VERSION ""

NS_ :

BS_:

BU_: HCM IPMA_ADAS PSCM GWM _delete SCCM PDM DDM GENERIC TSTR

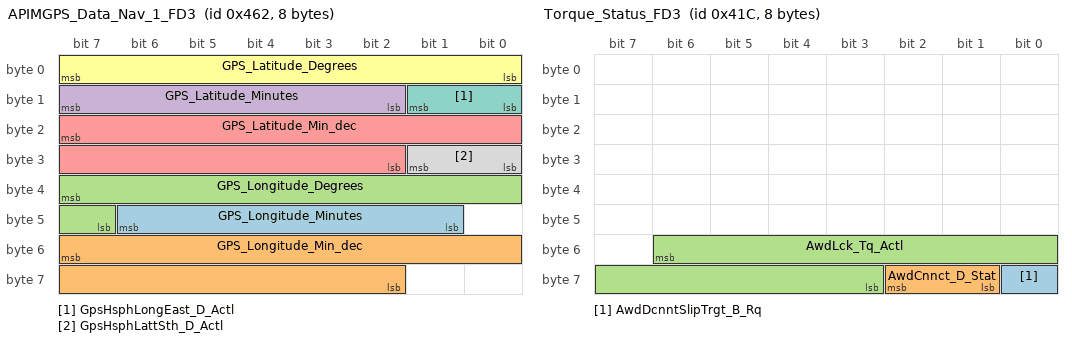
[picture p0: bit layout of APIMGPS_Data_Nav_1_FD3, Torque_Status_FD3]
BO_ 1122 APIMGPS_Data_Nav_1_FD3: 8 GWM
 SG_ GPS_Longitude_Minutes : 46|6@0+ (1,0) [0|61] "minute" Vector__XXX
 SG_ GPS_Longitude_Min_dec : 55|14@0+ (0.0001,0) [0|1.6381] "minute" Vector__XXX
 SG_ GPS_Longitude_Degrees : 39|9@0+ (1,-179) [-179|330] "degrees" Vector__XXX
 SG_ GPS_Latitude_Minutes : 15|6@0+ (1,0) [0|61] "minute" Vector__XXX
 SG_ GPS_Latitude_Min_dec : 23|14@0+ (0.0001,0) [0|1.6381] "minute" Vector__XXX
 SG_ GPS_Latitude_Degrees : 7|8@0+ (1,-89) [-89|164] "degrees" Vector__XXX
 SG_ GpsHsphLongEast_D_Actl : 9|2@0+ (1,0) [0|3] "SED" Vector__XXX
 SG_ GpsHsphLattSth_D_Actl : 25|2@0+ (1,0) [0|3] "SED" Vector__XXX

BO_ 2611175457 PARSEDPhysIPMAtoGWM_ECG: 64 IPMA_ADAS
 SG_ PARSEDPhysIPMAtoGWM_ECG : 7|29@0+ (1,0) [0|536870911] "unitless"  GWM

BO_ 2609933528 OTAPhysGWM_ECGtoGSM: 64 GWM
 SG_ OTAPhysGWM_ECGtoGSM : 7|29@0+ (1,0) [0|536870911] "unitless" Vector__XXX

BO_ 2611175492 PARSEDPhysSCCMtoGWM_ECG: 64 SCCM
 SG_ PARSEDPhysSCCMtoGWM_ECG : 7|29@0+ (1,0) [0|536870911] "unitless"  GWM

BO_ 1054 BrakeSysFeatures_3_FD3: 16 GWM
 SG_ RbaBrk_D_Stat : 63|2@0+ (1,0) [0|3] "SED"  IPMA_ADAS
 SG_ SelDrvMdeChassis2_D_Rq : 45|5@0+ (1,0) [0|31] "SED"  PSCM
 SG_ TrailCtl_D_Stat : 55|3@0+ (1,0) [0|7] "SED" Vector__XXX
 SG_ TrailCtlMsgTxt_D_Rq : 52|4@0+ (1,0) [0|15] "SED" Vector__XXX
 SG_ BrkBstrVac_D_Stat : 18|2@0+ (1,0) [0|3] "SED" Vector__XXX
 SG_ DrvSlipCtlOffLamp_D_Rq : 23|2@0+ (1,0) [0|3] "SED" Vector__XXX
 SG_ DrvSlipCtlMdeMsg_D_Rq : 13|5@0+ (1,0) [0|31] "SED" Vector__XXX
 SG_ HdcOn_B_Ind : 16|1@0+ (1,0) [0|1] "SED" Vector__XXX
 SG_ AutoHoldMsgTxt_D_Rq : 4|4@0+ (1,0) [0|15] "SED" Vector__XXX
 SG_ CtaBrk_D_Stat : 47|2@0+ (1,0) [0|3] "SED"  IPMA_ADAS
 SG_ SelDrvMdeAwd_D_Rq : 29|5@0+ (1,0) [0|31] "SED" Vector__XXX
 SG_ AutoHoldSwMde_B_Ind : 0|1@0+ (1,0) [0|1] "SED" Vector__XXX
 SG_ AutoHoldMde_D_Ind : 15|2@0+ (1,0) [0|3] "SED" Vector__XXX
 SG_ SelDrvMdeChassis_D_Rq : 39|5@0+ (1,0) [0|31] "SED" Vector__XXX
 SG_ ApaBrk_D_Stat : 34|2@0+ (1,0) [0|3] "SED"  IPMA_ADAS

BO_ 1052 Torque_Status_FD3: 8 GWM
 SG_ AwdDcnntSlipTrgt_B_Rq : 56|1@0+ (1,0) [0|1] "SED" Vector__XXX
 SG_ AwdCnnct_D_Stat : 58|2@0+ (1,0) [0|3] "SED" Vector__XXX
 SG_ AwdLck_Tq_Actl : 54|12@0+ (1,0) [0|4093] "Nm" Vector__XXX

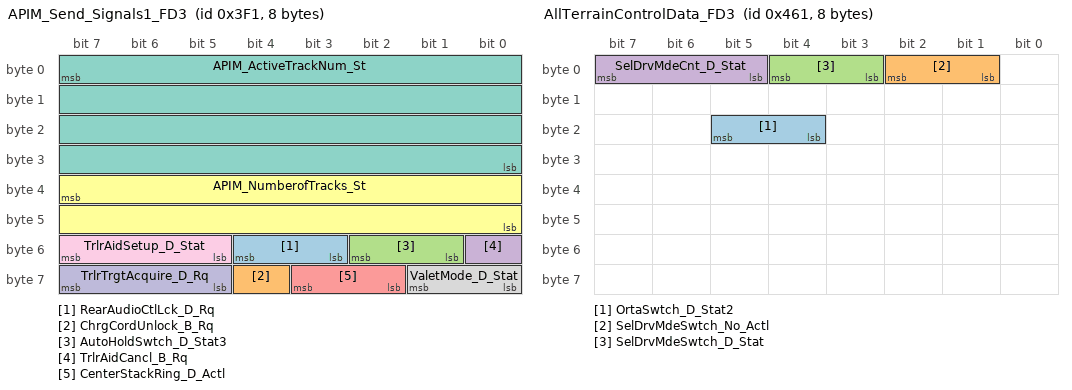
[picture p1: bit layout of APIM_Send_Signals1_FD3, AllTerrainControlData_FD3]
BO_ 1009 APIM_Send_Signals1_FD3: 8 GWM
 SG_ RearAudioCtlLck_D_Rq : 52|2@0+ (1,0) [0|3] "SED" Vector__XXX
 SG_ ChrgCordUnlock_B_Rq : 60|1@0+ (1,0) [0|1] "SED" Vector__XXX
 SG_ AutoHoldSwtch_D_Stat3 : 50|2@0+ (1,0) [0|3] "SED" Vector__XXX
 SG_ TrlrAidCancl_B_Rq : 48|1@0+ (1,0) [0|1] "SED"  PSCM,IPMA_ADAS
 SG_ CenterStackRing_D_Actl : 59|2@0+ (1,0) [0|3] "SED" Vector__XXX
 SG_ APIM_NumberofTracks_St : 39|16@0+ (1,0) [0|65535] "unitless" Vector__XXX
 SG_ APIM_ActiveTrackNum_St : 7|32@0+ (1,0) [0|4294967295] "unitless" Vector__XXX
 SG_ ValetMode_D_Stat : 57|2@0+ (1,0) [0|3] "SED" Vector__XXX
 SG_ TrlrAidSetup_D_Stat : 55|3@0+ (1,0) [0|7] "SED" Vector__XXX
 SG_ TrlrTrgtAcquire_D_Rq : 63|3@0+ (1,0) [0|7] "SED" Vector__XXX

BO_ 1121 AllTerrainControlData_FD3: 8 GWM
 SG_ OrtaSwtch_D_Stat2 : 21|2@0+ (1,0) [0|3] "SED"  _delete
 SG_ SelDrvMdeSwtch_No_Actl : 2|2@0+ (1,0) [0|3] "unitless" Vector__XXX
 SG_ SelDrvMdeSwtch_D_Stat : 4|2@0+ (1,0) [0|3] "SED" Vector__XXX
 SG_ SelDrvMdeCnt_D_Stat : 7|3@0+ (1,0) [0|7] "Counts" Vector__XXX

BO_ 972 Lane_Assist_Data3: 16 PSCM
 SG_ TrlrAn_An_TrgtCalc : 31|8@0+ (1,-128) [-128|127] "degrees"  IPMA_ADAS,GWM
 SG_ LaActAvail_D2_Actl : 5|2@0+ (1,0) [0|3] "SED"  IPMA_ADAS,GWM
 SG_ LsmcBrkDecelEnbl_D_Rq : 1|2@0+ (1,0) [0|3] "SED"  GWM
 SG_ TjaHandsOnCnfdnc_B_Est : 3|1@0+ (1,0) [0|1] "SED"  IPMA_ADAS,GWM
 SG_ LaHandsOff_B_Actl : 7|1@0+ (1,0) [0|1] "SED"  IPMA_ADAS,GWM
 SG_ LaActDeny_B_Actl : 6|1@0+ (1,0) [0|1] "SED"  IPMA_ADAS,GWM
 SG_ LsmcBrk_Tq_Rq : 15|13@0+ (4,0) [0|32764] "Nm"  GWM
 SG_ LatCtlSte_D_Stat : 18|3@0+ (1,0) [0|7] "SED"  IPMA_ADAS,GWM
 SG_ LatCtlLim_D_Stat : 33|2@0+ (1,0) [0|3] "SED"  IPMA_ADAS,GWM
 SG_ LatCtlCpbltyDStat_No_Cs : 47|8@0+ (1,0) [0|255] "unitless"  IPMA_ADAS,GWM
 SG_ LatCtlCpbltyDStat_No_Cnt : 37|4@0+ (1,0) [0|15] "unitless"  IPMA_ADAS,GWM
 SG_ LatCtlCpblty_D_Stat : 39|2@0+ (1,0) [0|3] "SED"  IPMA_ADAS,GWM

BO_ 930 Bndry_Alert_R_Data: 16 IPMA_ADAS
 SG_ BalrWndwRight_B_Stat : 19|1@0+ (1,0) [0|1] "SED"  GWM
 SG_ BalrSnsRight_D_Falt : 21|2@0+ (1,0) [0|3] "SED"  GWM
 SG_ WndwPsngrRear_D_RqBalrr : 25|2@0+ (1,0) [0|3] "SED"  GWM
 SG_ WndwPsngr_D_RqBalrr : 27|2@0+ (1,0) [0|3] "SED"  GWM
 SG_ WndwDrvRear_D_RqBalrr : 29|2@0+ (1,0) [0|3] "SED"  GWM
 SG_ WndwDrv_D_RqBalrr : 31|2@0+ (1,0) [0|3] "SED"  GWM
 SG_ BalrRight_D_Stat : 10|2@0+ (1,0) [0|3] "SED"  GWM
 SG_ BalrMdeSelRight_B_Stat : 8|1@0+ (1,0) [0|1] "SED"  GWM
 SG_ BalrMdeRight_D_Stat : 23|2@0+ (1,0) [0|3] "SED"  GWM
 SG_ BalrLckRight_B_Stat : 11|1@0+ (1,0) [0|1] "SED"  GWM
 SG_ BalrChimeRight_D_Rq : 2|2@0+ (1,0) [0|3] "SED"  GWM
 SG_ CamraRearOn_B_RqBalrr : 7|1@0+ (1,0) [0|1] "SED"  GWM
 SG_ DrLckCnt_No_ActlBalrr : 5|3@0+ (1,0) [0|7] "unitless"  GWM
 SG_ DrLckActv_B_RqBalrr : 6|1@0+ (1,0) [0|1] "SED"  GWM

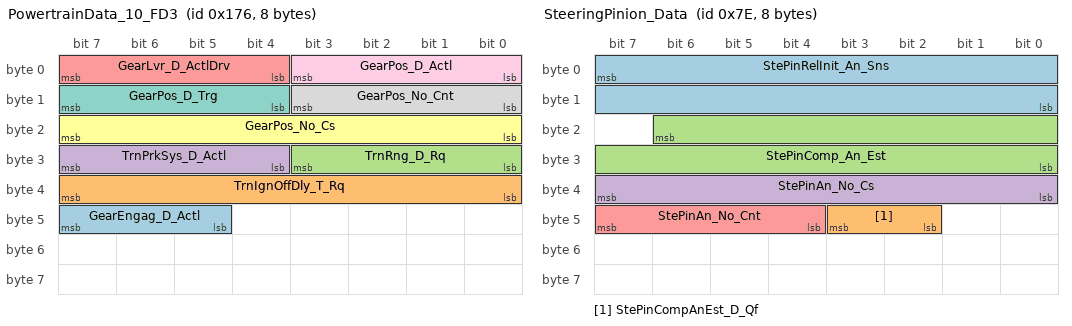
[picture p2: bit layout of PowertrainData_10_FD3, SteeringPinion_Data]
BO_ 374 PowertrainData_10_FD3: 8 GWM
 SG_ GearEngag_D_Actl : 47|3@0+ (1,0) [0|7] "SED"  _delete
 SG_ TrnIgnOffDly_T_Rq : 39|8@0+ (4,0) [0|1020] "ms"  _delete
 SG_ TrnRng_D_Rq : 27|4@0+ (1,0) [0|15] "SED"  IPMA_ADAS,PSCM
 SG_ TrnPrkSys_D_Actl : 31|4@0+ (1,0) [0|15] "SED"  IPMA_ADAS
 SG_ GearLvr_D_ActlDrv : 7|4@0+ (1,0) [0|15] "SED"  IPMA_ADAS
 SG_ GearPos_No_Cs : 23|8@0+ (1,0) [0|255] "unitless"  IPMA_ADAS
 SG_ GearPos_D_Trg : 15|4@0+ (1,0) [0|15] "SED"  HCM,IPMA_ADAS
 SG_ GearPos_No_Cnt : 11|4@0+ (1,0) [0|15] "unitless"  IPMA_ADAS
 SG_ GearPos_D_Actl : 3|4@0+ (1,0) [0|15] "SED"  IPMA_ADAS,PSCM

BO_ 359 VehicleOperatingModes_FD3: 16 GWM
 SG_ ElPw_D_StatStrtStop : 31|4@0+ (1,0) [0|15] "SED" Vector__XXX
 SG_ TrnAin_Tq_Actl : 42|11@0+ (1,-500) [-500|1547] "Nm" Vector__XXX
 SG_ PrplWhlTot2_Tq_Actl : 15|16@0+ (4,-131072) [-131072|131060] "Nm"  PSCM
 SG_ PwPckTq_D_Stat : 5|2@0+ (1,0) [0|3] "SED"  SCCM,PDM,DDM,HCM,IPMA_ADAS,PSCM
 SG_ Eng_D_Stat : 7|2@0+ (1,0) [0|3] "SED" Vector__XXX
 SG_ ElPw_D_Stat : 3|3@0+ (1,0) [0|7] "SED"  PDM,DDM,HCM,IPMA_ADAS,PSCM
 SG_ TrnAinTq_D_Qf : 44|2@0+ (1,0) [0|3] "SED" Vector__XXX

BO_ 357 EngBrakeData_FD3: 16 GWM
 SG_ CcMde_D_Actl : 13|3@0+ (1,0) [0|7] "SED"  _delete
 SG_ BPedDrvAppl_D_Qf : 15|2@0+ (1,0) [0|3] "SED"  IPMA_ADAS,PSCM
 SG_ CmbbDeny_B_ActlPrpl : 3|1@0+ (1,0) [0|1] "SED"  IPMA_ADAS
 SG_ PrplTqMnSat_B_Actl : 41|1@0+ (1,0) [0|1] "SED"  IPMA_ADAS
 SG_ BpedDrvAppl_D_Actl : 5|2@0+ (1,0) [0|3] "SED"  PSCM,IPMA_ADAS
 SG_ CmbbEngTqMn_B_Actl : 7|1@0+ (1,0) [0|1] "SED"  IPMA_ADAS
 SG_ Veh_V_DsplyCcSet : 23|8@0+ (1,0) [0|253] "unitless"  IPMA_ADAS
 SG_ AccEngStat_D_Actl : 2|3@0+ (1,0) [0|7] "SED"  IPMA_ADAS
 SG_ CcStat_D_Actl : 10|3@0+ (1,0) [0|7] "SED"  IPMA_ADAS
 SG_ CcOvrrdActv_B_Actl : 6|1@0+ (1,0) [0|1] "SED"  IPMA_ADAS
 SG_ AccStopMde_D_Rq : 39|2@0+ (1,0) [0|3] "SED"  IPMA_ADAS

BO_ 934 Side_Detect_L_Stat: 16 IPMA_ADAS
 SG_ CtaAlrtLeft2_D_Stat : 30|3@0+ (1,0) [0|7] "SED"  GWM
 SG_ CtaBrkLeftMsgTxt_B_Rq : 42|1@0+ (1,0) [0|1] "SED"  GWM
 SG_ CtaLeftBrkDecel_B_Rq : 7|1@0+ (1,0) [0|1] "SED"  GWM
 SG_ CtaLeftBrkEnbl_B_Rq : 31|1@0+ (1,0) [0|1] "SED"  GWM
 SG_ Side_Detect_L_Illum : 39|8@0+ (1,0) [0|255] "Percent"  PDM,DDM,GWM
 SG_ BttLeft_D_Stat : 45|3@0+ (1,0) [0|7] "SED"  GWM
 SG_ BttLeft_D_RqDrv : 47|2@0+ (1,0) [0|3] "SED"  GWM
 SG_ CtaSnsLeft_D_Stat : 25|2@0+ (1,0) [0|3] "SED"  GWM
 SG_ SodDetctLeft_D_Stat : 23|3@0+ (1,0) [0|7] "SED"  GWM
 SG_ CtaLeft_D_Stat : 18|3@0+ (1,0) [0|7] "SED"  GWM
 SG_ CtaAlrtLeft_D_Stat : 8|1@0+ (1,0) [0|1] "SED"  PDM,DDM,GWM
 SG_ SodLeft_D_Stat : 15|3@0+ (1,0) [0|7] "SED"  GWM
 SG_ SodSnsLeft_D_Stat : 12|2@0+ (1,0) [0|3] "SED"  PDM,DDM,GWM
 SG_ SodAlrtLeft_D_Stat : 10|2@0+ (1,0) [0|3] "SED"  PDM,DDM,GWM
 SG_ SodWarnLeft_Prd_Rq : 6|7@0+ (1,0) [0|127] "millisecond"  PDM,DDM,GWM

BO_ 929 Bndry_Alert_L_Data: 16 IPMA_ADAS
 SG_ BalrChimeLeft_D_Rq : 2|2@0+ (1,0) [0|3] "SED"  GWM
 SG_ BalrLeft_D_Stat : 10|2@0+ (1,0) [0|3] "SED"  GWM
 SG_ WndwPsngrRear_D_RqBalrl : 25|2@0+ (1,0) [0|3] "SED"  GWM
 SG_ WndwPsngr_D_RqBalrl : 27|2@0+ (1,0) [0|3] "SED"  GWM
 SG_ WndwDrvRear_D_RqBalrl : 29|2@0+ (1,0) [0|3] "SED"  GWM
 SG_ WndwDrv_D_RqBalrl : 31|2@0+ (1,0) [0|3] "SED"  GWM
 SG_ BalrSnsLeft_D_Falt : 21|2@0+ (1,0) [0|3] "SED"  GWM
 SG_ BalrMdeSelLeft_B_Stat : 8|1@0+ (1,0) [0|1] "SED"  GWM
 SG_ BalrMdeLeft_D_Stat : 23|2@0+ (1,0) [0|3] "SED"  GWM
 SG_ BalrLckLeft_B_Stat : 11|1@0+ (1,0) [0|1] "SED"  GWM
 SG_ CamraRearOn_B_RqBalrl : 7|1@0+ (1,0) [0|1] "SED"  GWM
 SG_ DrLckCnt_No_ActlBalrl : 5|3@0+ (1,0) [0|7] "unitless"  GWM
 SG_ DrLckActv_B_RqBalrl : 6|1@0+ (1,0) [0|1] "SED"  GWM
 SG_ BalrWndwLeft_B_Stat : 19|1@0+ (1,0) [0|1] "SED"  GWM

BO_ 126 SteeringPinion_Data: 8 PSCM
 SG_ StePinRelInit_An_Sns : 7|16@0+ (0.1,-3200) [-3200|3353.3] "degrees"  IPMA_ADAS,GWM
 SG_ StePinCompAnEst_D_Qf : 43|2@0+ (1,0) [0|3] "SED"  HCM,GWM,IPMA_ADAS
 SG_ StePinComp_An_Est : 22|15@0+ (0.1,-1600) [-1600|1676.7] "degrees"  HCM,IPMA_ADAS,GWM
 SG_ StePinAn_No_Cs : 39|8@0+ (1,0) [0|255] "unitless"  GWM
 SG_ StePinAn_No_Cnt : 47|4@0+ (1,0) [0|15] "unitless"  GWM

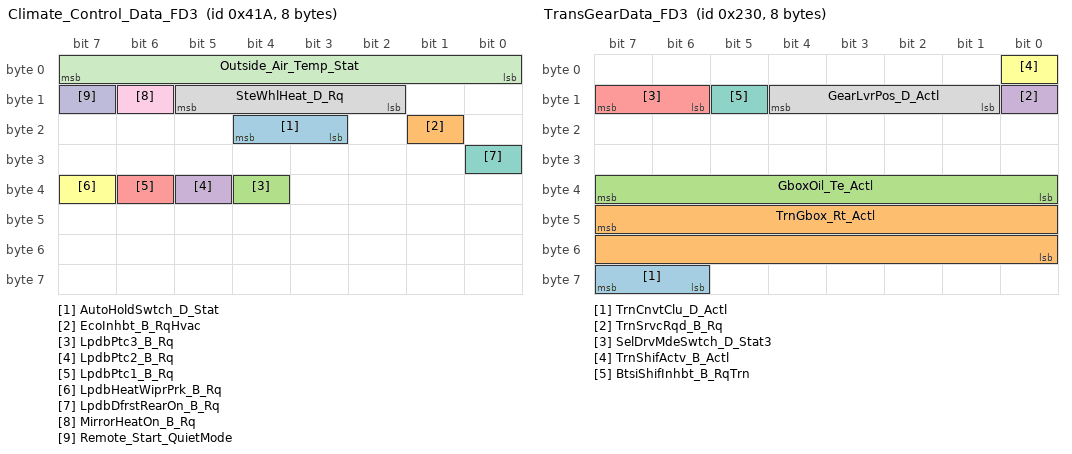
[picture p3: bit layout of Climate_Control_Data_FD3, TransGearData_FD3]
BO_ 1050 Climate_Control_Data_FD3: 8 GWM
 SG_ AutoHoldSwtch_D_Stat : 20|2@0+ (1,0) [0|3] "SED" Vector__XXX
 SG_ EcoInhbt_B_RqHvac : 17|1@0+ (1,0) [0|1] "SED" Vector__XXX
 SG_ LpdbPtc3_B_Rq : 36|1@0+ (1,0) [0|1] "SED" Vector__XXX
 SG_ LpdbPtc2_B_Rq : 37|1@0+ (1,0) [0|1] "SED" Vector__XXX
 SG_ LpdbPtc1_B_Rq : 38|1@0+ (1,0) [0|1] "SED" Vector__XXX
 SG_ LpdbHeatWiprPrk_B_Rq : 39|1@0+ (1,0) [0|1] "SED" Vector__XXX
 SG_ LpdbDfrstRearOn_B_Rq : 24|1@0+ (1,0) [0|1] "SED" Vector__XXX
 SG_ SteWhlHeat_D_Rq : 13|4@0+ (1,0) [0|15] "SED"  SCCM
 SG_ MirrorHeatOn_B_Rq : 14|1@0+ (1,0) [0|1] "SED"  DDM,PDM
 SG_ Remote_Start_QuietMode : 15|1@0+ (1,0) [0|1] "SED" Vector__XXX
 SG_ Outside_Air_Temp_Stat : 7|8@0+ (0.5,-40) [-40|86.5] "degC"  DDM,PDM,PSCM,IPMA_ADAS

BO_ 1045 BrakeSysFeatures_FD3: 16 GWM
 SG_ VehStab_D_Stat : 55|4@0+ (1,0) [0|15] "SED"  HCM
 SG_ BrkFluidLvl_D_Stat : 17|2@0+ (1,0) [0|3] "SED" Vector__XXX
 SG_ LsmcBrkDecel_D_Stat : 39|3@0+ (1,0) [0|7] "SED"  PSCM
 SG_ VehYawNonLin_W_Rq : 51|12@0+ (0.03663,-75) [-75|74.92659] "deg/s" Vector__XXX
 SG_ VehYawLin_W_Rq : 35|12@0+ (0.03663,-75) [-75|74.92659] "deg/s" Vector__XXX
 SG_ VehVActlBrk_No_Cs : 31|8@0+ (1,0) [0|255] "unitless"  PSCM,IPMA_ADAS
 SG_ Veh_V_ActlBrk : 7|16@0+ (0.01,0) [0|655.35] "kph"  SCCM,PSCM,IPMA_ADAS
 SG_ VehVActlBrk_No_Cnt : 21|4@0+ (1,0) [0|15] "unitless"  PSCM,IPMA_ADAS
 SG_ VehVActlBrk_D_Qf : 23|2@0+ (1,0) [0|3] "SED"  SCCM,PSCM,IPMA_ADAS

BO_ 1044 BrakeSnData_6_FD3: 16 GWM
 SG_ ApaBrkErrDStat_No_Cnt : 55|4@0+ (1,0) [0|15] "Unitless" Vector__XXX
 SG_ ApaBrkErrDStat_No_Cs : 47|8@0+ (1,0) [0|255] "Unitless" Vector__XXX
 SG_ ApaBrkErr_D_Stat : 17|2@0+ (1,0) [0|3] "SED" Vector__XXX
 SG_ StePinOffst_An_Est : 7|16@0+ (0.1,-3200) [-3200|3353.3] "degrees"  SCCM,PSCM
 SG_ StePinOffst_No_Cs : 31|8@0+ (1,0) [0|255] "unitless"  SCCM,PSCM
 SG_ StePinOffst_No_Cnt : 21|4@0+ (1,0) [0|15] "unitless"  SCCM,PSCM
 SG_ StePinOffst_D_Stat : 23|2@0+ (1,0) [0|3] "SED"  SCCM,PSCM

BO_ 765 Mc_Send_Signals_2_FD3: 8 GWM
 SG_ Running_Board_Cmd : 21|2@0+ (1,0) [0|3] "SED"  _delete
 SG_ BalrSwtch_D_Stat : 57|2@0+ (1,0) [0|3] "SED"  IPMA_ADAS
 SG_ BalrMde_D_Rq : 59|2@0+ (1,0) [0|3] "SED"  IPMA_ADAS
 SG_ RstrnOnPsngr_D_RqMnu : 63|4@0+ (1,0) [0|15] "SED" Vector__XXX
 SG_ WaitToStartLamp_D_Falt : 50|2@0+ (1,0) [0|3] "SED" Vector__XXX
 SG_ EsaOn_B_Rq : 15|1@0+ (1,0) [0|1] "SED"  PSCM
 SG_ BttOn_B_Rq : 26|1@0+ (1,0) [0|1] "SED"  IPMA_ADAS
 SG_ Btt_L_Actl : 39|7@0+ (0.1,0) [0|12.5] "meter"  IPMA_ADAS
 SG_ SelDrvMdeTxtReset_B_Rq : 40|1@0+ (1,0) [0|1] "SED" Vector__XXX
 SG_ DrvInputRequired_B_Rq : 32|1@0+ (1,0) [0|1] "SED"  SCCM
 SG_ SelDrvMdeDsply_B_Avail : 41|1@0+ (1,0) [0|1] "SED" Vector__XXX
 SG_ Mc_VehUntTrpCoUsrSel_St : 23|1@0+ (1,0) [0|1] "SED" Vector__XXX
 SG_ Mc_VehUnitTempUsrSel_St : 22|1@0+ (1,0) [0|1] "SED" Vector__XXX
 SG_ Mc_VehTimeFrmtUsrSel_St : 1|2@0+ (1,0) [0|3] "SED" Vector__XXX
 SG_ Mc_VehLangUsrSel_St : 7|6@0+ (1,0) [0|63] "SED" Vector__XXX
 SG_ AwdRnge_D_ActlIpc : 29|3@0+ (1,0) [0|7] "SED" Vector__XXX
 SG_ EdmSailMde_B_RqDrv : 48|1@0+ (1,0) [0|1] "SED" Vector__XXX

BO_ 560 TransGearData_FD3: 8 GWM
 SG_ TrnCnvtClu_D_Actl : 63|2@0+ (1,0) [0|3] "SED"  _delete
 SG_ TrnGbox_Rt_Actl : 47|16@0+ (0.001,0) [0|65.533] "unitless"  _delete
 SG_ GboxOil_Te_Actl : 39|8@0+ (1,-60) [-60|193] "degC"  _delete
 SG_ TrnSrvcRqd_B_Rq : 8|1@0+ (1,0) [0|1] "SED"  _delete
 SG_ SelDrvMdeSwtch_D_Stat3 : 15|2@0+ (1,0) [0|3] "SED"  _delete
 SG_ TrnShifActv_B_Actl : 0|1@0+ (1,0) [0|1] "SED"  _delete
 SG_ BtsiShifInhbt_B_RqTrn : 13|1@0+ (1,0) [0|1] "SED" Vector__XXX
 SG_ GearLvrPos_D_Actl : 12|4@0+ (1,0) [0|15] "SED"  SCCM,PDM,DDM,HCM,PSCM,IPMA_ADAS

BO_ 559 ElecHorizon_Data2_FD3: 8 GWM
 SG_ EhData2_No_Actl : 7|64@0+ (1,0) [0|1.84467440737096E+019] "unitless"  HCM,IPMA_ADAS

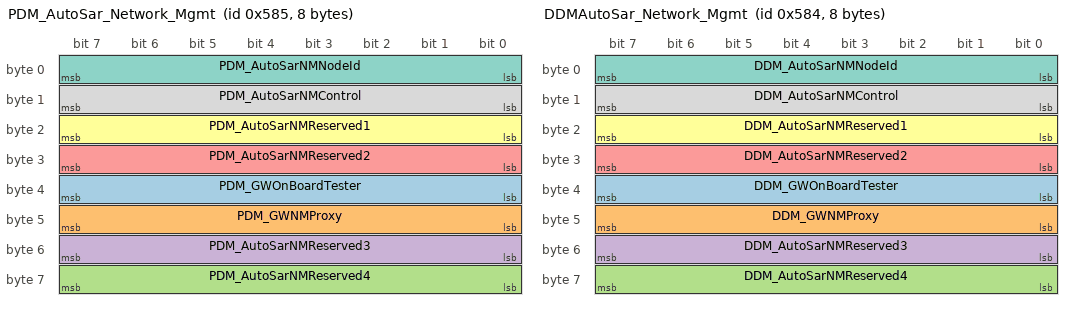
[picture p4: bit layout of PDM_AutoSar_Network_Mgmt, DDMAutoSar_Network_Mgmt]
BO_ 1413 PDM_AutoSar_Network_Mgmt: 8 PDM
 SG_ PDM_GWOnBoardTester : 39|8@0+ (1,0) [0|255] "unitless"  GENERIC
 SG_ PDM_GWNMProxy : 47|8@0+ (1,0) [0|255] "unitless"  GENERIC
 SG_ PDM_AutoSarNMReserved4 : 63|8@0+ (1,0) [0|255] "unitless"  GENERIC
 SG_ PDM_AutoSarNMReserved3 : 55|8@0+ (1,0) [0|255] "unitless"  GENERIC
 SG_ PDM_AutoSarNMReserved2 : 31|8@0+ (1,0) [0|255] "unitless"  GENERIC
 SG_ PDM_AutoSarNMReserved1 : 23|8@0+ (1,0) [0|255] "unitless"  GENERIC
 SG_ PDM_AutoSarNMNodeId : 7|8@0+ (1,0) [0|255] "unitless"  GENERIC
 SG_ PDM_AutoSarNMControl : 15|8@0+ (1,0) [0|255] "unitless"  GENERIC

BO_ 1412 DDMAutoSar_Network_Mgmt: 8 DDM
 SG_ DDM_GWOnBoardTester : 39|8@0+ (1,0) [0|255] "unitless"  GENERIC
 SG_ DDM_GWNMProxy : 47|8@0+ (1,0) [0|255] "unitless"  GENERIC
 SG_ DDM_AutoSarNMReserved4 : 63|8@0+ (1,0) [0|255] "unitless"  GENERIC
 SG_ DDM_AutoSarNMReserved3 : 55|8@0+ (1,0) [0|255] "unitless"  GENERIC
 SG_ DDM_AutoSarNMReserved2 : 31|8@0+ (1,0) [0|255] "unitless"  GENERIC
 SG_ DDM_AutoSarNMReserved1 : 23|8@0+ (1,0) [0|255] "unitless"  GENERIC
 SG_ DDM_AutoSarNMNodeId : 7|8@0+ (1,0) [0|255] "unitless"  GENERIC
 SG_ DDM_AutoSarNMControl : 15|8@0+ (1,0) [0|255] "unitless"  GENERIC

BO_ 1822 TesterPhysicalResGWM_FD3: 64 GWM
 SG_ TesterPhysicalResGWM_F3 : 7|64@0+ (1,0) [0|1.84467E+019] "unitless"  TSTR

BO_ 1878 TesterPhysicalReqPBM: 64 TSTR
 SG_ TesterPhysicalReqPBM : 7|64@0+ (1,0) [0|1.84467E+019] "unitless" Vector__XXX

BO_ 2610097368 OTAPhysGWM_ECGtoCMR: 64 GWM
 SG_ OTAPhysGWM_ECGtoCMR : 7|29@0+ (1,0) [0|536870911] "unitless" Vector__XXX

BO_ 1778 TesterPhysicalReqSODCMC: 64 TSTR
 SG_ TesterPhysicalReqSODCMC : 7|64@0+ (1,0) [0|1.84467E+019] "unitless"  IPMA_ADAS

BO_ 551 APIM_Request_Signals_1_FD3: 8 GWM
 SG_ VehPerfDemo_B_RqDrv : 8|1@0+ (1,0) [0|1] "SED" Vector__XXX
 SG_ PrkBrkPerfMnuOn_D_Stat : 1|2@0+ (1,0) [0|3] "SED" Vector__XXX
 SG_ PrkBrkPerfButtn_D_Stat : 3|2@0+ (1,0) [0|3] "SED" Vector__XXX
 SG_ EcoIdl_D_Rq : 7|2@0+ (1,0) [0|3] "SED" Vector__XXX
 SG_ GoTElementEdit_No_RqMnu : 12|4@0+ (1,0) [0|15] "unitless" Vector__XXX
 SG_ OneTEditActv_B_RqMnu : 40|1@0+ (1,0) [0|1] "SED" Vector__XXX
 SG_ PrcondEdit_D_RqMnu : 15|3@0+ (1,0) [0|7] "SED" Vector__XXX
 SG_ BattTracLoThres_D_Rq : 43|3@0+ (1,0) [0|7] "SED" Vector__XXX
 SG_ ChrgToPcEdit_Pc_RqMnu : 23|7@0+ (1,0) [0|125] "percent" Vector__XXX
 SG_ Cntr_Plg_Mode_Cmd : 39|1@0+ (1,0) [0|1] "SED" Vector__XXX
 SG_ Btt_L_Actl2 : 55|7@0+ (0.1,0) [0|12.5] "meter"  IPMA_ADAS
 SG_ PwRnngBoardT_D_Rq : 25|2@0+ (1,0) [0|3] "SED" Vector__XXX
 SG_ PwRnngBoardMde_D_Rq : 29|2@0+ (1,0) [0|3] "SED" Vector__XXX
 SG_ PwRnngBoardSwtch_D_Rq : 27|2@0+ (1,0) [0|3] "SED" Vector__XXX
 SG_ Rba_D_Rq : 31|2@0+ (1,0) [0|3] "SED"  IPMA_ADAS
 SG_ EmPrflNo_D_Rq : 61|3@0+ (1,0) [0|7] "SED"  DDM
 SG_ EmPrflButtnAssoc_D_Rq : 33|2@0+ (1,0) [0|3] "SED" Vector__XXX
 SG_ EmPrflKeyAssoc_D_Rq : 46|3@0+ (1,0) [0|7] "SED"  DDM
 SG_ Em_D_Stat : 63|2@0+ (1,0) [0|3] "SED" Vector__XXX
 SG_ PmCabnLvl_D_Stat : 36|3@0+ (1,0) [0|7] "SED"  GENERIC
 SG_ PmCabn_D_Stat : 38|2@0+ (1,0) [0|3] "SED"  GENERIC
 SG_ ChrgCrdLckEnbl_B_Stat : 47|1@0+ (1,0) [0|1] "SED" Vector__XXX
 SG_ ChrgOvrdExitScrn_D_Rq : 58|2@0+ (1,0) [0|3] "SED" Vector__XXX
 SG_ TjaLaneBiasEnbl_D_RqMnu : 5|2@0+ (1,0) [0|3] "SED"  IPMA_ADAS

BO_ 358 Stop_Start_FD3: 16 GWM
 SG_ StopStrtStdby_D_Indic : 55|3@0+ (1,0) [0|7] "SED" Vector__XXX
 SG_ StopStrtIODTxt_D_Rq : 52|5@0+ (1,0) [0|31] "SED" Vector__XXX
 SG_ StopStrtDrvMde_D_Indic : 13|2@0+ (1,0) [0|3] "SED" Vector__XXX
 SG_ StopStrtMsgTxt_D_Rq : 11|4@0+ (1,0) [0|15] "SED" Vector__XXX
 SG_ OdoTripVerify_L_Actl : 31|24@0+ (0.1,0) [0|1677721.4] "km" Vector__XXX
 SG_ HiElPwInhbt_B_Stat : 15|1@0+ (1,0) [0|1] "SED"  DDM,PDM
 SG_ AutoStopPtDelta_I_Est : 7|8@0+ (1,-127) [-127|127] "Amps" Vector__XXX

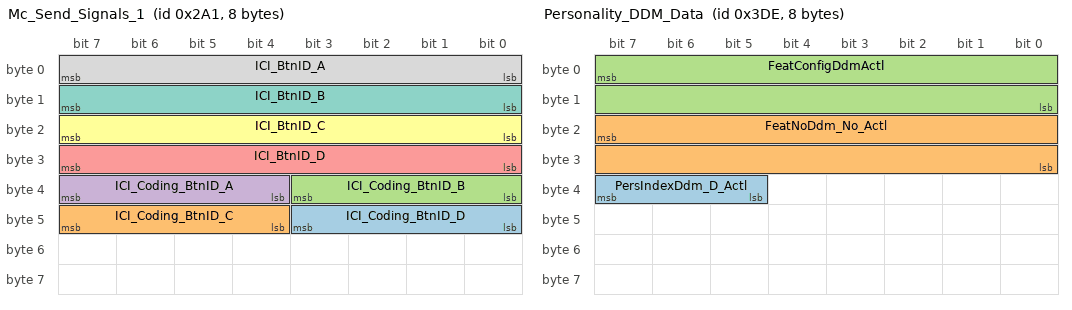
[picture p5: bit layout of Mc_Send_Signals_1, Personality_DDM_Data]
BO_ 673 Mc_Send_Signals_1: 8 SCCM
 SG_ ICI_Coding_BtnID_D : 43|4@0+ (1,0) [0|15] "SED"  GWM
 SG_ ICI_Coding_BtnID_C : 47|4@0+ (1,0) [0|15] "SED"  GWM
 SG_ ICI_Coding_BtnID_B : 35|4@0+ (1,0) [0|15] "SED"  GWM
 SG_ ICI_Coding_BtnID_A : 39|4@0+ (1,0) [0|15] "SED"  GWM
 SG_ ICI_BtnID_D : 31|8@0+ (1,0) [0|255] "unitless"  GWM
 SG_ ICI_BtnID_C : 23|8@0+ (1,0) [0|255] "unitless"  GWM
 SG_ ICI_BtnID_B : 15|8@0+ (1,0) [0|255] "unitless"  GWM
 SG_ ICI_BtnID_A : 7|8@0+ (1,0) [0|255] "unitless"  GWM

BO_ 990 Personality_DDM_Data: 8 DDM
 SG_ PersIndexDdm_D_Actl : 39|3@0+ (1,0) [0|7] "SED"  GWM
 SG_ FeatNoDdm_No_Actl : 23|16@0+ (1,0) [0|65535] "Number"  GWM
 SG_ FeatConfigDdmActl : 7|16@0+ (1,0) [0|65535] "Undefined"  GWM

BO_ 1100 PowertrainData_9_FD3: 16 GWM
 SG_ WakeAlarm1_T_Rq : 55|15@0+ (1,0) [0|32767] "minute" Vector__XXX
 SG_ WakeAlarm1_B_Typ : 56|1@0+ (1,0) [0|1] "SED" Vector__XXX
 SG_ TrnNtrlIdlExit_B_Rq : 38|1@0+ (1,0) [0|1] "SED" Vector__XXX
 SG_ Veh_V_DsplyTrailCtlSet : 47|6@0+ (0.5,0) [0|31] "unitless" Vector__XXX
 SG_ TrailCtlPt_B_Falt : 36|2@0+ (1,0) [0|3] "SED" Vector__XXX
 SG_ TrnNtrlIdlInhbt_B_Rq : 37|1@0+ (1,0) [0|1] "SED" Vector__XXX
 SG_ GrossTrainWeight_M_Est : 7|8@0+ (100,0) [0|25300] "kilogram"  PSCM,IPMA_ADAS
 SG_ HvacCmprLim_D_Stat : 34|3@0+ (1,0) [0|7] "SED" Vector__XXX

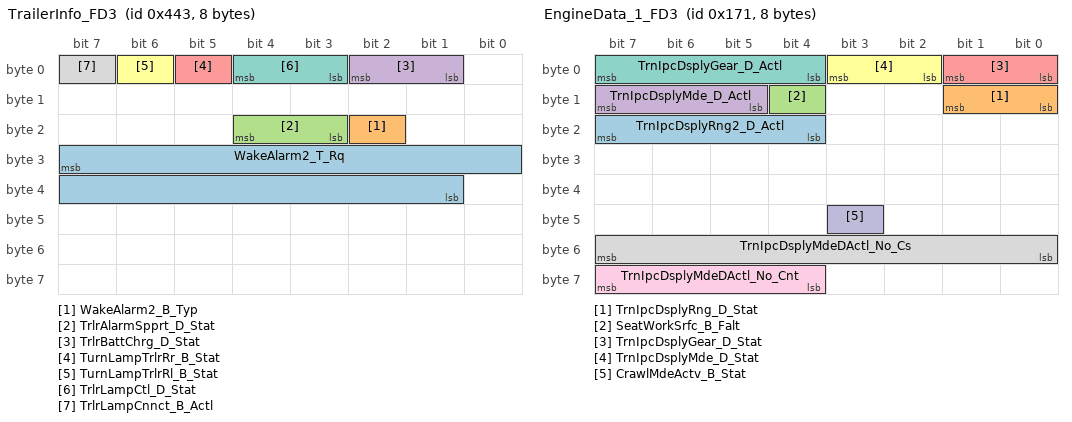
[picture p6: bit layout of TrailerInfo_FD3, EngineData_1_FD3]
BO_ 1091 TrailerInfo_FD3: 8 GWM
 SG_ WakeAlarm2_T_Rq : 31|15@0+ (1,0) [0|32767] "minute"  _delete
 SG_ WakeAlarm2_B_Typ : 18|1@0+ (1,0) [0|1] "SED"  _delete
 SG_ TrlrAlarmSpprt_D_Stat : 20|2@0+ (1,0) [0|3] "SED"  _delete
 SG_ TrlrBattChrg_D_Stat : 2|2@0+ (1,0) [0|3] "SED"  _delete
 SG_ TurnLampTrlrRr_B_Stat : 5|1@0+ (1,0) [0|1] "SED"  _delete
 SG_ TurnLampTrlrRl_B_Stat : 6|1@0+ (1,0) [0|1] "SED"  _delete
 SG_ TrlrLampCtl_D_Stat : 4|2@0+ (1,0) [0|3] "SED" Vector__XXX
 SG_ TrlrLampCnnct_B_Actl : 7|1@0+ (1,0) [0|1] "SED"  SCCM,PSCM,IPMA_ADAS

BO_ 819 Pass_Dr_Stat: 16 PDM
 SG_ WndwPsngrSide_D_Stat : 4|2@0+ (1,0) [0|3] "SED"  GWM
 SG_ BLISLEDStatPassSide : 2|2@0+ (1,0) [0|3] "SED"  GWM,IPMA_ADAS
 SG_ RollCode_No_ActlPdm : 31|16@0+ (1,0) [0|65535] "unitless"  GWM
 SG_ Pasngr_Lock_Sw_Stat : 6|2@0+ (1,0) [0|3] "SED"  GWM
 SG_ Pasngr_Lock_Sw_Cnt : 15|8@0+ (1,0) [0|255] "Cnt"  GWM
 SG_ ChildLckFdbckRp_B_Stat : 7|1@0+ (1,0) [0|1] "SED"  GWM

BO_ 818 Driver_Dr_Stat: 16 DDM
 SG_ DrvSpotLight_B_Stat : 40|1@0+ (1,0) [0|1] "SED"  GWM,PDM
 SG_ WndwDrvSide_D_Stat : 1|2@0+ (1,0) [0|3] "SED"  GWM
 SG_ RvrseMirrorChime_B_Rq : 45|1@0+ (1,0) [0|1] "SED"  GWM
 SG_ BLISLEDStatDriverSide : 47|2@0+ (1,0) [0|3] "SED"  GWM,IPMA_ADAS
 SG_ ChildLckPw_N_Cnt : 39|8@0+ (1,0) [0|255] "unitless"  GWM
 SG_ RollCodeDrvDrKeyCyl : 23|16@0+ (1,0) [0|65535] "unitless"  GWM
 SG_ KeyCylSwDrvDr_D_Stat : 3|2@0+ (1,0) [0|3] "SED"  GWM
 SG_ Driver_Lock_Sw_Stat : 5|2@0+ (1,0) [0|3] "SED"  GWM
 SG_ Driver_Lock_Sw_Cnt : 15|8@0+ (1,0) [0|255] "Cnt"  GWM
 SG_ ChildLckPw_D_Rq : 6|1@0+ (1,0) [0|1] "SED"  GWM
 SG_ ChildLckFdbckRd_B_Stat : 7|1@0+ (1,0) [0|1] "SED"  GWM

BO_ 1865 TesterPhysicalResPDM: 64 PDM
 SG_ TesterPhysicalResPDM : 7|64@0+ (1,0) [0|1.84467E+019] "unitless"  TSTR

BO_ 1857 TesterPhysicalReqPDM: 64 TSTR
 SG_ TesterPhysicalReqPDM : 7|64@0+ (1,0) [0|1.84467E+019] "unitless"  PDM

BO_ 1046 BrakeSysFeatures_2_FD3: 16 GWM
 SG_ TRLR_SWAY_EVNT_IN_PROG : 25|1@0+ (1,0) [0|1] "SED" Vector__XXX
 SG_ TRLR_SWAY_CONFIG_STAT : 26|1@0+ (1,0) [0|1] "SED" Vector__XXX
 SG_ HsaMde_D_Mem : 33|2@0+ (1,0) [0|3] "SED" Vector__XXX
 SG_ BrkBstrVac_B_Rq : 27|1@0+ (1,0) [0|1] "Discrete" Vector__XXX
 SG_ DrvSlipCtlMde_D_Ind : 44|2@0+ (1,0) [0|3] "SED"  IPMA_ADAS
 SG_ DrvAntiLckLamp_D_Rq : 55|2@0+ (1,0) [0|3] "SED"  IPMA_ADAS
 SG_ StabCtlBrk_B_Avail : 4|1@0+ (1,0) [0|1] "SED" Vector__XXX
 SG_ DrvHdcWarnInfo_D_Rq : 35|2@0+ (1,0) [0|3] "SED" Vector__XXX
 SG_ DrvHdcMsg_D_Rq : 10|3@0+ (1,0) [0|7] "SED" Vector__XXX
 SG_ DrvHdcLampInfo_D_Rq : 12|2@0+ (1,0) [0|3] "SED" Vector__XXX
 SG_ ChimeBrk_B_Rq : 14|1@0+ (1,0) [0|1] "SED" Vector__XXX
 SG_ BrkLamp_B_Rq : 13|1@0+ (1,0) [0|1] "SED" Vector__XXX
 SG_ HILL_DESC_MC : 47|3@0+ (1,0) [0|7] "SED" Vector__XXX
 SG_ RearDiffLck_Tq2_RqMx : 51|12@0+ (4,0) [0|16376] "Nm" Vector__XXX
 SG_ HdcMde_D_Actl : 31|3@0+ (1,0) [0|7] "SED" Vector__XXX
 SG_ TCMode : 15|1@0+ (1,0) [0|1] "SED"  IPMA_ADAS
 SG_ DrvSlipCtlLamp_D_Rq : 42|2@0+ (1,0) [0|3] "SED"  IPMA_ADAS
 SG_ Abs_B_Falt : 5|1@0+ (1,0) [0|1] "SED" Vector__XXX
 SG_ BpedMove_No_Cnt : 3|4@0+ (1,0) [0|15] "unitless" Vector__XXX
 SG_ BpedMove_D_Actl : 7|2@0+ (1,0) [0|3] "SED" Vector__XXX
 SG_ RearDiffElckrOpen_B_Rq : 40|1@0+ (1,0) [0|1] "SED" Vector__XXX

BO_ 342 EngineData_6_FD3: 16 GWM
 SG_ EngClntTe_D_Qf : 33|2@0+ (1,0) [0|3] "SED"  _delete
 SG_ EngOvrhtMitgActv_D_Ind : 36|2@0+ (1,0) [0|3] "SED"  _delete
 SG_ EngOil_Te_Actl : 15|8@0+ (1,-60) [-60|193] "degC"  _delete
 SG_ EngClnt_Te_Actl : 7|8@0+ (1,-60) [-60|195] "degC"  _delete
 SG_ FuelRange_L2_DsplyEng : 47|15@0+ (0.1,0) [0|3276.7] "kilometer" Vector__XXX
 SG_ EngTeColdPrtct_B_Rq : 16|1@0+ (1,0) [0|1] "SED" Vector__XXX

BO_ 369 EngineData_1_FD3: 8 GWM
 SG_ TrnIpcDsplyRng2_D_Actl : 23|4@0+ (1,0) [0|15] "SED"  _delete
 SG_ TrnIpcDsplyRng_D_Stat : 9|2@0+ (1,0) [0|3] "SED"  _delete
 SG_ SeatWorkSrfc_B_Falt : 12|1@0+ (1,0) [0|1] "SED"  _delete
 SG_ TrnIpcDsplyMde_D_Actl : 15|3@0+ (1,0) [0|7] "SED"  _delete
 SG_ TrnIpcDsplyGear_D_Stat : 1|2@0+ (1,0) [0|3] "SED"  _delete
 SG_ TrnIpcDsplyMde_D_Stat : 3|2@0+ (1,0) [0|3] "SED"  _delete
 SG_ TrnIpcDsplyGear_D_Actl : 7|4@0+ (1,0) [0|15] "SED"  _delete
 SG_ TrnIpcDsplyMdeDActl_No_Cs : 55|8@0+ (1,0) [0|255] "Unitless" Vector__XXX
 SG_ TrnIpcDsplyMdeDActl_No_Cnt : 63|4@0+ (1,0) [0|15] "Unitless" Vector__XXX
 SG_ CrawlMdeActv_B_Stat : 43|1@0+ (1,0) [0|1] "SED" Vector__XXX

BO_ 1842 TesterPhysicalReqGSM: 64 TSTR
 SG_ TesterPhysicalReqGSM : 7|64@0+ (1,0) [0|1.84467E+019] "unitless" Vector__XXX

BO_ 2612002008 PARSEDFuncGWM_ECG_FD3: 64 GWM
 SG_ PARSEDFuncGWM_ECG : 7|29@0+ (1,0) [0|536870911] "unitless"  PSCM,DDM,PDM,IPMA_ADAS,HCM,SCCM

BO_ 2610953432 OTAFuncGWM_ECG_FD3: 64 GWM
 SG_ OTAFuncGWM_ECG : 7|29@0+ (1,0) [0|536870911] "unitless"  DDM,PDM,HCM,SCCM,IPMA_ADAS

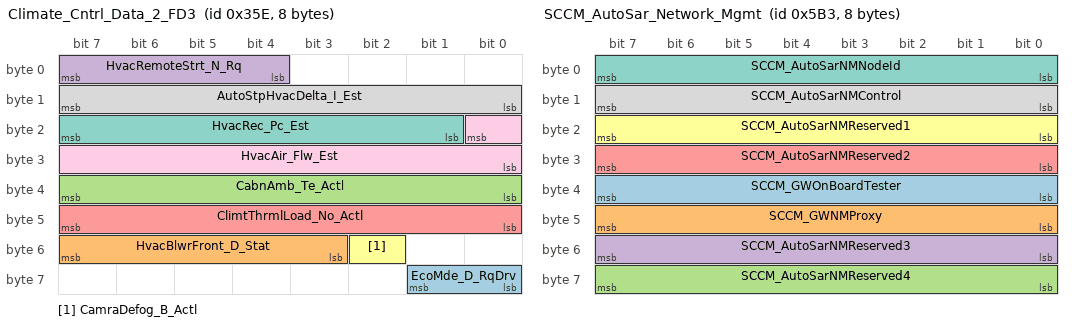
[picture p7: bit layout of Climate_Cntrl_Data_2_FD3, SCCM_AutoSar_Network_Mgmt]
BO_ 862 Climate_Cntrl_Data_2_FD3: 8 GWM
 SG_ EcoMde_D_RqDrv : 57|2@0+ (1,0) [0|3] "SED" Vector__XXX
 SG_ HvacBlwrFront_D_Stat : 55|5@0+ (1,0) [0|31] "SED" Vector__XXX
 SG_ CabnAmb_Te_Actl : 39|8@0+ (0.5,-57) [-57|70] "degC" Vector__XXX
 SG_ HvacRemoteStrt_N_Rq : 7|4@0+ (100,450) [450|1950] "RPM" Vector__XXX
 SG_ ClimtThrmlLoad_No_Actl : 47|8@0+ (1,0) [0|254] "unitless" Vector__XXX
 SG_ CamraDefog_B_Actl : 50|1@0+ (1,0) [0|1] "SED" Vector__XXX
 SG_ HvacRec_Pc_Est : 23|7@0+ (1,0) [0|127] "percent" Vector__XXX
 SG_ AutoStpHvacDelta_I_Est : 15|8@0+ (1,-192) [-192|62] "ampere" Vector__XXX
 SG_ HvacAir_Flw_Est : 16|9@0+ (0.5,0) [0|255.5] "liter/second" Vector__XXX

BO_ 1459 SCCM_AutoSar_Network_Mgmt: 8 SCCM
 SG_ SCCM_GWOnBoardTester : 39|8@0+ (1,0) [0|255] "unitless"  GENERIC
 SG_ SCCM_GWNMProxy : 47|8@0+ (1,0) [0|255] "unitless"  GENERIC
 SG_ SCCM_AutoSarNMReserved4 : 63|8@0+ (1,0) [0|255] "unitless"  GENERIC
 SG_ SCCM_AutoSarNMReserved3 : 55|8@0+ (1,0) [0|255] "unitless"  GENERIC
 SG_ SCCM_AutoSarNMReserved2 : 31|8@0+ (1,0) [0|255] "unitless"  GENERIC
 SG_ SCCM_AutoSarNMReserved1 : 23|8@0+ (1,0) [0|255] "unitless"  GENERIC
 SG_ SCCM_AutoSarNMNodeId : 7|8@0+ (1,0) [0|255] "unitless"  GENERIC
 SG_ SCCM_AutoSarNMControl : 15|8@0+ (1,0) [0|255] "unitless"  GENERIC

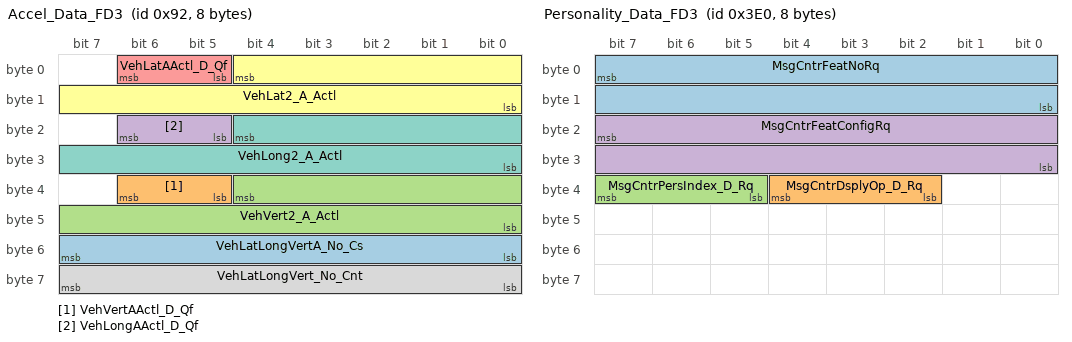
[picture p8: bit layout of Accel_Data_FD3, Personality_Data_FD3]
BO_ 146 Accel_Data_FD3: 8 GWM
 SG_ VehLatLongVertA_No_Cs : 55|8@0+ (1,0) [0|255] "unitless"  IPMA_ADAS,PSCM
 SG_ VehVertAActl_D_Qf : 38|2@0+ (1,0) [0|3] "SED"  IPMA_ADAS
 SG_ VehVert2_A_Actl : 36|13@0+ (0.01,-40) [-40|41.89] "m/s^2"  IPMA_ADAS
 SG_ VehLongAActl_D_Qf : 22|2@0+ (1,0) [0|3] "SED"  IPMA_ADAS
 SG_ VehLatAActl_D_Qf : 6|2@0+ (1,0) [0|3] "SED"  IPMA_ADAS,PSCM
 SG_ VehLat2_A_Actl : 4|13@0+ (0.01,-40) [-40|41.89] "m/s^2"  IPMA_ADAS,PSCM
 SG_ VehLong2_A_Actl : 20|13@0+ (0.01,-40) [-40|41.89] "m/s^2"  IPMA_ADAS
 SG_ VehLatLongVert_No_Cnt : 63|8@0+ (1,0) [0|255] "unitless"  IPMA_ADAS,PSCM

BO_ 1856 TesterPhysicalReqDDM: 64 TSTR
 SG_ TesterPhysicalReqDDM : 7|64@0+ (1,0) [0|1.84467E+019] "unitless"  DDM

BO_ 1864 TesterPhysicalResDDM: 64 DDM
 SG_ TesterPhysicalResDDM : 7|64@0+ (1,0) [0|1.84467E+019] "unitless"  TSTR

BO_ 992 Personality_Data_FD3: 8 GWM
 SG_ MsgCntrFeatNoRq : 7|16@0+ (1,0) [0|65535] "Number"  SCCM,DDM,PDM,HCM,IPMA_ADAS
 SG_ MsgCntrDsplyOp_D_Rq : 36|3@0+ (1,0) [0|7] "SED"  SCCM,DDM,PDM,HCM,IPMA_ADAS
 SG_ MsgCntrPersIndex_D_Rq : 39|3@0+ (1,0) [0|7] "SED"  SCCM,DDM,PDM,HCM,IPMA_ADAS
 SG_ MsgCntrFeatConfigRq : 23|16@0+ (1,0) [0|65535] "unitless"  SCCM,DDM,PDM,HCM,IPMA_ADAS

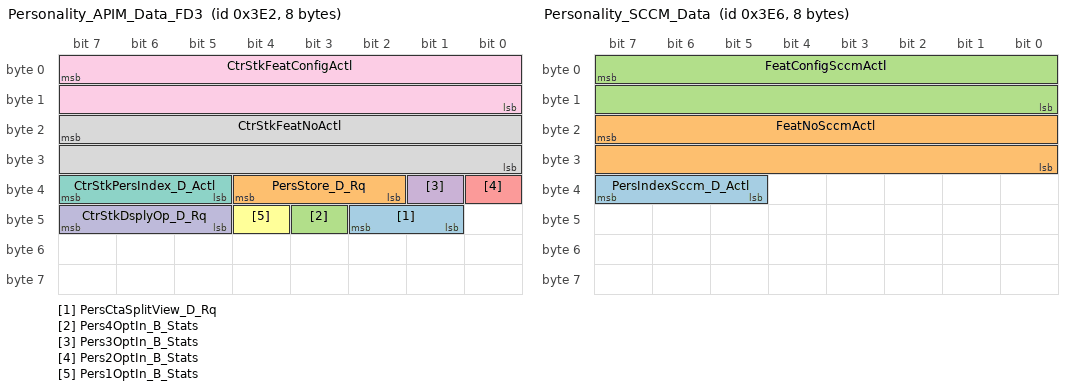
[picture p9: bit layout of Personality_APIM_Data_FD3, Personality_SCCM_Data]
BO_ 994 Personality_APIM_Data_FD3: 8 GWM
 SG_ PersCtaSplitView_D_Rq : 42|2@0+ (1,0) [0|3] "SED"  IPMA_ADAS
 SG_ PersStore_D_Rq : 36|3@0+ (1,0) [0|7] "SED"  DDM
 SG_ Pers4OptIn_B_Stats : 43|1@0+ (1,0) [0|1] "SED" Vector__XXX
 SG_ Pers3OptIn_B_Stats : 33|1@0+ (1,0) [0|1] "SED" Vector__XXX
 SG_ Pers2OptIn_B_Stats : 32|1@0+ (1,0) [0|1] "SED" Vector__XXX
 SG_ Pers1OptIn_B_Stats : 44|1@0+ (1,0) [0|1] "SED" Vector__XXX
 SG_ CtrStkPersIndex_D_Actl : 39|3@0+ (1,0) [0|7] "SED"  SCCM,DDM,PDM,HCM,IPMA_ADAS
 SG_ CtrStkFeatNoActl : 23|16@0+ (1,0) [0|65535] "Undefined"  SCCM,DDM,PDM,HCM,IPMA_ADAS
 SG_ CtrStkFeatConfigActl : 7|16@0+ (1,0) [0|65535] "Undefined"  SCCM,DDM,PDM,HCM,IPMA_ADAS
 SG_ CtrStkDsplyOp_D_Rq : 47|3@0+ (1,0) [0|7] "SED"  SCCM,DDM,PDM,HCM,IPMA_ADAS

BO_ 1836 TesterPhysicalResSCCM: 64 SCCM
 SG_ TesterPhysicalResSCCM : 7|64@0+ (1,0) [0|1.84467E+019] "unitless"  TSTR

BO_ 1828 TesterPhysicalReqSCCM: 64 TSTR
 SG_ TesterPhysicalReqSCCM : 7|64@0+ (1,0) [0|1.84467E+019] "unitless"  SCCM

BO_ 998 Personality_SCCM_Data: 8 SCCM
 SG_ PersIndexSccm_D_Actl : 39|3@0+ (1,0) [0|7] "SED"  GWM
 SG_ FeatNoSccmActl : 23|16@0+ (1,0) [0|65535] "Number"  GWM
 SG_ FeatConfigSccmActl : 7|16@0+ (1,0) [0|65535] "Undefined"  GWM

BO_ 1998 TesterPhysicalResSODR: 64 IPMA_ADAS
 SG_ TesterPhysicalResSODR : 7|64@0+ (1,0) [0|1.84467E+019] "unitless"  TSTR

BO_ 1990 TesterPhysicalReqSODR: 64 TSTR
 SG_ TesterPhysicalReqSODR : 7|64@0+ (1,0) [0|1.84467E+019] "unitless"  IPMA_ADAS

BO_ 1996 TesterPhysicalResSODL: 64 IPMA_ADAS
 SG_ TesterPhysicalResSODL : 7|64@0+ (1,0) [0|1.84467E+019] "unitless"  TSTR

BO_ 1988 TesterPhysicalReqSODL: 64 TSTR
 SG_ TesterPhysicalReqSODL : 7|64@0+ (1,0) [0|1.84467E+019] "unitless"  IPMA_ADAS

BO_ 828 Pass_Window_Stat: 16 PDM
 SG_ DrvSpotLight_B_Rq : 15|1@0+ (1,0) [0|1] "SED"  DDM,GWM
 SG_ SpotLghtRight_D_Stat : 0|1@0+ (1,0) [0|1] "SED"  GWM
 SG_ RearPassWindowPos : 4|3@0+ (1,0) [0|7] "SED"  GWM
 SG_ PassWindowPosition : 7|3@0+ (1,0) [0|7] "SED"  GWM
 SG_ SpotLghtLeft_D_Stat : 1|1@0+ (1,0) [0|1] "SED"  GWM

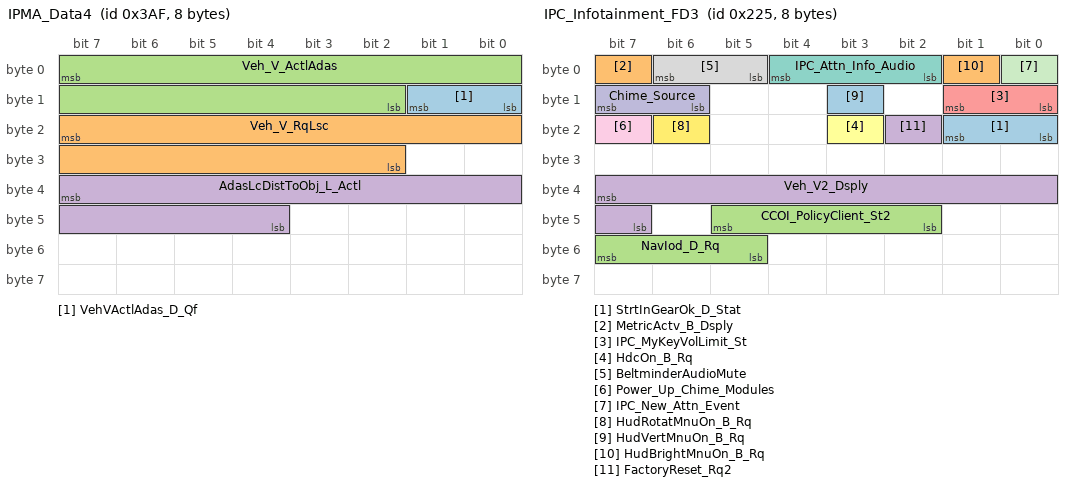
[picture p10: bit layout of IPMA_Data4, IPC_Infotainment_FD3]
BO_ 943 IPMA_Data4: 8 IPMA_ADAS
 SG_ VehVActlAdas_D_Qf : 9|2@0+ (1,0) [0|3] "SED"  GWM
 SG_ Veh_V_RqLsc : 23|14@0+ (0.01,0) [0|163.83] "kph"  GWM
 SG_ Veh_V_ActlAdas : 7|14@0+ (0.01,0) [0|163.83] "kph"  GWM
 SG_ AdasLcDistToObj_L_Actl : 39|12@0+ (0.002,0) [0|8.186] "meter"  GWM

BO_ 558 ElecHorizon_Data1_FD3: 8 GWM
 SG_ EhData1_No_Actl : 7|64@0+ (1,0) [0|1.84467440737096E+019] "unitless"  HCM,IPMA_ADAS

BO_ 549 IPC_Infotainment_FD3: 8 GWM
 SG_ StrtInGearOk_D_Stat : 17|2@0+ (1,0) [0|3] "SED"  _delete
 SG_ MetricActv_B_Dsply : 7|1@0+ (1,0) [0|1] "SED"  _delete
 SG_ NavIod_D_Rq : 55|3@0+ (1,0) [0|7] "SED" Vector__XXX
 SG_ Veh_V2_Dsply : 39|9@0+ (1,0) [0|511] "unitless"  IPMA_ADAS
 SG_ IPC_MyKeyVolLimit_St : 9|2@0+ (1,0) [0|3] "SED" Vector__XXX
 SG_ HdcOn_B_Rq : 19|1@0+ (1,0) [0|1] "SED" Vector__XXX
 SG_ IPC_Attn_Info_Audio : 4|3@0+ (1,0) [0|7] "SED" Vector__XXX
 SG_ BeltminderAudioMute : 6|2@0+ (1,0) [0|3] "SED" Vector__XXX
 SG_ Power_Up_Chime_Modules : 23|1@0+ (1,0) [0|1] "SED" Vector__XXX
 SG_ Chime_Source : 15|2@0+ (1,0) [0|3] "SED" Vector__XXX
 SG_ IPC_New_Attn_Event : 0|1@0+ (1,0) [0|1] "SED" Vector__XXX
 SG_ HudRotatMnuOn_B_Rq : 22|1@0+ (1,0) [0|1] "SED"  GENERIC
 SG_ HudVertMnuOn_B_Rq : 11|1@0+ (1,0) [0|1] "SED"  GENERIC
 SG_ HudBrightMnuOn_B_Rq : 1|1@0+ (1,0) [0|1] "SED"  GENERIC
 SG_ CCOI_PolicyClient_St2 : 45|4@0+ (1,0) [0|15] "SED" Vector__XXX
 SG_ FactoryReset_Rq2 : 18|1@0+ (1,0) [0|1] "SED" Vector__XXX

BO_ 2015 TesterFunctionalReq_FD3: 64 TSTR
 SG_ TesterFunctionalReq : 7|64@0+ (1,0) [0|1.84467E+019] "unitless"  SCCM,DDM,PDM,HCM,IPMA_ADAS,PSCM,GWM

BO_ 132 GlobalClock_Data_FD3: 16 GWM
 SG_ GlblClkYr_No_Actl : 7|8@0+ (1,2000) [2000|2255] "year"  IPMA_ADAS
 SG_ GlblClkScnd_No_Actl : 47|8@0+ (1,0) [0|255] "second"  IPMA_ADAS
 SG_ GlblClkMnte_No_Actl : 39|8@0+ (1,0) [0|255] "minute"  IPMA_ADAS
 SG_ GlblClkHr_No_Actl : 55|8@0+ (1,0) [0|255] "hour"  IPMA_ADAS
 SG_ GlblClkDay_No_Actl : 23|16@0+ (1,0) [0|65535] "julian day"  IPMA_ADAS

BO_ 947 BodyInfo_3_FD3: 16 GWM
 SG_ ValetMode_D_Mem : 16|1@0+ (1,0) [0|1] "SED" Vector__XXX
 SG_ DimmingLvlEvnt_No_Actl : 18|2@0+ (1,0) [0|3] "unitless" Vector__XXX
 SG_ DrStatDrvErrCnt_B_Stat : 19|1@0+ (1,0) [0|1] "SED" Vector__XXX
 SG_ TurnLghtRight_D_Rq : 63|2@0+ (1,0) [0|3] "SED"  SCCM,PDM,DDM,HCM,IPMA_ADAS
 SG_ TurnLghtRightOn_B_Stat : 35|1@0+ (1,0) [0|1] "SED" Vector__XXX
 SG_ TurnLghtLeftOn_B_Stat : 54|1@0+ (1,0) [0|1] "SED" Vector__XXX
 SG_ FogLghtRearOn_B_Stat : 1|1@0+ (1,0) [0|1] "SED"  HCM,IPMA_ADAS
 SG_ Backlit_LED_Status : 23|4@0+ (1,0) [0|15] "SED"  PDM,DDM
 SG_ TurnLghtLeft_D_Rq : 9|2@0+ (1,0) [0|3] "SED"  SCCM,PDM,DDM,HCM,IPMA_ADAS
 SG_ FogLghtFrontOn_B_Stat : 56|1@0+ (1,0) [0|1] "SED"  HCM,IPMA_ADAS
 SG_ IgnKeyType_D_Actl : 39|4@0+ (1,0) [0|15] "SED"  IPMA_ADAS
 SG_ Parklamp_Status : 3|2@0+ (1,0) [0|3] "SED"  PDM,DDM,HCM,IPMA_ADAS
 SG_ Litval : 47|8@0+ (1,0) [0|253] "SED"  SCCM,PDM,DDM,HCM,IPMA_ADAS
 SG_ Key_In_Ignition_Stat : 11|1@0+ (1,0) [0|1] "SED" Vector__XXX
 SG_ Ignition_Status : 7|4@0+ (1,0) [0|15] "SED"  SCCM,PDM,DDM,HCM,PSCM,IPMA_ADAS
 SG_ Dimming_Lvl : 31|8@0+ (1,0) [0|253] "SED"  SCCM,PDM,DDM,IPMA_ADAS
 SG_ Day_Night_Status : 15|2@0+ (1,0) [0|3] "SED"  PDM,DDM,IPMA_ADAS
 SG_ Remote_Start_Status : 13|2@0+ (1,0) [0|3] "SED"  IPMA_ADAS
 SG_ DrStatTgate_B_Actl : 0|1@0+ (1,0) [0|1] "SED"  PDM,DDM,IPMA_ADAS
 SG_ DrStatRr_B_Actl : 49|1@0+ (1,0) [0|1] "SED"  PDM,DDM,IPMA_ADAS
 SG_ DrStatRl_B_Actl : 48|1@0+ (1,0) [0|1] "SED"  PDM,DDM,IPMA_ADAS
 SG_ DrStatPsngr_B_Actl : 60|1@0+ (1,0) [0|1] "SED"  PDM,DDM,IPMA_ADAS
 SG_ DrStatInnrTgate_B_Actl : 58|1@0+ (1,0) [0|1] "SED"  SCCM,DDM,IPMA_ADAS
 SG_ DrStatHood_B_Actl : 59|1@0+ (1,0) [0|1] "SED" Vector__XXX
 SG_ DrStatDrv_B_Actl : 61|1@0+ (1,0) [0|1] "SED"  PDM,DDM,IPMA_ADAS
 SG_ PrkBrkActv_B_Actl : 55|1@0+ (1,0) [0|1] "SED"  PSCM,IPMA_ADAS
 SG_ LifeCycMde_D_Actl : 53|4@0+ (1,0) [0|15] "SED"  SCCM,PDM,DDM,HCM,PSCM,IPMA_ADAS
 SG_ Delay_Accy : 57|1@0+ (1,0) [0|1] "SED"  PDM,DDM
 SG_ CrashEvnt_D_Stat : 34|2@0+ (1,0) [0|3] "SED" Vector__XXX
 SG_ FuelPmpInhbt_B_Stat : 32|1@0+ (1,0) [0|1] "SED" Vector__XXX
 SG_ BodySrvcRqd_B_Rq : 10|1@0+ (1,0) [0|1] "SED" Vector__XXX

BO_ 1068 Battery_Mgmt_2_FD3: 16 GWM
 SG_ EngStrtInhbt_B_RqBatt : 2|1@0+ (1,0) [0|1] "SED" Vector__XXX
 SG_ BattULoChrg_D_Rq : 7|2@0+ (1,0) [0|3] "SED" Vector__XXX
 SG_ PwSysULoFalt_D_Stat : 12|4@0+ (1,0) [0|15] "SED"  PSCM
 SG_ Shed_T_Eng_Off_B : 8|1@0+ (1,0) [0|1] "SED"  SCCM
 SG_ Shed_Feature_Group_ID : 20|5@0+ (1,0) [0|31] "SED"  SCCM,IPMA_ADAS
 SG_ Shed_Drain_Eng_Off_B : 0|1@0+ (1,0) [0|1] "SED"  SCCM
 SG_ Shed_Level_Req : 23|3@0+ (1,0) [0|7] "SED"  SCCM,DDM,PDM,IPMA_ADAS
 SG_ BattULoSrvc_T_Actl : 39|12@0+ (1,0) [0|4095] "day" Vector__XXX
 SG_ Batt_Lo_SoC_B : 5|1@0+ (1,0) [0|1] "SED" Vector__XXX
 SG_ PeriodicElLoad_B_Stat : 1|1@0+ (1,0) [0|1] "SED" Vector__XXX
 SG_ Batt_Crit_SoC_B : 4|1@0+ (1,0) [0|1] "SED" Vector__XXX
 SG_ ULoRgenTestMde_B_Rq : 31|1@0+ (1,0) [0|1] "SED" Vector__XXX
 SG_ ChargeMode : 15|3@0+ (1,0) [0|7] "SED" Vector__XXX
 SG_ IdleSpeedIncrease_El : 3|1@0+ (1,0) [0|1] "SED" Vector__XXX

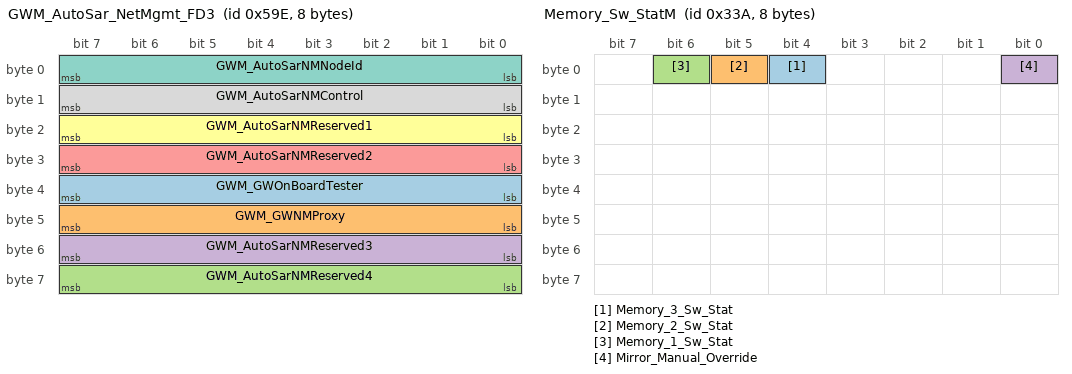
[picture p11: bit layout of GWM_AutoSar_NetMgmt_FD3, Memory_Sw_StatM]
BO_ 1438 GWM_AutoSar_NetMgmt_FD3: 8 GWM
 SG_ GWM_GWOnBoardTester : 39|8@0+ (1,0) [0|255] "unitless"  SCCM,PDM,DDM,PSCM
 SG_ GWM_GWNMProxy : 47|8@0+ (1,0) [0|255] "unitless"  SCCM,PDM,DDM,PSCM
 SG_ GWM_AutoSarNMReserved4 : 63|8@0+ (1,0) [0|255] "unitless"  SCCM,PDM,DDM,PSCM
 SG_ GWM_AutoSarNMReserved3 : 55|8@0+ (1,0) [0|255] "unitless"  SCCM,PDM,DDM,PSCM
 SG_ GWM_AutoSarNMReserved2 : 31|8@0+ (1,0) [0|255] "unitless"  SCCM,PDM,DDM,PSCM
 SG_ GWM_AutoSarNMReserved1 : 23|8@0+ (1,0) [0|255] "unitless"  SCCM,PDM,DDM,PSCM
 SG_ GWM_AutoSarNMNodeId : 7|8@0+ (1,0) [0|255] "unitless"  SCCM,PDM,DDM,PSCM
 SG_ GWM_AutoSarNMControl : 15|8@0+ (1,0) [0|255] "unitless"  SCCM,PDM,DDM,PSCM

BO_ 826 Memory_Sw_StatM: 8 DDM
 SG_ Memory_3_Sw_Stat : 4|1@0+ (1,0) [0|1] "SED"  GWM
 SG_ Memory_2_Sw_Stat : 5|1@0+ (1,0) [0|1] "SED"  GWM
 SG_ Memory_1_Sw_Stat : 6|1@0+ (1,0) [0|1] "SED"  GWM
 SG_ Mirror_Manual_Override : 0|1@0+ (1,0) [0|1] "SED"  GWM

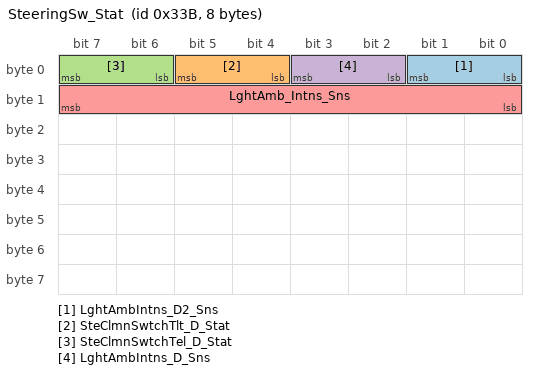
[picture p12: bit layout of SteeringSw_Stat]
BO_ 827 SteeringSw_Stat: 8 SCCM
 SG_ LghtAmbIntns_D2_Sns : 1|2@0+ (1,0) [0|3] "SED"  GWM
 SG_ SteClmnSwtchTlt_D_Stat : 5|2@0+ (1,0) [0|3] "SED"  GWM
 SG_ SteClmnSwtchTel_D_Stat : 7|2@0+ (1,0) [0|3] "SED"  GWM
 SG_ LghtAmbIntns_D_Sns : 3|2@0+ (1,0) [0|3] "SED"  GWM
 SG_ LghtAmb_Intns_Sns : 15|8@0+ (1,0) [0|255] "unitless"  GWM

BO_TX_BU_ 126 : SCCM,PSCM;
CM_ BO_ 1122 "HS3 APIM Sync Gen3 Tx 0x462.  FrameGateway to 0x465 on HS1, HS2, HS3 and MS1.";
CM_ BO_ 1009 "APIM Tx";
CM_ SG_ 1009 CenterStackRing_D_Actl "The Center Stack sends the CPLR a signal to turn On or Off the light Ring, This is a customer selectable preference switch";
CM_ SG_ 1009 APIM_NumberofTracks_St "Object NumberofTracks";
CM_ SG_ 1009 APIM_ActiveTrackNum_St "Object.ActiveTrackNum";
CM_ BO_ 374 "Programs w/o HS1 0x172 will need HS1 0x176 for GearPos_D_Actl.  Future MY Programs that choose c/o still require HS1 0x172. ";
CM_ SG_ 374 TrnRng_D_Rq "Powersplit HEVs with HF45, HPCM will Tx  this message.  For all other programs it will be Tx by PCM or TCM. ";
CM_ SG_ 374 TrnPrkSys_D_Actl "Powersplit HEVs with HF45, HPCM will Tx  this message.  For all other programs it will be Tx by PCM or TCM. ";
CM_ SG_ 374 GearLvr_D_ActlDrv "Powersplit HEVs with HF45, HPCM will Tx  this message.  For all other programs it will be Tx by PCM or TCM. ";
CM_ SG_ 374 GearPos_No_Cs "Powersplit HEVs with HF45, HPCM will Tx  this message.  For all other programs it will be Tx by PCM or TCM. ";
CM_ SG_ 374 GearPos_D_Trg "Powersplit HEVs with HF45, HPCM will Tx  this message.  For all other programs it will be Tx by PCM or TCM. ";
CM_ SG_ 374 GearPos_No_Cnt "Powersplit HEVs with HF45, HPCM will Tx  this message.  For all other programs it will be Tx by PCM or TCM. ";
CM_ SG_ 374 GearPos_D_Actl "Powersplit HEVs with HF45, HPCM will Tx  this message.  For all other programs it will be Tx by PCM or TCM. ";
CM_ SG_ 359 TrnAin_Tq_Actl "Signal not transmitted on HEV variances.";
CM_ SG_ 359 TrnAinTq_D_Qf "Signal not transmitted on HEV variances.";
CM_ SG_ 357 BpedDrvAppl_D_Actl "CCMGenSigTimeoutTime=1000";
CM_ SG_ 357 CcStat_D_Actl "ABSGenSigTimeoutTime=1000";
CM_ SG_ 357 AccStopMde_D_Rq "ABSGenSigTimeoutTime=1000";
CM_ SG_ 934 Side_Detect_L_Illum "DDMGenSigTimeoutTime=2000";
CM_ SG_ 934 SodLeft_D_Stat "IPCGenSigTimeoutTime=1600";
CM_ SG_ 934 SodSnsLeft_D_Stat "IPCGenSigTimeoutTime=1600";
CM_ SG_ 934 SodAlrtLeft_D_Stat "DDMGenSigTimeoutTime=2000";
CM_ SG_ 126 StePinRelInit_An_Sns "SASM will transmit these signals on vehicles with SASM and without PSCM.  SCCM will not Tx this signal when SASM is present.";
CM_ SG_ 126 StePinAn_No_Cs "Signal not transmitted on gas variants.";
CM_ SG_ 1050 Outside_Air_Temp_Stat "Filtered value, i.e. same as disply for customer";
CM_ SG_ 1044 StePinOffst_An_Est "SASM will transmit these signals on vehicles with SASM and without PSCM.  SCCM will not Tx this signal when SASM is present.";
CM_ SG_ 1044 StePinOffst_No_Cs "Signal not transmitted on gas variants.";
CM_ SG_ 765 Mc_VehUntTrpCoUsrSel_St "Object.VehicleSettings.Disp_Miles_Kilometers.Rq";
CM_ SG_ 765 Mc_VehUnitTempUsrSel_St "Object.VehicleSettings.Disp_Temperature.Rq";
CM_ SG_ 765 Mc_VehTimeFrmtUsrSel_St "Object.BodyInterface.Settings.VehicleTimeFormatUserSelection";
CM_ SG_ 765 Mc_VehLangUsrSel_St "Object.BodyInterface.Settings.VehicleLanguageUserSelection
Object Vehicle Settings.Disp_LangSel
";
CM_ BO_ 560 "MHT (U611/625) the HPCM will Rx 0x230 from the PCM_HEV
Powersplit FWD HEV’s (Cx482/3 430) the HPCM will Tx 0x230";
CM_ SG_ 560 TrnCnvtClu_D_Actl "Signal not transmitted on Gas & HEV variants. MHT(U611/625) HPCM Rx 0x230 from PCM_HEV. Powersplit FWD HEV’s(Cx482/3 430) HPCM Tx 0x230.";
CM_ SG_ 560 TrnGbox_Rt_Actl "Signal not transmitted on Gas & HEV variants. MHT(U611/625) HPCM Rx 0x230 from PCM_HEV. Powersplit FWD HEV’s(Cx482/3 430) HPCM Tx 0x230.";
CM_ SG_ 560 GboxOil_Te_Actl "Signal not transmitted on HEV variants. MHT(U611/625) HPCM Rx 0x230 from PCM_HEV. Powersplit FWD HEV’s(Cx482/3 430) HPCM Tx 0x230.";
CM_ SG_ 560 TrnSrvcRqd_B_Rq "Signal not transmitted on Diesel & HEV variants. MHT(U611/625) HPCM Rx 0x230 from PCM_HEV. Powersplit FWD HEV’s(Cx482/3 430) HPCM Tx 0x230.";
CM_ SG_ 560 SelDrvMdeSwtch_D_Stat3 "ECM_HEV does not support or Transmit signal.";
CM_ SG_ 560 TrnShifActv_B_Actl "Signal not transmitted on HEV variants. MHT(U611/625) HPCM Rx 0x230 from PCM_HEV. Powersplit FWD HEV’s(Cx482/3 430) HPCM Tx 0x230.";
CM_ BO_ 559 "APIM Tx";
CM_ SG_ 358 HiElPwInhbt_B_Stat "Signal not transmitted on HEV programs";
CM_ SG_ 358 AutoStopPtDelta_I_Est "Signal not transmitted on vehicles that do not have autostop/stop-start feature.";
CM_ BO_ 673 "Do not use this Frame for other Cluster Interaction";
CM_ SG_ 673 ICI_Coding_BtnID_D "Object InputControlInterface ICI ButtonCoding_D
(Parameter2)";
CM_ SG_ 673 ICI_Coding_BtnID_C "Object InputControlInterface ICI ButtonCoding_C
(Parameter2)";
CM_ SG_ 673 ICI_Coding_BtnID_B "Object InputControlInterface ICI ButtonCoding_B
(Parameter2)";
CM_ SG_ 673 ICI_Coding_BtnID_A "Object InputControlInterface ICI ButtonCoding_A
(Parameter2)";
CM_ SG_ 673 ICI_BtnID_D "Object InputControlInterface ICI ButtonID_D
(Parameter1)
for detailed Information refer to ICI Reference document";
CM_ SG_ 673 ICI_BtnID_C "Object InputControlInterface ICI ButtonID_C
(Parameter1)
for detailed Information refer to ICI Reference document";
CM_ SG_ 673 ICI_BtnID_B "Object InputControlInterface ICI ButtonID_B
(Parameter1)
for detailed Information refer to ICI Reference document";
CM_ SG_ 673 ICI_BtnID_A "Object InputControlInterface ICI ButtonID_A
(Parameter1)
for detailed Information refer to ICI Reference document";
CM_ SG_ 1046 DrvAntiLckLamp_D_Rq "update value table v8.34, not align w/GSDB, need etracker.  ABS & IPC implemented as updated.";
CM_ SG_ 1046 TCMode "Signal data set to 0x0 for ABS only vehicle option content";
CM_ SG_ 1046 BpedMove_D_Actl "CCMGenSigTimeoutTime=1000";
CM_ SG_ 342 EngOvrhtMitgActv_D_Ind "Signal not transmitted on diesel.";
CM_ SG_ 369 TrnIpcDsplyMdeDActl_No_Cs "Applies to Drag Mode on S550 Only.";
CM_ SG_ 369 TrnIpcDsplyMdeDActl_No_Cnt "Applies to Drag Mode on S550 Only.";
CM_ BO_ 828 "Set GenSigSendType = NoSigSendType (Cyclic) for the following signals, D.Card 3/31/08
Driver_Lock_Sw_Stat
";
CM_ BO_ 558 "APIM Tx";
CM_ BO_ 549 "Method IPC _Infotainment";
CM_ SG_ 549 BeltminderAudioMute "Object.MyKey.BeltMinderAudioMute.St";
CM_ SG_ 549 Power_Up_Chime_Modules "Object.AlertMethod.IPC _Infotainment";
CM_ SG_ 549 Chime_Source "Object.AlertMethod.IPC_infotainment";
CM_ BO_ 2015 "OBDII Request ($7DF) messages are for FNOS 1.0.1 only.
Diagnostic Functional Addressing ($7DF) and Dual Rate Periodic messages are for FNOS I3 only.";
CM_ SG_ 947 Dimming_Lvl "Refer to Vehicle Interior Illum Dimming Ctrl Sys Eng Spec, Table 2

";
CM_ SG_ 947 PrkBrkActv_B_Actl "Signal not transmitted on vehicles with electric park brake. ";
CM_ BO_ 827 "MSGDCR 000176 HUD_ADV requested EP 60ms.   ";
BA_DEF_ BO_  "VFrameFormat" ENUM  "StandardCAN","ExtendedCAN","reserved","reserved","reserved","reserved","reserved","reserved","reserved","reserved","reserved","reserved","reserved","reserved","StandardCAN_FD","ExtendedCAN_FD";
BA_DEF_ BO_  "FrameRouting" STRING ;
BA_DEF_ BO_  "NetworkInitialization" ENUM  "No","Yes";
BA_DEF_ BO_  "GenMsgStartDelayTime" INT 0 10000;
BA_DEF_ BO_  "GenMsgNrOfRepetition" INT 0 100;
BA_DEF_ BO_  "GenMsgDelayTime" INT 0 1000;
BA_DEF_ BO_  "GenMsgCycleTime" INT 0 100000;
BA_DEF_ BO_  "GenMsgSendType" ENUM  "FixedPeriodic","Event","EnabledPeriodic","NotUsed","NotUsed","EventPeriodic","NotUsed","NotUsed","NoMsgSendType";
BA_DEF_ SG_  "U_P702_MY2024_Tx" ENUM  "No","Yes";
BA_DEF_ SG_  "U_V710_MY2023_Tx" ENUM  "No","Yes";
BA_DEF_ SG_  "U_CDX74X_MY2024_Tx" ENUM  "No","Yes";
BA_DEF_ SG_  "U_P708_MY2023_Tx" ENUM  "No","Yes";
BA_DEF_ SG_  "U_V713AV_MY2022_Tx" ENUM  "No","Yes";
BA_DEF_ SG_  "U_V713N_MY2022_Tx" ENUM  "No","Yes";
BA_DEF_ SG_  "ECGUsedTxSignal" ENUM  "No","Yes";
BA_DEF_ SG_  "U_P702_MY2024_Rx" ENUM  "No","Yes";
BA_DEF_ SG_  "U_V710_MY2023_Rx" ENUM  "No","Yes";
BA_DEF_ SG_  "U_CDX74X_MY2024_Rx" ENUM  "No","Yes";
BA_DEF_ SG_  "U_CDX707_MY2023_Rx" ENUM  "No","Yes";
BA_DEF_ SG_  "U_P708_MY2023_Rx" ENUM  "No","Yes";
BA_DEF_ SG_  "U_V713N_MY2022_Rx" ENUM  "No","Yes";
BA_DEF_ SG_  "ECGUsedRxSignal" ENUM  "No","Yes";
BA_DEF_ SG_  "UsedOnPgmDBC" ENUM  "No","Yes";
BA_DEF_ SG_  "ContentDependant" ENUM  "No","Yes";
BA_DEF_ SG_  "GenSigStartValue" HEX 0 268435455;
BA_DEF_ SG_  "MetaData" ENUM  "No","Yes";
BA_DEF_ SG_  "WakeupSignal" ENUM  "No","Yes";
BA_DEF_ SG_  "GenSigInactiveValue" INT 0 100000;
BA_DEF_ SG_  "GenSigSendType" ENUM  "Cyclic","OnWrite","vector_leerstring","OnChange","vector_leerstring","IfActive","vector_leerstring","NoSigSendType";
BA_DEF_ BO_  "TpTxIndex" INT 0 536870911;
BA_DEF_ BO_  "OvtpPushApplication" ENUM  "FALSE","TRUE";
BA_DEF_ BO_  "SCP_FreshnessValueLength" INT 0 512;
BA_DEF_ BO_  "SCP_DataId" INT 0 17663;
BA_DEF_ BO_  "SCP_FreshnessValueTxLength" INT 0 512;
BA_DEF_ BO_  "SCP_AuthInfoTxLength" INT 0 512;
BA_DEF_ BO_  "SC_Message" ENUM  "No","Yes";
BA_DEF_ BO_  "GenMsgRoutingTimeoutTime" INT 0 5000;
BA_DEF_ BO_  "MessageGateway" ENUM  "No","Yes";
BA_DEF_ BO_  "NmAsrMessage" ENUM  "No","Yes";
BA_DEF_ BO_  "DiagState" ENUM  "No","Yes";
BA_DEF_ BO_  "DiagRequest" ENUM  "No","Yes";
BA_DEF_ BO_  "DiagResponse" ENUM  "No","Yes";
BA_DEF_ BO_  "GenMsgILSupport" ENUM  "No","Yes";
BA_DEF_REL_ BU_SG_REL_  "SC_Verification" ENUM  "No","Yes";
BA_DEF_DEF_  "VFrameFormat" "ExtendedCAN_FD";
BA_DEF_DEF_  "FrameRouting" "";
BA_DEF_DEF_  "NetworkInitialization" "Yes";
BA_DEF_DEF_  "GenMsgStartDelayTime" 0;
BA_DEF_DEF_  "GenMsgNrOfRepetition" 1;
BA_DEF_DEF_  "GenMsgDelayTime" 20;
BA_DEF_DEF_  "GenMsgCycleTime" 0;
BA_DEF_DEF_  "GenMsgSendType" "NoMsgSendType";
BA_DEF_DEF_  "U_P702_MY2024_Tx" "No";
BA_DEF_DEF_  "U_V710_MY2023_Tx" "No";
BA_DEF_DEF_  "U_CDX74X_MY2024_Tx" "No";
BA_DEF_DEF_  "U_P708_MY2023_Tx" "No";
BA_DEF_DEF_  "U_V713AV_MY2022_Tx" "No";
BA_DEF_DEF_  "U_V713N_MY2022_Tx" "No";
BA_DEF_DEF_  "ECGUsedTxSignal" "No";
BA_DEF_DEF_  "U_P702_MY2024_Rx" "No";
BA_DEF_DEF_  "U_V710_MY2023_Rx" "No";
BA_DEF_DEF_  "U_CDX74X_MY2024_Rx" "No";
BA_DEF_DEF_  "U_CDX707_MY2023_Rx" "No";
BA_DEF_DEF_  "U_P708_MY2023_Rx" "No";
BA_DEF_DEF_  "U_V713N_MY2022_Rx" "No";
BA_DEF_DEF_  "ECGUsedRxSignal" "No";
BA_DEF_DEF_  "UsedOnPgmDBC" "Yes";
BA_DEF_DEF_  "ContentDependant" "No";
BA_DEF_DEF_  "GenSigStartValue" 0;
BA_DEF_DEF_  "MetaData" "No";
BA_DEF_DEF_  "WakeupSignal" "No";
BA_DEF_DEF_  "GenSigInactiveValue" 0;
BA_DEF_DEF_  "GenSigSendType" "NoSigSendType";
BA_DEF_DEF_  "TpTxIndex" 0;
BA_DEF_DEF_  "OvtpPushApplication" "FALSE";
BA_DEF_DEF_  "SCP_FreshnessValueLength" 64;
BA_DEF_DEF_  "SCP_DataId" 0;
BA_DEF_DEF_  "SCP_FreshnessValueTxLength" 11;
BA_DEF_DEF_  "SCP_AuthInfoTxLength" 53;
BA_DEF_DEF_  "SC_Message" "No";
BA_DEF_DEF_  "GenMsgRoutingTimeoutTime" 0;
BA_DEF_DEF_  "MessageGateway" "No";
BA_DEF_DEF_  "NmAsrMessage" "No";
BA_DEF_DEF_  "DiagState" "No";
BA_DEF_DEF_  "DiagRequest" "No";
BA_DEF_DEF_  "DiagResponse" "No";
BA_DEF_DEF_  "GenMsgILSupport" "Yes";
BA_DEF_DEF_REL_ "SC_Verification" "No";
BA_ "FrameRouting" BO_ 1122 "HS3_CAN,0x462;";
BA_ "VFrameFormat" BO_ 1122 14;
BA_ "TpTxIndex" BO_ 2611175457 463504600;
BA_ "GenMsgSendType" BO_ 2611175457 1;
BA_ "GenMsgDelayTime" BO_ 2611175457 0;
BA_ "NetworkInitialization" BO_ 2611175457 0;
BA_ "TpTxIndex" BO_ 2609933528 462449880;
BA_ "GenMsgSendType" BO_ 2609933528 1;
BA_ "GenMsgDelayTime" BO_ 2609933528 0;
BA_ "NetworkInitialization" BO_ 2609933528 0;
BA_ "TpTxIndex" BO_ 2611175492 463540440;
BA_ "GenMsgSendType" BO_ 2611175492 1;
BA_ "GenMsgDelayTime" BO_ 2611175492 0;
BA_ "NetworkInitialization" BO_ 2611175492 0;
BA_ "FrameRouting" BO_ 1054 "FD1_CAN,0x41E;";
BA_ "SCP_DataId" BO_ 1054 5150;
BA_ "SC_Message" BO_ 1054 1;
BA_ "VFrameFormat" BO_ 1054 14;
BA_ "FrameRouting" BO_ 1052 "FD1_CAN,0x41C;";
BA_ "VFrameFormat" BO_ 1052 14;
BA_ "FrameRouting" BO_ 1009 "HS3_CAN,0x3F1;";
BA_ "VFrameFormat" BO_ 1009 14;
BA_ "FrameRouting" BO_ 1121 "HS2_CAN,0x461;";
BA_ "VFrameFormat" BO_ 1121 14;
BA_ "GenMsgSendType" BO_ 972 0;
BA_ "GenMsgCycleTime" BO_ 972 30;
BA_ "GenMsgDelayTime" BO_ 972 10;
BA_ "SCP_DataId" BO_ 972 5068;
BA_ "SC_Message" BO_ 972 1;
BA_ "VFrameFormat" BO_ 972 14;
BA_ "GenMsgSendType" BO_ 930 5;
BA_ "GenMsgCycleTime" BO_ 930 1000;
BA_ "SCP_DataId" BO_ 930 13218;
BA_ "SC_Message" BO_ 930 1;
BA_ "VFrameFormat" BO_ 930 14;
BA_ "FrameRouting" BO_ 374 "FD1_CAN,0x176;";
BA_ "VFrameFormat" BO_ 374 14;
BA_ "FrameRouting" BO_ 359 "FD1_CAN,0x167;";
BA_ "SCP_DataId" BO_ 359 4455;
BA_ "SC_Message" BO_ 359 1;
BA_ "VFrameFormat" BO_ 359 14;
BA_ "FrameRouting" BO_ 357 "FD1_CAN,0x165;";
BA_ "SCP_DataId" BO_ 357 4453;
BA_ "SC_Message" BO_ 357 1;
BA_ "VFrameFormat" BO_ 357 14;
BA_ "GenMsgSendType" BO_ 934 5;
BA_ "GenMsgCycleTime" BO_ 934 200;
BA_ "SCP_DataId" BO_ 934 5030;
BA_ "SC_Message" BO_ 934 1;
BA_ "VFrameFormat" BO_ 934 14;
BA_ "GenMsgSendType" BO_ 929 5;
BA_ "GenMsgCycleTime" BO_ 929 1000;
BA_ "SCP_DataId" BO_ 929 13217;
BA_ "SC_Message" BO_ 929 1;
BA_ "VFrameFormat" BO_ 929 14;
BA_ "GenMsgRoutingTimeoutTime" BO_ 126 30;
BA_ "GenMsgSendType" BO_ 126 0;
BA_ "GenMsgCycleTime" BO_ 126 10;
BA_ "GenMsgDelayTime" BO_ 126 0;
BA_ "VFrameFormat" BO_ 126 14;
BA_ "FrameRouting" BO_ 1050 "MS1_CAN,0x41A;";
BA_ "VFrameFormat" BO_ 1050 14;
BA_ "FrameRouting" BO_ 1045 "FD1_CAN,0x415;";
BA_ "SCP_DataId" BO_ 1045 5141;
BA_ "SC_Message" BO_ 1045 1;
BA_ "VFrameFormat" BO_ 1045 14;
BA_ "FrameRouting" BO_ 1044 "FD1_CAN,0x414;";
BA_ "SCP_DataId" BO_ 1044 5140;
BA_ "SC_Message" BO_ 1044 1;
BA_ "VFrameFormat" BO_ 1044 14;
BA_ "FrameRouting" BO_ 765 "HS3_CAN,0x2FD;";
BA_ "VFrameFormat" BO_ 765 14;
BA_ "FrameRouting" BO_ 560 "FD1_CAN,0x230;";
BA_ "VFrameFormat" BO_ 560 14;
BA_ "FrameRouting" BO_ 559 "HS3_CAN,0x22F;";
BA_ "VFrameFormat" BO_ 559 14;
BA_ "GenMsgILSupport" BO_ 1413 0;
BA_ "NmAsrMessage" BO_ 1413 1;
BA_ "GenMsgSendType" BO_ 1413 0;
BA_ "GenMsgCycleTime" BO_ 1413 1000;
BA_ "NetworkInitialization" BO_ 1413 0;
BA_ "VFrameFormat" BO_ 1413 14;
BA_ "GenMsgILSupport" BO_ 1412 0;
BA_ "NmAsrMessage" BO_ 1412 1;
BA_ "GenMsgSendType" BO_ 1412 0;
BA_ "GenMsgCycleTime" BO_ 1412 1000;
BA_ "NetworkInitialization" BO_ 1412 0;
BA_ "VFrameFormat" BO_ 1412 14;
BA_ "GenMsgILSupport" BO_ 1822 0;
BA_ "DiagResponse" BO_ 1822 1;
BA_ "GenMsgSendType" BO_ 1822 1;
BA_ "GenMsgDelayTime" BO_ 1822 0;
BA_ "NetworkInitialization" BO_ 1822 0;
BA_ "VFrameFormat" BO_ 1822 14;
BA_ "GenMsgILSupport" BO_ 1878 0;
BA_ "DiagRequest" BO_ 1878 1;
BA_ "GenMsgSendType" BO_ 1878 1;
BA_ "GenMsgDelayTime" BO_ 1878 0;
BA_ "NetworkInitialization" BO_ 1878 0;
BA_ "VFrameFormat" BO_ 1878 14;
BA_ "TpTxIndex" BO_ 2610097368 462613720;
BA_ "GenMsgSendType" BO_ 2610097368 1;
BA_ "GenMsgDelayTime" BO_ 2610097368 0;
BA_ "NetworkInitialization" BO_ 2610097368 0;
BA_ "GenMsgILSupport" BO_ 1778 0;
BA_ "DiagRequest" BO_ 1778 1;
BA_ "GenMsgSendType" BO_ 1778 1;
BA_ "GenMsgDelayTime" BO_ 1778 0;
BA_ "NetworkInitialization" BO_ 1778 0;
BA_ "VFrameFormat" BO_ 1778 14;
BA_ "FrameRouting" BO_ 551 "HS3_CAN,0x227;";
BA_ "VFrameFormat" BO_ 551 14;
BA_ "FrameRouting" BO_ 358 "FD1_CAN,0x166;";
BA_ "SCP_DataId" BO_ 358 16742;
BA_ "SC_Message" BO_ 358 1;
BA_ "VFrameFormat" BO_ 358 14;
BA_ "GenMsgSendType" BO_ 673 5;
BA_ "GenMsgCycleTime" BO_ 673 100;
BA_ "VFrameFormat" BO_ 673 14;
BA_ "GenMsgSendType" BO_ 990 5;
BA_ "GenMsgCycleTime" BO_ 990 1000;
BA_ "VFrameFormat" BO_ 990 14;
BA_ "FrameRouting" BO_ 1100 "FD1_CAN,0x44C;";
BA_ "SCP_DataId" BO_ 1100 5196;
BA_ "SC_Message" BO_ 1100 1;
BA_ "VFrameFormat" BO_ 1100 14;
BA_ "FrameRouting" BO_ 1091 "HS3_CAN,0x443;";
BA_ "VFrameFormat" BO_ 1091 14;
BA_ "GenMsgSendType" BO_ 819 5;
BA_ "GenMsgCycleTime" BO_ 819 100;
BA_ "GenMsgStartDelayTime" BO_ 819 100;
BA_ "SCP_DataId" BO_ 819 9011;
BA_ "SC_Message" BO_ 819 1;
BA_ "VFrameFormat" BO_ 819 14;
BA_ "GenMsgSendType" BO_ 818 5;
BA_ "GenMsgCycleTime" BO_ 818 100;
BA_ "GenMsgStartDelayTime" BO_ 818 100;
BA_ "SCP_DataId" BO_ 818 9010;
BA_ "SC_Message" BO_ 818 1;
BA_ "VFrameFormat" BO_ 818 14;
BA_ "GenMsgILSupport" BO_ 1865 0;
BA_ "DiagResponse" BO_ 1865 1;
BA_ "GenMsgSendType" BO_ 1865 1;
BA_ "GenMsgDelayTime" BO_ 1865 0;
BA_ "NetworkInitialization" BO_ 1865 0;
BA_ "VFrameFormat" BO_ 1865 14;
BA_ "GenMsgILSupport" BO_ 1857 0;
BA_ "DiagRequest" BO_ 1857 1;
BA_ "GenMsgSendType" BO_ 1857 1;
BA_ "GenMsgDelayTime" BO_ 1857 0;
BA_ "NetworkInitialization" BO_ 1857 0;
BA_ "VFrameFormat" BO_ 1857 14;
BA_ "FrameRouting" BO_ 1046 "FD1_CAN,0x416;";
BA_ "SCP_DataId" BO_ 1046 5142;
BA_ "SC_Message" BO_ 1046 1;
BA_ "VFrameFormat" BO_ 1046 14;
BA_ "FrameRouting" BO_ 342 "FD1_CAN,0x156;";
BA_ "SCP_DataId" BO_ 342 4438;
BA_ "SC_Message" BO_ 342 1;
BA_ "VFrameFormat" BO_ 342 14;
BA_ "FrameRouting" BO_ 369 "FD1_CAN,0x171;";
BA_ "VFrameFormat" BO_ 369 14;
BA_ "GenMsgILSupport" BO_ 1842 0;
BA_ "DiagRequest" BO_ 1842 1;
BA_ "GenMsgSendType" BO_ 1842 1;
BA_ "GenMsgDelayTime" BO_ 1842 0;
BA_ "NetworkInitialization" BO_ 1842 0;
BA_ "VFrameFormat" BO_ 1842 14;
BA_ "TpTxIndex" BO_ 2612002008 464518360;
BA_ "GenMsgSendType" BO_ 2612002008 1;
BA_ "GenMsgDelayTime" BO_ 2612002008 0;
BA_ "NetworkInitialization" BO_ 2612002008 0;
BA_ "TpTxIndex" BO_ 2610953432 463469784;
BA_ "GenMsgSendType" BO_ 2610953432 1;
BA_ "GenMsgDelayTime" BO_ 2610953432 0;
BA_ "NetworkInitialization" BO_ 2610953432 0;
BA_ "FrameRouting" BO_ 862 "MS1_CAN,0x35E;";
BA_ "VFrameFormat" BO_ 862 14;
BA_ "GenMsgILSupport" BO_ 1459 0;
BA_ "NmAsrMessage" BO_ 1459 1;
BA_ "GenMsgSendType" BO_ 1459 0;
BA_ "GenMsgCycleTime" BO_ 1459 1000;
BA_ "NetworkInitialization" BO_ 1459 0;
BA_ "VFrameFormat" BO_ 1459 14;
BA_ "GenMsgRoutingTimeoutTime" BO_ 146 30;
BA_ "FrameRouting" BO_ 146 "HS2_CAN,0x92;FD1_CAN,0x92";
BA_ "VFrameFormat" BO_ 146 14;
BA_ "GenMsgILSupport" BO_ 1856 0;
BA_ "DiagRequest" BO_ 1856 1;
BA_ "GenMsgSendType" BO_ 1856 1;
BA_ "GenMsgDelayTime" BO_ 1856 0;
BA_ "NetworkInitialization" BO_ 1856 0;
BA_ "VFrameFormat" BO_ 1856 14;
BA_ "GenMsgILSupport" BO_ 1864 0;
BA_ "DiagResponse" BO_ 1864 1;
BA_ "GenMsgSendType" BO_ 1864 1;
BA_ "GenMsgDelayTime" BO_ 1864 0;
BA_ "NetworkInitialization" BO_ 1864 0;
BA_ "VFrameFormat" BO_ 1864 14;
BA_ "FrameRouting" BO_ 992 "HS3_CAN,0x3E0;";
BA_ "VFrameFormat" BO_ 992 14;
BA_ "FrameRouting" BO_ 994 "HS3_CAN,0x3E2;";
BA_ "VFrameFormat" BO_ 994 14;
BA_ "GenMsgILSupport" BO_ 1836 0;
BA_ "DiagResponse" BO_ 1836 1;
BA_ "GenMsgSendType" BO_ 1836 1;
BA_ "GenMsgDelayTime" BO_ 1836 0;
BA_ "NetworkInitialization" BO_ 1836 0;
BA_ "VFrameFormat" BO_ 1836 14;
BA_ "GenMsgILSupport" BO_ 1828 0;
BA_ "DiagRequest" BO_ 1828 1;
BA_ "GenMsgSendType" BO_ 1828 1;
BA_ "GenMsgDelayTime" BO_ 1828 0;
BA_ "NetworkInitialization" BO_ 1828 0;
BA_ "VFrameFormat" BO_ 1828 14;
BA_ "GenMsgSendType" BO_ 998 5;
BA_ "GenMsgCycleTime" BO_ 998 1000;
BA_ "VFrameFormat" BO_ 998 14;
BA_ "GenMsgILSupport" BO_ 1998 0;
BA_ "DiagResponse" BO_ 1998 1;
BA_ "GenMsgSendType" BO_ 1998 1;
BA_ "GenMsgDelayTime" BO_ 1998 0;
BA_ "NetworkInitialization" BO_ 1998 0;
BA_ "VFrameFormat" BO_ 1998 14;
BA_ "GenMsgILSupport" BO_ 1990 0;
BA_ "DiagRequest" BO_ 1990 1;
BA_ "GenMsgSendType" BO_ 1990 1;
BA_ "GenMsgDelayTime" BO_ 1990 0;
BA_ "NetworkInitialization" BO_ 1990 0;
BA_ "VFrameFormat" BO_ 1990 14;
BA_ "GenMsgILSupport" BO_ 1996 0;
BA_ "DiagResponse" BO_ 1996 1;
BA_ "GenMsgSendType" BO_ 1996 1;
BA_ "GenMsgDelayTime" BO_ 1996 0;
BA_ "NetworkInitialization" BO_ 1996 0;
BA_ "VFrameFormat" BO_ 1996 14;
BA_ "GenMsgILSupport" BO_ 1988 0;
BA_ "DiagRequest" BO_ 1988 1;
BA_ "GenMsgSendType" BO_ 1988 1;
BA_ "GenMsgDelayTime" BO_ 1988 0;
BA_ "NetworkInitialization" BO_ 1988 0;
BA_ "VFrameFormat" BO_ 1988 14;
BA_ "GenMsgSendType" BO_ 828 5;
BA_ "GenMsgCycleTime" BO_ 828 1000;
BA_ "SCP_DataId" BO_ 828 17212;
BA_ "SC_Message" BO_ 828 1;
BA_ "VFrameFormat" BO_ 828 14;
BA_ "GenMsgSendType" BO_ 943 0;
BA_ "GenMsgCycleTime" BO_ 943 20;
BA_ "GenMsgDelayTime" BO_ 943 10;
BA_ "VFrameFormat" BO_ 943 14;
BA_ "FrameRouting" BO_ 558 "HS3_CAN,0x22E;";
BA_ "VFrameFormat" BO_ 558 14;
BA_ "FrameRouting" BO_ 549 "HS3_CAN,0x225;";
BA_ "VFrameFormat" BO_ 549 14;
BA_ "GenMsgILSupport" BO_ 2015 0;
BA_ "DiagState" BO_ 2015 1;
BA_ "GenMsgSendType" BO_ 2015 1;
BA_ "GenMsgDelayTime" BO_ 2015 0;
BA_ "NetworkInitialization" BO_ 2015 0;
BA_ "VFrameFormat" BO_ 2015 14;
BA_ "FrameRouting" BO_ 132 "FD1_CAN,0x84;";
BA_ "SCP_DataId" BO_ 132 12420;
BA_ "SC_Message" BO_ 132 1;
BA_ "VFrameFormat" BO_ 132 14;
BA_ "FrameRouting" BO_ 947 "FD1_CAN,0x3B3;";
BA_ "SCP_DataId" BO_ 947 5043;
BA_ "SC_Message" BO_ 947 1;
BA_ "VFrameFormat" BO_ 947 14;
BA_ "FrameRouting" BO_ 1068 "FD1_CAN,0x42C;";
BA_ "SCP_DataId" BO_ 1068 5164;
BA_ "SC_Message" BO_ 1068 1;
BA_ "VFrameFormat" BO_ 1068 14;
BA_ "GenMsgILSupport" BO_ 1438 0;
BA_ "NmAsrMessage" BO_ 1438 1;
BA_ "GenMsgSendType" BO_ 1438 0;
BA_ "GenMsgCycleTime" BO_ 1438 1000;
BA_ "NetworkInitialization" BO_ 1438 0;
BA_ "VFrameFormat" BO_ 1438 14;
BA_ "GenMsgSendType" BO_ 826 5;
BA_ "GenMsgCycleTime" BO_ 826 100;
BA_ "GenMsgStartDelayTime" BO_ 826 100;
BA_ "VFrameFormat" BO_ 826 14;
BA_ "GenMsgSendType" BO_ 827 5;
BA_ "GenMsgCycleTime" BO_ 827 60;
BA_ "VFrameFormat" BO_ 827 14;
BA_ "GenSigSendType" SG_ 2611175457 PARSEDPhysIPMAtoGWM_ECG 3;
BA_ "ECGUsedRxSignal" SG_ 2611175457 PARSEDPhysIPMAtoGWM_ECG 1;
BA_ "U_P708_MY2023_Rx" SG_ 2611175457 PARSEDPhysIPMAtoGWM_ECG 1;
BA_ "U_CDX74X_MY2024_Rx" SG_ 2611175457 PARSEDPhysIPMAtoGWM_ECG 1;
BA_ "U_V710_MY2023_Rx" SG_ 2611175457 PARSEDPhysIPMAtoGWM_ECG 1;
BA_ "U_P702_MY2024_Rx" SG_ 2611175457 PARSEDPhysIPMAtoGWM_ECG 1;
BA_ "U_P708_MY2023_Tx" SG_ 2611175457 PARSEDPhysIPMAtoGWM_ECG 1;
BA_ "U_V710_MY2023_Tx" SG_ 2611175457 PARSEDPhysIPMAtoGWM_ECG 1;
BA_ "U_P702_MY2024_Tx" SG_ 2611175457 PARSEDPhysIPMAtoGWM_ECG 1;
BA_ "GenSigSendType" SG_ 2609933528 OTAPhysGWM_ECGtoGSM 3;
BA_ "ECGUsedTxSignal" SG_ 2609933528 OTAPhysGWM_ECGtoGSM 1;
BA_ "U_P708_MY2023_Tx" SG_ 2609933528 OTAPhysGWM_ECGtoGSM 1;
BA_ "U_P702_MY2024_Tx" SG_ 2609933528 OTAPhysGWM_ECGtoGSM 1;
BA_ "GenSigSendType" SG_ 2611175492 PARSEDPhysSCCMtoGWM_ECG 3;
BA_ "ECGUsedRxSignal" SG_ 2611175492 PARSEDPhysSCCMtoGWM_ECG 1;
BA_ "U_P708_MY2023_Rx" SG_ 2611175492 PARSEDPhysSCCMtoGWM_ECG 1;
BA_ "U_P702_MY2024_Rx" SG_ 2611175492 PARSEDPhysSCCMtoGWM_ECG 1;
BA_ "U_P708_MY2023_Tx" SG_ 2611175492 PARSEDPhysSCCMtoGWM_ECG 1;
BA_ "U_P702_MY2024_Tx" SG_ 2611175492 PARSEDPhysSCCMtoGWM_ECG 1;
BA_ "U_P708_MY2023_Rx" SG_ 1054 RbaBrk_D_Stat 1;
BA_ "U_V710_MY2023_Rx" SG_ 1054 RbaBrk_D_Stat 1;
BA_ "U_P702_MY2024_Rx" SG_ 1054 RbaBrk_D_Stat 1;
BA_ "U_V713N_MY2022_Rx" SG_ 1054 SelDrvMdeChassis2_D_Rq 1;
BA_ "U_P708_MY2023_Rx" SG_ 1054 SelDrvMdeChassis2_D_Rq 1;
BA_ "U_CDX74X_MY2024_Rx" SG_ 1054 SelDrvMdeChassis2_D_Rq 1;
BA_ "U_V710_MY2023_Rx" SG_ 1054 SelDrvMdeChassis2_D_Rq 1;
BA_ "U_P702_MY2024_Rx" SG_ 1054 SelDrvMdeChassis2_D_Rq 1;
BA_ "U_P708_MY2023_Rx" SG_ 1054 CtaBrk_D_Stat 1;
BA_ "U_V710_MY2023_Rx" SG_ 1054 CtaBrk_D_Stat 1;
BA_ "U_P702_MY2024_Rx" SG_ 1054 CtaBrk_D_Stat 1;
BA_ "GenSigStartValue" SG_ 1054 SelDrvMdeAwd_D_Rq 31;
BA_ "U_P708_MY2023_Rx" SG_ 1054 ApaBrk_D_Stat 1;
BA_ "U_V710_MY2023_Rx" SG_ 1054 ApaBrk_D_Stat 1;
BA_ "U_P702_MY2024_Rx" SG_ 1054 ApaBrk_D_Stat 1;
BA_ "GenSigStartValue" SG_ 1052 AwdCnnct_D_Stat 1;
BA_ "U_P708_MY2023_Rx" SG_ 1009 TrlrAidCancl_B_Rq 1;
BA_ "U_V710_MY2023_Rx" SG_ 1009 TrlrAidCancl_B_Rq 1;
BA_ "U_P702_MY2024_Rx" SG_ 1009 TrlrAidCancl_B_Rq 1;
BA_ "GenSigStartValue" SG_ 1009 CenterStackRing_D_Actl 2;
BA_ "U_P708_MY2023_Rx" SG_ 972 TrlrAn_An_TrgtCalc 1;
BA_ "U_V710_MY2023_Rx" SG_ 972 TrlrAn_An_TrgtCalc 1;
BA_ "U_P702_MY2024_Rx" SG_ 972 TrlrAn_An_TrgtCalc 1;
BA_ "U_P708_MY2023_Tx" SG_ 972 TrlrAn_An_TrgtCalc 1;
BA_ "U_P702_MY2024_Tx" SG_ 972 TrlrAn_An_TrgtCalc 1;
BA_ "U_P708_MY2023_Rx" SG_ 972 LaActAvail_D2_Actl 1;
BA_ "U_P702_MY2024_Rx" SG_ 972 LaActAvail_D2_Actl 1;
BA_ "U_P708_MY2023_Tx" SG_ 972 LaActAvail_D2_Actl 1;
BA_ "U_CDX74X_MY2024_Tx" SG_ 972 LaActAvail_D2_Actl 1;
BA_ "U_V710_MY2023_Tx" SG_ 972 LaActAvail_D2_Actl 1;
BA_ "U_P702_MY2024_Tx" SG_ 972 LaActAvail_D2_Actl 1;
BA_ "U_P708_MY2023_Tx" SG_ 972 LsmcBrkDecelEnbl_D_Rq 1;
BA_ "U_P702_MY2024_Tx" SG_ 972 LsmcBrkDecelEnbl_D_Rq 1;
BA_ "GenSigStartValue" SG_ 972 TjaHandsOnCnfdnc_B_Est 1;
BA_ "U_P708_MY2023_Rx" SG_ 972 TjaHandsOnCnfdnc_B_Est 1;
BA_ "U_V710_MY2023_Rx" SG_ 972 TjaHandsOnCnfdnc_B_Est 1;
BA_ "U_P702_MY2024_Rx" SG_ 972 TjaHandsOnCnfdnc_B_Est 1;
BA_ "U_V713N_MY2022_Tx" SG_ 972 TjaHandsOnCnfdnc_B_Est 1;
BA_ "U_P708_MY2023_Tx" SG_ 972 TjaHandsOnCnfdnc_B_Est 1;
BA_ "U_CDX74X_MY2024_Tx" SG_ 972 TjaHandsOnCnfdnc_B_Est 1;
BA_ "U_V710_MY2023_Tx" SG_ 972 TjaHandsOnCnfdnc_B_Est 1;
BA_ "U_P702_MY2024_Tx" SG_ 972 TjaHandsOnCnfdnc_B_Est 1;
BA_ "GenSigStartValue" SG_ 972 LaHandsOff_B_Actl 1;
BA_ "U_P708_MY2023_Rx" SG_ 972 LaHandsOff_B_Actl 1;
BA_ "U_V710_MY2023_Rx" SG_ 972 LaHandsOff_B_Actl 1;
BA_ "U_P702_MY2024_Rx" SG_ 972 LaHandsOff_B_Actl 1;
BA_ "U_V713N_MY2022_Tx" SG_ 972 LaHandsOff_B_Actl 1;
BA_ "U_P708_MY2023_Tx" SG_ 972 LaHandsOff_B_Actl 1;
BA_ "U_CDX74X_MY2024_Tx" SG_ 972 LaHandsOff_B_Actl 1;
BA_ "U_V710_MY2023_Tx" SG_ 972 LaHandsOff_B_Actl 1;
BA_ "U_P702_MY2024_Tx" SG_ 972 LaHandsOff_B_Actl 1;
BA_ "U_P708_MY2023_Rx" SG_ 972 LaActDeny_B_Actl 1;
BA_ "U_V710_MY2023_Rx" SG_ 972 LaActDeny_B_Actl 1;
BA_ "U_P702_MY2024_Rx" SG_ 972 LaActDeny_B_Actl 1;
BA_ "U_V713N_MY2022_Tx" SG_ 972 LaActDeny_B_Actl 1;
BA_ "U_P708_MY2023_Tx" SG_ 972 LaActDeny_B_Actl 1;
BA_ "U_CDX74X_MY2024_Tx" SG_ 972 LaActDeny_B_Actl 1;
BA_ "U_V710_MY2023_Tx" SG_ 972 LaActDeny_B_Actl 1;
BA_ "U_P702_MY2024_Tx" SG_ 972 LaActDeny_B_Actl 1;
BA_ "U_P708_MY2023_Tx" SG_ 972 LsmcBrk_Tq_Rq 1;
BA_ "U_P702_MY2024_Tx" SG_ 972 LsmcBrk_Tq_Rq 1;
BA_ "U_P708_MY2023_Rx" SG_ 972 LatCtlSte_D_Stat 1;
BA_ "U_V710_MY2023_Rx" SG_ 972 LatCtlSte_D_Stat 1;
BA_ "U_P702_MY2024_Rx" SG_ 972 LatCtlSte_D_Stat 1;
BA_ "U_V713N_MY2022_Tx" SG_ 972 LatCtlSte_D_Stat 1;
BA_ "U_P708_MY2023_Tx" SG_ 972 LatCtlSte_D_Stat 1;
BA_ "U_CDX74X_MY2024_Tx" SG_ 972 LatCtlSte_D_Stat 1;
BA_ "U_V710_MY2023_Tx" SG_ 972 LatCtlSte_D_Stat 1;
BA_ "U_P702_MY2024_Tx" SG_ 972 LatCtlSte_D_Stat 1;
BA_ "U_P708_MY2023_Rx" SG_ 972 LatCtlLim_D_Stat 1;
BA_ "U_V710_MY2023_Rx" SG_ 972 LatCtlLim_D_Stat 1;
BA_ "U_P702_MY2024_Rx" SG_ 972 LatCtlLim_D_Stat 1;
BA_ "U_V713N_MY2022_Tx" SG_ 972 LatCtlLim_D_Stat 1;
BA_ "U_P708_MY2023_Tx" SG_ 972 LatCtlLim_D_Stat 1;
BA_ "U_CDX74X_MY2024_Tx" SG_ 972 LatCtlLim_D_Stat 1;
BA_ "U_V710_MY2023_Tx" SG_ 972 LatCtlLim_D_Stat 1;
BA_ "U_P702_MY2024_Tx" SG_ 972 LatCtlLim_D_Stat 1;
BA_ "MetaData" SG_ 972 LatCtlCpbltyDStat_No_Cs 1;
BA_ "U_P708_MY2023_Rx" SG_ 972 LatCtlCpbltyDStat_No_Cs 1;
BA_ "U_V710_MY2023_Rx" SG_ 972 LatCtlCpbltyDStat_No_Cs 1;
BA_ "U_P702_MY2024_Rx" SG_ 972 LatCtlCpbltyDStat_No_Cs 1;
BA_ "U_V713N_MY2022_Tx" SG_ 972 LatCtlCpbltyDStat_No_Cs 1;
BA_ "U_P708_MY2023_Tx" SG_ 972 LatCtlCpbltyDStat_No_Cs 1;
BA_ "U_CDX74X_MY2024_Tx" SG_ 972 LatCtlCpbltyDStat_No_Cs 1;
BA_ "U_V710_MY2023_Tx" SG_ 972 LatCtlCpbltyDStat_No_Cs 1;
BA_ "U_P702_MY2024_Tx" SG_ 972 LatCtlCpbltyDStat_No_Cs 1;
BA_ "MetaData" SG_ 972 LatCtlCpbltyDStat_No_Cnt 1;
BA_ "U_P708_MY2023_Rx" SG_ 972 LatCtlCpbltyDStat_No_Cnt 1;
BA_ "U_V710_MY2023_Rx" SG_ 972 LatCtlCpbltyDStat_No_Cnt 1;
BA_ "U_P702_MY2024_Rx" SG_ 972 LatCtlCpbltyDStat_No_Cnt 1;
BA_ "U_V713N_MY2022_Tx" SG_ 972 LatCtlCpbltyDStat_No_Cnt 1;
BA_ "U_P708_MY2023_Tx" SG_ 972 LatCtlCpbltyDStat_No_Cnt 1;
BA_ "U_CDX74X_MY2024_Tx" SG_ 972 LatCtlCpbltyDStat_No_Cnt 1;
BA_ "U_V710_MY2023_Tx" SG_ 972 LatCtlCpbltyDStat_No_Cnt 1;
BA_ "U_P702_MY2024_Tx" SG_ 972 LatCtlCpbltyDStat_No_Cnt 1;
BA_ "U_P708_MY2023_Rx" SG_ 972 LatCtlCpblty_D_Stat 1;
BA_ "U_V710_MY2023_Rx" SG_ 972 LatCtlCpblty_D_Stat 1;
BA_ "U_P702_MY2024_Rx" SG_ 972 LatCtlCpblty_D_Stat 1;
BA_ "U_V713N_MY2022_Tx" SG_ 972 LatCtlCpblty_D_Stat 1;
BA_ "U_P708_MY2023_Tx" SG_ 972 LatCtlCpblty_D_Stat 1;
BA_ "U_CDX74X_MY2024_Tx" SG_ 972 LatCtlCpblty_D_Stat 1;
BA_ "U_V710_MY2023_Tx" SG_ 972 LatCtlCpblty_D_Stat 1;
BA_ "U_P702_MY2024_Tx" SG_ 972 LatCtlCpblty_D_Stat 1;
BA_ "GenSigSendType" SG_ 930 BalrWndwRight_B_Stat 3;
BA_ "U_P708_MY2023_Tx" SG_ 930 BalrWndwRight_B_Stat 1;
BA_ "U_V710_MY2023_Tx" SG_ 930 BalrWndwRight_B_Stat 1;
BA_ "U_P702_MY2024_Tx" SG_ 930 BalrWndwRight_B_Stat 1;
BA_ "GenSigSendType" SG_ 930 BalrSnsRight_D_Falt 3;
BA_ "U_P708_MY2023_Tx" SG_ 930 BalrSnsRight_D_Falt 1;
BA_ "U_V710_MY2023_Tx" SG_ 930 BalrSnsRight_D_Falt 1;
BA_ "U_P702_MY2024_Tx" SG_ 930 BalrSnsRight_D_Falt 1;
BA_ "GenSigSendType" SG_ 930 WndwPsngrRear_D_RqBalrr 3;
BA_ "U_P708_MY2023_Tx" SG_ 930 WndwPsngrRear_D_RqBalrr 1;
BA_ "U_V710_MY2023_Tx" SG_ 930 WndwPsngrRear_D_RqBalrr 1;
BA_ "U_P702_MY2024_Tx" SG_ 930 WndwPsngrRear_D_RqBalrr 1;
BA_ "GenSigSendType" SG_ 930 WndwPsngr_D_RqBalrr 3;
BA_ "U_P708_MY2023_Tx" SG_ 930 WndwPsngr_D_RqBalrr 1;
BA_ "U_V710_MY2023_Tx" SG_ 930 WndwPsngr_D_RqBalrr 1;
BA_ "U_P702_MY2024_Tx" SG_ 930 WndwPsngr_D_RqBalrr 1;
BA_ "GenSigSendType" SG_ 930 WndwDrvRear_D_RqBalrr 3;
BA_ "U_P708_MY2023_Tx" SG_ 930 WndwDrvRear_D_RqBalrr 1;
BA_ "U_V710_MY2023_Tx" SG_ 930 WndwDrvRear_D_RqBalrr 1;
BA_ "U_P702_MY2024_Tx" SG_ 930 WndwDrvRear_D_RqBalrr 1;
BA_ "GenSigSendType" SG_ 930 WndwDrv_D_RqBalrr 3;
BA_ "U_P708_MY2023_Tx" SG_ 930 WndwDrv_D_RqBalrr 1;
BA_ "U_V710_MY2023_Tx" SG_ 930 WndwDrv_D_RqBalrr 1;
BA_ "U_P702_MY2024_Tx" SG_ 930 WndwDrv_D_RqBalrr 1;
BA_ "GenSigStartValue" SG_ 930 BalrRight_D_Stat 2;
BA_ "GenSigSendType" SG_ 930 BalrRight_D_Stat 3;
BA_ "U_P708_MY2023_Tx" SG_ 930 BalrRight_D_Stat 1;
BA_ "U_V710_MY2023_Tx" SG_ 930 BalrRight_D_Stat 1;
BA_ "U_P702_MY2024_Tx" SG_ 930 BalrRight_D_Stat 1;
BA_ "GenSigSendType" SG_ 930 BalrMdeSelRight_B_Stat 3;
BA_ "U_P708_MY2023_Tx" SG_ 930 BalrMdeSelRight_B_Stat 1;
BA_ "U_V710_MY2023_Tx" SG_ 930 BalrMdeSelRight_B_Stat 1;
BA_ "U_P702_MY2024_Tx" SG_ 930 BalrMdeSelRight_B_Stat 1;
BA_ "GenSigStartValue" SG_ 930 BalrMdeRight_D_Stat 1;
BA_ "GenSigSendType" SG_ 930 BalrMdeRight_D_Stat 3;
BA_ "U_P708_MY2023_Tx" SG_ 930 BalrMdeRight_D_Stat 1;
BA_ "U_V710_MY2023_Tx" SG_ 930 BalrMdeRight_D_Stat 1;
BA_ "U_P702_MY2024_Tx" SG_ 930 BalrMdeRight_D_Stat 1;
BA_ "GenSigSendType" SG_ 930 BalrLckRight_B_Stat 3;
BA_ "U_P708_MY2023_Tx" SG_ 930 BalrLckRight_B_Stat 1;
BA_ "U_V710_MY2023_Tx" SG_ 930 BalrLckRight_B_Stat 1;
BA_ "U_P702_MY2024_Tx" SG_ 930 BalrLckRight_B_Stat 1;
BA_ "GenSigSendType" SG_ 930 BalrChimeRight_D_Rq 3;
BA_ "U_P708_MY2023_Tx" SG_ 930 BalrChimeRight_D_Rq 1;
BA_ "U_V710_MY2023_Tx" SG_ 930 BalrChimeRight_D_Rq 1;
BA_ "U_P702_MY2024_Tx" SG_ 930 BalrChimeRight_D_Rq 1;
BA_ "GenSigSendType" SG_ 930 CamraRearOn_B_RqBalrr 3;
BA_ "U_P708_MY2023_Tx" SG_ 930 CamraRearOn_B_RqBalrr 1;
BA_ "U_V710_MY2023_Tx" SG_ 930 CamraRearOn_B_RqBalrr 1;
BA_ "U_P702_MY2024_Tx" SG_ 930 CamraRearOn_B_RqBalrr 1;
BA_ "GenSigSendType" SG_ 930 DrLckCnt_No_ActlBalrr 3;
BA_ "U_P708_MY2023_Tx" SG_ 930 DrLckCnt_No_ActlBalrr 1;
BA_ "U_V710_MY2023_Tx" SG_ 930 DrLckCnt_No_ActlBalrr 1;
BA_ "U_P702_MY2024_Tx" SG_ 930 DrLckCnt_No_ActlBalrr 1;
BA_ "GenSigSendType" SG_ 930 DrLckActv_B_RqBalrr 3;
BA_ "U_P708_MY2023_Tx" SG_ 930 DrLckActv_B_RqBalrr 1;
BA_ "U_V710_MY2023_Tx" SG_ 930 DrLckActv_B_RqBalrr 1;
BA_ "U_P702_MY2024_Tx" SG_ 930 DrLckActv_B_RqBalrr 1;
BA_ "GenSigStartValue" SG_ 374 TrnRng_D_Rq 14;
BA_ "U_P708_MY2023_Rx" SG_ 374 TrnRng_D_Rq 1;
BA_ "U_P702_MY2024_Rx" SG_ 374 TrnRng_D_Rq 1;
BA_ "U_V710_MY2023_Rx" SG_ 374 TrnRng_D_Rq 1;
BA_ "U_P708_MY2023_Rx" SG_ 374 TrnPrkSys_D_Actl 1;
BA_ "U_V710_MY2023_Rx" SG_ 374 TrnPrkSys_D_Actl 1;
BA_ "U_P702_MY2024_Rx" SG_ 374 TrnPrkSys_D_Actl 1;
BA_ "U_P708_MY2023_Rx" SG_ 374 GearLvr_D_ActlDrv 1;
BA_ "U_V710_MY2023_Rx" SG_ 374 GearLvr_D_ActlDrv 1;
BA_ "U_P702_MY2024_Rx" SG_ 374 GearLvr_D_ActlDrv 1;
BA_ "MetaData" SG_ 374 GearPos_No_Cs 1;
BA_ "U_P708_MY2023_Rx" SG_ 374 GearPos_No_Cs 1;
BA_ "U_V710_MY2023_Rx" SG_ 374 GearPos_No_Cs 1;
BA_ "U_P702_MY2024_Rx" SG_ 374 GearPos_No_Cs 1;
BA_ "GenSigStartValue" SG_ 374 GearPos_D_Trg 15;
BA_ "U_P708_MY2023_Rx" SG_ 374 GearPos_D_Trg 1;
BA_ "U_CDX74X_MY2024_Rx" SG_ 374 GearPos_D_Trg 1;
BA_ "U_V710_MY2023_Rx" SG_ 374 GearPos_D_Trg 1;
BA_ "U_P702_MY2024_Rx" SG_ 374 GearPos_D_Trg 1;
BA_ "MetaData" SG_ 374 GearPos_No_Cnt 1;
BA_ "U_P708_MY2023_Rx" SG_ 374 GearPos_No_Cnt 1;
BA_ "U_V710_MY2023_Rx" SG_ 374 GearPos_No_Cnt 1;
BA_ "U_P702_MY2024_Rx" SG_ 374 GearPos_No_Cnt 1;
BA_ "GenSigStartValue" SG_ 374 GearPos_D_Actl 15;
BA_ "U_P708_MY2023_Rx" SG_ 374 GearPos_D_Actl 1;
BA_ "U_V710_MY2023_Rx" SG_ 374 GearPos_D_Actl 1;
BA_ "U_P702_MY2024_Rx" SG_ 374 GearPos_D_Actl 1;
BA_ "U_V713N_MY2022_Rx" SG_ 359 PrplWhlTot2_Tq_Actl 1;
BA_ "U_P708_MY2023_Rx" SG_ 359 PrplWhlTot2_Tq_Actl 1;
BA_ "U_CDX74X_MY2024_Rx" SG_ 359 PrplWhlTot2_Tq_Actl 1;
BA_ "U_V710_MY2023_Rx" SG_ 359 PrplWhlTot2_Tq_Actl 1;
BA_ "U_P702_MY2024_Rx" SG_ 359 PrplWhlTot2_Tq_Actl 1;
BA_ "U_P708_MY2023_Rx" SG_ 359 PwPckTq_D_Stat 1;
BA_ "U_CDX74X_MY2024_Rx" SG_ 359 PwPckTq_D_Stat 1;
BA_ "U_V710_MY2023_Rx" SG_ 359 PwPckTq_D_Stat 1;
BA_ "U_P702_MY2024_Rx" SG_ 359 PwPckTq_D_Stat 1;
BA_ "U_V713N_MY2022_Rx" SG_ 359 PwPckTq_D_Stat 1;
BA_ "U_V713N_MY2022_Rx" SG_ 359 ElPw_D_Stat 1;
BA_ "U_P708_MY2023_Rx" SG_ 359 ElPw_D_Stat 1;
BA_ "U_CDX74X_MY2024_Rx" SG_ 359 ElPw_D_Stat 1;
BA_ "U_V710_MY2023_Rx" SG_ 359 ElPw_D_Stat 1;
BA_ "U_P702_MY2024_Rx" SG_ 359 ElPw_D_Stat 1;
BA_ "MetaData" SG_ 359 TrnAinTq_D_Qf 1;
BA_ "MetaData" SG_ 357 BPedDrvAppl_D_Qf 1;
BA_ "GenSigStartValue" SG_ 357 BPedDrvAppl_D_Qf 1;
BA_ "U_P708_MY2023_Rx" SG_ 357 BPedDrvAppl_D_Qf 1;
BA_ "U_P702_MY2024_Rx" SG_ 357 BPedDrvAppl_D_Qf 1;
BA_ "U_V710_MY2023_Rx" SG_ 357 BPedDrvAppl_D_Qf 1;
BA_ "U_P708_MY2023_Rx" SG_ 357 CmbbDeny_B_ActlPrpl 1;
BA_ "U_V710_MY2023_Rx" SG_ 357 CmbbDeny_B_ActlPrpl 1;
BA_ "U_P702_MY2024_Rx" SG_ 357 CmbbDeny_B_ActlPrpl 1;
BA_ "U_P708_MY2023_Rx" SG_ 357 PrplTqMnSat_B_Actl 1;
BA_ "U_V710_MY2023_Rx" SG_ 357 PrplTqMnSat_B_Actl 1;
BA_ "U_P702_MY2024_Rx" SG_ 357 PrplTqMnSat_B_Actl 1;
BA_ "GenSigStartValue" SG_ 357 BpedDrvAppl_D_Actl 1;
BA_ "U_P708_MY2023_Rx" SG_ 357 BpedDrvAppl_D_Actl 1;
BA_ "U_V710_MY2023_Rx" SG_ 357 BpedDrvAppl_D_Actl 1;
BA_ "U_P702_MY2024_Rx" SG_ 357 BpedDrvAppl_D_Actl 1;
BA_ "U_P708_MY2023_Rx" SG_ 357 CmbbEngTqMn_B_Actl 1;
BA_ "U_V710_MY2023_Rx" SG_ 357 CmbbEngTqMn_B_Actl 1;
BA_ "U_P702_MY2024_Rx" SG_ 357 CmbbEngTqMn_B_Actl 1;
BA_ "U_P708_MY2023_Rx" SG_ 357 Veh_V_DsplyCcSet 1;
BA_ "U_V710_MY2023_Rx" SG_ 357 Veh_V_DsplyCcSet 1;
BA_ "U_P702_MY2024_Rx" SG_ 357 Veh_V_DsplyCcSet 1;
BA_ "U_P708_MY2023_Rx" SG_ 357 AccEngStat_D_Actl 1;
BA_ "U_V710_MY2023_Rx" SG_ 357 AccEngStat_D_Actl 1;
BA_ "U_P702_MY2024_Rx" SG_ 357 AccEngStat_D_Actl 1;
BA_ "U_P708_MY2023_Rx" SG_ 357 CcStat_D_Actl 1;
BA_ "U_V710_MY2023_Rx" SG_ 357 CcStat_D_Actl 1;
BA_ "U_P702_MY2024_Rx" SG_ 357 CcStat_D_Actl 1;
BA_ "U_P708_MY2023_Rx" SG_ 357 CcOvrrdActv_B_Actl 1;
BA_ "U_V710_MY2023_Rx" SG_ 357 CcOvrrdActv_B_Actl 1;
BA_ "U_P702_MY2024_Rx" SG_ 357 CcOvrrdActv_B_Actl 1;
BA_ "U_P708_MY2023_Rx" SG_ 357 AccStopMde_D_Rq 1;
BA_ "U_V710_MY2023_Rx" SG_ 357 AccStopMde_D_Rq 1;
BA_ "U_P702_MY2024_Rx" SG_ 357 AccStopMde_D_Rq 1;
BA_ "GenSigSendType" SG_ 934 CtaAlrtLeft2_D_Stat 3;
BA_ "U_P708_MY2023_Tx" SG_ 934 CtaAlrtLeft2_D_Stat 1;
BA_ "U_V710_MY2023_Tx" SG_ 934 CtaAlrtLeft2_D_Stat 1;
BA_ "U_P702_MY2024_Tx" SG_ 934 CtaAlrtLeft2_D_Stat 1;
BA_ "GenSigSendType" SG_ 934 CtaBrkLeftMsgTxt_B_Rq 3;
BA_ "U_P708_MY2023_Tx" SG_ 934 CtaBrkLeftMsgTxt_B_Rq 1;
BA_ "U_V710_MY2023_Tx" SG_ 934 CtaBrkLeftMsgTxt_B_Rq 1;
BA_ "U_P702_MY2024_Tx" SG_ 934 CtaBrkLeftMsgTxt_B_Rq 1;
BA_ "GenSigSendType" SG_ 934 CtaLeftBrkDecel_B_Rq 3;
BA_ "U_P708_MY2023_Tx" SG_ 934 CtaLeftBrkDecel_B_Rq 1;
BA_ "U_V710_MY2023_Tx" SG_ 934 CtaLeftBrkDecel_B_Rq 1;
BA_ "U_P702_MY2024_Tx" SG_ 934 CtaLeftBrkDecel_B_Rq 1;
BA_ "GenSigSendType" SG_ 934 CtaLeftBrkEnbl_B_Rq 3;
BA_ "U_P708_MY2023_Tx" SG_ 934 CtaLeftBrkEnbl_B_Rq 1;
BA_ "U_V710_MY2023_Tx" SG_ 934 CtaLeftBrkEnbl_B_Rq 1;
BA_ "U_P702_MY2024_Tx" SG_ 934 CtaLeftBrkEnbl_B_Rq 1;
BA_ "GenSigStartValue" SG_ 934 Side_Detect_L_Illum 100;
BA_ "U_P708_MY2023_Rx" SG_ 934 Side_Detect_L_Illum 1;
BA_ "U_P702_MY2024_Rx" SG_ 934 Side_Detect_L_Illum 1;
BA_ "U_P708_MY2023_Tx" SG_ 934 Side_Detect_L_Illum 1;
BA_ "U_V710_MY2023_Tx" SG_ 934 Side_Detect_L_Illum 1;
BA_ "U_P702_MY2024_Tx" SG_ 934 Side_Detect_L_Illum 1;
BA_ "GenSigSendType" SG_ 934 BttLeft_D_Stat 3;
BA_ "U_P708_MY2023_Tx" SG_ 934 BttLeft_D_Stat 1;
BA_ "U_V710_MY2023_Tx" SG_ 934 BttLeft_D_Stat 1;
BA_ "U_P702_MY2024_Tx" SG_ 934 BttLeft_D_Stat 1;
BA_ "GenSigSendType" SG_ 934 BttLeft_D_RqDrv 3;
BA_ "U_P708_MY2023_Tx" SG_ 934 BttLeft_D_RqDrv 1;
BA_ "U_V710_MY2023_Tx" SG_ 934 BttLeft_D_RqDrv 1;
BA_ "U_P702_MY2024_Tx" SG_ 934 BttLeft_D_RqDrv 1;
BA_ "GenSigSendType" SG_ 934 CtaSnsLeft_D_Stat 3;
BA_ "U_P708_MY2023_Tx" SG_ 934 CtaSnsLeft_D_Stat 1;
BA_ "U_V710_MY2023_Tx" SG_ 934 CtaSnsLeft_D_Stat 1;
BA_ "U_P702_MY2024_Tx" SG_ 934 CtaSnsLeft_D_Stat 1;
BA_ "GenSigSendType" SG_ 934 SodDetctLeft_D_Stat 3;
BA_ "U_P708_MY2023_Tx" SG_ 934 SodDetctLeft_D_Stat 1;
BA_ "U_V710_MY2023_Tx" SG_ 934 SodDetctLeft_D_Stat 1;
BA_ "U_P702_MY2024_Tx" SG_ 934 SodDetctLeft_D_Stat 1;
BA_ "GenSigSendType" SG_ 934 CtaLeft_D_Stat 3;
BA_ "U_P708_MY2023_Tx" SG_ 934 CtaLeft_D_Stat 1;
BA_ "U_V710_MY2023_Tx" SG_ 934 CtaLeft_D_Stat 1;
BA_ "U_P702_MY2024_Tx" SG_ 934 CtaLeft_D_Stat 1;
BA_ "GenSigSendType" SG_ 934 CtaAlrtLeft_D_Stat 3;
BA_ "U_P708_MY2023_Rx" SG_ 934 CtaAlrtLeft_D_Stat 1;
BA_ "U_P702_MY2024_Rx" SG_ 934 CtaAlrtLeft_D_Stat 1;
BA_ "U_P708_MY2023_Tx" SG_ 934 CtaAlrtLeft_D_Stat 1;
BA_ "U_V710_MY2023_Tx" SG_ 934 CtaAlrtLeft_D_Stat 1;
BA_ "U_P702_MY2024_Tx" SG_ 934 CtaAlrtLeft_D_Stat 1;
BA_ "GenSigStartValue" SG_ 934 SodLeft_D_Stat 2;
BA_ "GenSigSendType" SG_ 934 SodLeft_D_Stat 3;
BA_ "U_P708_MY2023_Tx" SG_ 934 SodLeft_D_Stat 1;
BA_ "U_V710_MY2023_Tx" SG_ 934 SodLeft_D_Stat 1;
BA_ "U_P702_MY2024_Tx" SG_ 934 SodLeft_D_Stat 1;
BA_ "GenSigSendType" SG_ 934 SodSnsLeft_D_Stat 3;
BA_ "U_P708_MY2023_Rx" SG_ 934 SodSnsLeft_D_Stat 1;
BA_ "U_P702_MY2024_Rx" SG_ 934 SodSnsLeft_D_Stat 1;
BA_ "U_P708_MY2023_Tx" SG_ 934 SodSnsLeft_D_Stat 1;
BA_ "U_V710_MY2023_Tx" SG_ 934 SodSnsLeft_D_Stat 1;
BA_ "U_P702_MY2024_Tx" SG_ 934 SodSnsLeft_D_Stat 1;
BA_ "GenSigSendType" SG_ 934 SodAlrtLeft_D_Stat 3;
BA_ "U_P708_MY2023_Rx" SG_ 934 SodAlrtLeft_D_Stat 1;
BA_ "U_P702_MY2024_Rx" SG_ 934 SodAlrtLeft_D_Stat 1;
BA_ "U_P708_MY2023_Tx" SG_ 934 SodAlrtLeft_D_Stat 1;
BA_ "U_V710_MY2023_Tx" SG_ 934 SodAlrtLeft_D_Stat 1;
BA_ "U_P702_MY2024_Tx" SG_ 934 SodAlrtLeft_D_Stat 1;
BA_ "GenSigStartValue" SG_ 934 SodWarnLeft_Prd_Rq 14;
BA_ "U_P708_MY2023_Rx" SG_ 934 SodWarnLeft_Prd_Rq 1;
BA_ "U_P702_MY2024_Rx" SG_ 934 SodWarnLeft_Prd_Rq 1;
BA_ "U_P708_MY2023_Tx" SG_ 934 SodWarnLeft_Prd_Rq 1;
BA_ "U_V710_MY2023_Tx" SG_ 934 SodWarnLeft_Prd_Rq 1;
BA_ "U_P702_MY2024_Tx" SG_ 934 SodWarnLeft_Prd_Rq 1;
BA_ "GenSigSendType" SG_ 929 BalrChimeLeft_D_Rq 3;
BA_ "U_P708_MY2023_Tx" SG_ 929 BalrChimeLeft_D_Rq 1;
BA_ "U_V710_MY2023_Tx" SG_ 929 BalrChimeLeft_D_Rq 1;
BA_ "U_P702_MY2024_Tx" SG_ 929 BalrChimeLeft_D_Rq 1;
BA_ "GenSigStartValue" SG_ 929 BalrLeft_D_Stat 2;
BA_ "GenSigSendType" SG_ 929 BalrLeft_D_Stat 3;
BA_ "U_P708_MY2023_Tx" SG_ 929 BalrLeft_D_Stat 1;
BA_ "U_V710_MY2023_Tx" SG_ 929 BalrLeft_D_Stat 1;
BA_ "U_P702_MY2024_Tx" SG_ 929 BalrLeft_D_Stat 1;
BA_ "GenSigSendType" SG_ 929 WndwPsngrRear_D_RqBalrl 3;
BA_ "U_P708_MY2023_Tx" SG_ 929 WndwPsngrRear_D_RqBalrl 1;
BA_ "U_V710_MY2023_Tx" SG_ 929 WndwPsngrRear_D_RqBalrl 1;
BA_ "U_P702_MY2024_Tx" SG_ 929 WndwPsngrRear_D_RqBalrl 1;
BA_ "GenSigSendType" SG_ 929 WndwPsngr_D_RqBalrl 3;
BA_ "U_P708_MY2023_Tx" SG_ 929 WndwPsngr_D_RqBalrl 1;
BA_ "U_V710_MY2023_Tx" SG_ 929 WndwPsngr_D_RqBalrl 1;
BA_ "U_P702_MY2024_Tx" SG_ 929 WndwPsngr_D_RqBalrl 1;
BA_ "GenSigSendType" SG_ 929 WndwDrvRear_D_RqBalrl 3;
BA_ "U_P708_MY2023_Tx" SG_ 929 WndwDrvRear_D_RqBalrl 1;
BA_ "U_V710_MY2023_Tx" SG_ 929 WndwDrvRear_D_RqBalrl 1;
BA_ "U_P702_MY2024_Tx" SG_ 929 WndwDrvRear_D_RqBalrl 1;
BA_ "GenSigSendType" SG_ 929 WndwDrv_D_RqBalrl 3;
BA_ "U_P708_MY2023_Tx" SG_ 929 WndwDrv_D_RqBalrl 1;
BA_ "U_V710_MY2023_Tx" SG_ 929 WndwDrv_D_RqBalrl 1;
BA_ "U_P702_MY2024_Tx" SG_ 929 WndwDrv_D_RqBalrl 1;
BA_ "GenSigSendType" SG_ 929 BalrSnsLeft_D_Falt 3;
BA_ "U_P708_MY2023_Tx" SG_ 929 BalrSnsLeft_D_Falt 1;
BA_ "U_V710_MY2023_Tx" SG_ 929 BalrSnsLeft_D_Falt 1;
BA_ "U_P702_MY2024_Tx" SG_ 929 BalrSnsLeft_D_Falt 1;
BA_ "GenSigSendType" SG_ 929 BalrMdeSelLeft_B_Stat 3;
BA_ "U_P708_MY2023_Tx" SG_ 929 BalrMdeSelLeft_B_Stat 1;
BA_ "U_V710_MY2023_Tx" SG_ 929 BalrMdeSelLeft_B_Stat 1;
BA_ "U_P702_MY2024_Tx" SG_ 929 BalrMdeSelLeft_B_Stat 1;
BA_ "GenSigStartValue" SG_ 929 BalrMdeLeft_D_Stat 1;
BA_ "GenSigSendType" SG_ 929 BalrMdeLeft_D_Stat 3;
BA_ "U_P708_MY2023_Tx" SG_ 929 BalrMdeLeft_D_Stat 1;
BA_ "U_V710_MY2023_Tx" SG_ 929 BalrMdeLeft_D_Stat 1;
BA_ "U_P702_MY2024_Tx" SG_ 929 BalrMdeLeft_D_Stat 1;
BA_ "GenSigSendType" SG_ 929 BalrLckLeft_B_Stat 3;
BA_ "U_P708_MY2023_Tx" SG_ 929 BalrLckLeft_B_Stat 1;
BA_ "U_V710_MY2023_Tx" SG_ 929 BalrLckLeft_B_Stat 1;
BA_ "U_P702_MY2024_Tx" SG_ 929 BalrLckLeft_B_Stat 1;
BA_ "GenSigSendType" SG_ 929 CamraRearOn_B_RqBalrl 3;
BA_ "U_P708_MY2023_Tx" SG_ 929 CamraRearOn_B_RqBalrl 1;
BA_ "U_V710_MY2023_Tx" SG_ 929 CamraRearOn_B_RqBalrl 1;
BA_ "U_P702_MY2024_Tx" SG_ 929 CamraRearOn_B_RqBalrl 1;
BA_ "GenSigSendType" SG_ 929 DrLckCnt_No_ActlBalrl 3;
BA_ "U_P708_MY2023_Tx" SG_ 929 DrLckCnt_No_ActlBalrl 1;
BA_ "U_V710_MY2023_Tx" SG_ 929 DrLckCnt_No_ActlBalrl 1;
BA_ "U_P702_MY2024_Tx" SG_ 929 DrLckCnt_No_ActlBalrl 1;
BA_ "GenSigSendType" SG_ 929 DrLckActv_B_RqBalrl 3;
BA_ "U_P708_MY2023_Tx" SG_ 929 DrLckActv_B_RqBalrl 1;
BA_ "U_V710_MY2023_Tx" SG_ 929 DrLckActv_B_RqBalrl 1;
BA_ "U_P702_MY2024_Tx" SG_ 929 DrLckActv_B_RqBalrl 1;
BA_ "GenSigSendType" SG_ 929 BalrWndwLeft_B_Stat 3;
BA_ "U_P708_MY2023_Tx" SG_ 929 BalrWndwLeft_B_Stat 1;
BA_ "U_V710_MY2023_Tx" SG_ 929 BalrWndwLeft_B_Stat 1;
BA_ "U_P702_MY2024_Tx" SG_ 929 BalrWndwLeft_B_Stat 1;
BA_ "GenSigStartValue" SG_ 126 StePinRelInit_An_Sns 65534;
BA_ "U_V710_MY2023_Rx" SG_ 126 StePinRelInit_An_Sns 1;
BA_ "U_P702_MY2024_Rx" SG_ 126 StePinRelInit_An_Sns 1;
BA_ "ECGUsedRxSignal" SG_ 126 StePinRelInit_An_Sns 1;
BA_ "U_V713N_MY2022_Tx" SG_ 126 StePinRelInit_An_Sns 1;
BA_ "U_P708_MY2023_Tx" SG_ 126 StePinRelInit_An_Sns 1;
BA_ "U_CDX74X_MY2024_Tx" SG_ 126 StePinRelInit_An_Sns 1;
BA_ "U_V710_MY2023_Tx" SG_ 126 StePinRelInit_An_Sns 1;
BA_ "U_P702_MY2024_Tx" SG_ 126 StePinRelInit_An_Sns 1;
BA_ "MetaData" SG_ 126 StePinCompAnEst_D_Qf 1;
BA_ "GenSigStartValue" SG_ 126 StePinCompAnEst_D_Qf 1;
BA_ "U_P708_MY2023_Rx" SG_ 126 StePinCompAnEst_D_Qf 1;
BA_ "U_CDX74X_MY2024_Rx" SG_ 126 StePinCompAnEst_D_Qf 1;
BA_ "U_V710_MY2023_Rx" SG_ 126 StePinCompAnEst_D_Qf 1;
BA_ "U_P702_MY2024_Rx" SG_ 126 StePinCompAnEst_D_Qf 1;
BA_ "ECGUsedRxSignal" SG_ 126 StePinCompAnEst_D_Qf 1;
BA_ "U_V713N_MY2022_Tx" SG_ 126 StePinCompAnEst_D_Qf 1;
BA_ "U_P708_MY2023_Tx" SG_ 126 StePinCompAnEst_D_Qf 1;
BA_ "U_CDX74X_MY2024_Tx" SG_ 126 StePinCompAnEst_D_Qf 1;
BA_ "U_V710_MY2023_Tx" SG_ 126 StePinCompAnEst_D_Qf 1;
BA_ "U_P702_MY2024_Tx" SG_ 126 StePinCompAnEst_D_Qf 1;
BA_ "U_P708_MY2023_Rx" SG_ 126 StePinComp_An_Est 1;
BA_ "U_CDX74X_MY2024_Rx" SG_ 126 StePinComp_An_Est 1;
BA_ "U_V710_MY2023_Rx" SG_ 126 StePinComp_An_Est 1;
BA_ "U_P702_MY2024_Rx" SG_ 126 StePinComp_An_Est 1;
BA_ "ECGUsedRxSignal" SG_ 126 StePinComp_An_Est 1;
BA_ "U_V713N_MY2022_Tx" SG_ 126 StePinComp_An_Est 1;
BA_ "U_P708_MY2023_Tx" SG_ 126 StePinComp_An_Est 1;
BA_ "U_CDX74X_MY2024_Tx" SG_ 126 StePinComp_An_Est 1;
BA_ "U_V710_MY2023_Tx" SG_ 126 StePinComp_An_Est 1;
BA_ "U_P702_MY2024_Tx" SG_ 126 StePinComp_An_Est 1;
BA_ "MetaData" SG_ 126 StePinAn_No_Cs 1;
BA_ "ECGUsedRxSignal" SG_ 126 StePinAn_No_Cs 1;
BA_ "U_V710_MY2023_Rx" SG_ 126 StePinAn_No_Cs 1;
BA_ "U_P702_MY2024_Rx" SG_ 126 StePinAn_No_Cs 1;
BA_ "U_V713N_MY2022_Tx" SG_ 126 StePinAn_No_Cs 1;
BA_ "U_P708_MY2023_Tx" SG_ 126 StePinAn_No_Cs 1;
BA_ "U_CDX74X_MY2024_Tx" SG_ 126 StePinAn_No_Cs 1;
BA_ "U_V710_MY2023_Tx" SG_ 126 StePinAn_No_Cs 1;
BA_ "U_P702_MY2024_Tx" SG_ 126 StePinAn_No_Cs 1;
BA_ "MetaData" SG_ 126 StePinAn_No_Cnt 1;
BA_ "ECGUsedRxSignal" SG_ 126 StePinAn_No_Cnt 1;
BA_ "U_V710_MY2023_Rx" SG_ 126 StePinAn_No_Cnt 1;
BA_ "U_P702_MY2024_Rx" SG_ 126 StePinAn_No_Cnt 1;
BA_ "U_V713N_MY2022_Tx" SG_ 126 StePinAn_No_Cnt 1;
BA_ "U_P708_MY2023_Tx" SG_ 126 StePinAn_No_Cnt 1;
BA_ "U_CDX74X_MY2024_Tx" SG_ 126 StePinAn_No_Cnt 1;
BA_ "U_V710_MY2023_Tx" SG_ 126 StePinAn_No_Cnt 1;
BA_ "U_P702_MY2024_Tx" SG_ 126 StePinAn_No_Cnt 1;
BA_ "U_P708_MY2023_Rx" SG_ 1050 SteWhlHeat_D_Rq 1;
BA_ "U_P702_MY2024_Rx" SG_ 1050 SteWhlHeat_D_Rq 1;
BA_ "U_P708_MY2023_Rx" SG_ 1050 MirrorHeatOn_B_Rq 1;
BA_ "U_P702_MY2024_Rx" SG_ 1050 MirrorHeatOn_B_Rq 1;
BA_ "GenSigStartValue" SG_ 1050 Outside_Air_Temp_Stat 254;
BA_ "U_P708_MY2023_Rx" SG_ 1050 Outside_Air_Temp_Stat 1;
BA_ "U_V710_MY2023_Rx" SG_ 1050 Outside_Air_Temp_Stat 1;
BA_ "U_P702_MY2024_Rx" SG_ 1050 Outside_Air_Temp_Stat 1;
BA_ "U_V713N_MY2022_Rx" SG_ 1050 Outside_Air_Temp_Stat 1;
BA_ "U_CDX74X_MY2024_Rx" SG_ 1050 Outside_Air_Temp_Stat 1;
BA_ "GenSigStartValue" SG_ 1045 VehStab_D_Stat 14;
BA_ "U_P708_MY2023_Rx" SG_ 1045 VehStab_D_Stat 1;
BA_ "U_CDX74X_MY2024_Rx" SG_ 1045 VehStab_D_Stat 1;
BA_ "U_V710_MY2023_Rx" SG_ 1045 VehStab_D_Stat 1;
BA_ "U_P702_MY2024_Rx" SG_ 1045 VehStab_D_Stat 1;
BA_ "U_P708_MY2023_Rx" SG_ 1045 LsmcBrkDecel_D_Stat 1;
BA_ "U_CDX74X_MY2024_Rx" SG_ 1045 LsmcBrkDecel_D_Stat 1;
BA_ "U_V710_MY2023_Rx" SG_ 1045 LsmcBrkDecel_D_Stat 1;
BA_ "U_P702_MY2024_Rx" SG_ 1045 LsmcBrkDecel_D_Stat 1;
BA_ "GenSigStartValue" SG_ 1045 VehYawNonLin_W_Rq 4094;
BA_ "GenSigStartValue" SG_ 1045 VehYawLin_W_Rq 4094;
BA_ "MetaData" SG_ 1045 VehVActlBrk_No_Cs 1;
BA_ "U_P708_MY2023_Rx" SG_ 1045 VehVActlBrk_No_Cs 1;
BA_ "U_V710_MY2023_Rx" SG_ 1045 VehVActlBrk_No_Cs 1;
BA_ "U_P702_MY2024_Rx" SG_ 1045 VehVActlBrk_No_Cs 1;
BA_ "U_V713N_MY2022_Rx" SG_ 1045 VehVActlBrk_No_Cs 1;
BA_ "U_CDX74X_MY2024_Rx" SG_ 1045 VehVActlBrk_No_Cs 1;
BA_ "U_P708_MY2023_Rx" SG_ 1045 Veh_V_ActlBrk 1;
BA_ "U_V710_MY2023_Rx" SG_ 1045 Veh_V_ActlBrk 1;
BA_ "U_P702_MY2024_Rx" SG_ 1045 Veh_V_ActlBrk 1;
BA_ "U_V713N_MY2022_Rx" SG_ 1045 Veh_V_ActlBrk 1;
BA_ "U_CDX74X_MY2024_Rx" SG_ 1045 Veh_V_ActlBrk 1;
BA_ "MetaData" SG_ 1045 VehVActlBrk_No_Cnt 1;
BA_ "U_P708_MY2023_Rx" SG_ 1045 VehVActlBrk_No_Cnt 1;
BA_ "U_V710_MY2023_Rx" SG_ 1045 VehVActlBrk_No_Cnt 1;
BA_ "U_P702_MY2024_Rx" SG_ 1045 VehVActlBrk_No_Cnt 1;
BA_ "U_V713N_MY2022_Rx" SG_ 1045 VehVActlBrk_No_Cnt 1;
BA_ "U_CDX74X_MY2024_Rx" SG_ 1045 VehVActlBrk_No_Cnt 1;
BA_ "MetaData" SG_ 1045 VehVActlBrk_D_Qf 1;
BA_ "U_P708_MY2023_Rx" SG_ 1045 VehVActlBrk_D_Qf 1;
BA_ "U_V710_MY2023_Rx" SG_ 1045 VehVActlBrk_D_Qf 1;
BA_ "U_P702_MY2024_Rx" SG_ 1045 VehVActlBrk_D_Qf 1;
BA_ "U_V713N_MY2022_Rx" SG_ 1045 VehVActlBrk_D_Qf 1;
BA_ "U_CDX74X_MY2024_Rx" SG_ 1045 VehVActlBrk_D_Qf 1;
BA_ "MetaData" SG_ 1044 ApaBrkErrDStat_No_Cnt 1;
BA_ "MetaData" SG_ 1044 ApaBrkErrDStat_No_Cs 1;
BA_ "GenSigStartValue" SG_ 1044 ApaBrkErr_D_Stat 2;
BA_ "GenSigStartValue" SG_ 1044 StePinOffst_An_Est 65533;
BA_ "U_V713N_MY2022_Rx" SG_ 1044 StePinOffst_An_Est 1;
BA_ "U_P708_MY2023_Rx" SG_ 1044 StePinOffst_An_Est 1;
BA_ "U_CDX74X_MY2024_Rx" SG_ 1044 StePinOffst_An_Est 1;
BA_ "U_V710_MY2023_Rx" SG_ 1044 StePinOffst_An_Est 1;
BA_ "U_P702_MY2024_Rx" SG_ 1044 StePinOffst_An_Est 1;
BA_ "MetaData" SG_ 1044 StePinOffst_No_Cs 1;
BA_ "U_V713N_MY2022_Rx" SG_ 1044 StePinOffst_No_Cs 1;
BA_ "U_P708_MY2023_Rx" SG_ 1044 StePinOffst_No_Cs 1;
BA_ "U_CDX74X_MY2024_Rx" SG_ 1044 StePinOffst_No_Cs 1;
BA_ "U_V710_MY2023_Rx" SG_ 1044 StePinOffst_No_Cs 1;
BA_ "U_P702_MY2024_Rx" SG_ 1044 StePinOffst_No_Cs 1;
BA_ "MetaData" SG_ 1044 StePinOffst_No_Cnt 1;
BA_ "U_V713N_MY2022_Rx" SG_ 1044 StePinOffst_No_Cnt 1;
BA_ "U_P708_MY2023_Rx" SG_ 1044 StePinOffst_No_Cnt 1;
BA_ "U_CDX74X_MY2024_Rx" SG_ 1044 StePinOffst_No_Cnt 1;
BA_ "U_V710_MY2023_Rx" SG_ 1044 StePinOffst_No_Cnt 1;
BA_ "U_P702_MY2024_Rx" SG_ 1044 StePinOffst_No_Cnt 1;
BA_ "U_V713N_MY2022_Rx" SG_ 1044 StePinOffst_D_Stat 1;
BA_ "U_P708_MY2023_Rx" SG_ 1044 StePinOffst_D_Stat 1;
BA_ "U_CDX74X_MY2024_Rx" SG_ 1044 StePinOffst_D_Stat 1;
BA_ "U_V710_MY2023_Rx" SG_ 1044 StePinOffst_D_Stat 1;
BA_ "U_P702_MY2024_Rx" SG_ 1044 StePinOffst_D_Stat 1;
BA_ "GenSigStartValue" SG_ 765 BalrSwtch_D_Stat 1;
BA_ "U_P708_MY2023_Rx" SG_ 765 BalrSwtch_D_Stat 1;
BA_ "U_V710_MY2023_Rx" SG_ 765 BalrSwtch_D_Stat 1;
BA_ "U_P702_MY2024_Rx" SG_ 765 BalrSwtch_D_Stat 1;
BA_ "U_P708_MY2023_Rx" SG_ 765 BalrMde_D_Rq 1;
BA_ "U_V710_MY2023_Rx" SG_ 765 BalrMde_D_Rq 1;
BA_ "U_P702_MY2024_Rx" SG_ 765 BalrMde_D_Rq 1;
BA_ "GenSigStartValue" SG_ 765 WaitToStartLamp_D_Falt 1;
BA_ "GenSigStartValue" SG_ 765 EsaOn_B_Rq 1;
BA_ "U_V713N_MY2022_Rx" SG_ 765 EsaOn_B_Rq 1;
BA_ "U_P708_MY2023_Rx" SG_ 765 EsaOn_B_Rq 1;
BA_ "U_CDX74X_MY2024_Rx" SG_ 765 EsaOn_B_Rq 1;
BA_ "U_V710_MY2023_Rx" SG_ 765 EsaOn_B_Rq 1;
BA_ "U_P702_MY2024_Rx" SG_ 765 EsaOn_B_Rq 1;
BA_ "U_P708_MY2023_Rx" SG_ 765 BttOn_B_Rq 1;
BA_ "U_V710_MY2023_Rx" SG_ 765 BttOn_B_Rq 1;
BA_ "U_P702_MY2024_Rx" SG_ 765 BttOn_B_Rq 1;
BA_ "GenSigStartValue" SG_ 765 Btt_L_Actl 126;
BA_ "U_P708_MY2023_Rx" SG_ 765 Btt_L_Actl 1;
BA_ "U_V710_MY2023_Rx" SG_ 765 Btt_L_Actl 1;
BA_ "U_P702_MY2024_Rx" SG_ 765 Btt_L_Actl 1;
BA_ "WakeupSignal" SG_ 765 DrvInputRequired_B_Rq 1;
BA_ "U_P708_MY2023_Rx" SG_ 765 DrvInputRequired_B_Rq 1;
BA_ "U_P702_MY2024_Rx" SG_ 765 DrvInputRequired_B_Rq 1;
BA_ "GenSigStartValue" SG_ 765 AwdRnge_D_ActlIpc 7;
BA_ "GenSigStartValue" SG_ 560 GboxOil_Te_Actl 254;
BA_ "GenSigStartValue" SG_ 560 GearLvrPos_D_Actl 14;
BA_ "U_P708_MY2023_Rx" SG_ 560 GearLvrPos_D_Actl 1;
BA_ "U_V710_MY2023_Rx" SG_ 560 GearLvrPos_D_Actl 1;
BA_ "U_P702_MY2024_Rx" SG_ 560 GearLvrPos_D_Actl 1;
BA_ "U_CDX74X_MY2024_Rx" SG_ 560 GearLvrPos_D_Actl 1;
BA_ "U_P708_MY2023_Rx" SG_ 559 EhData2_No_Actl 1;
BA_ "U_V710_MY2023_Rx" SG_ 559 EhData2_No_Actl 1;
BA_ "U_P702_MY2024_Rx" SG_ 559 EhData2_No_Actl 1;
BA_ "U_CDX74X_MY2024_Rx" SG_ 559 EhData2_No_Actl 1;
BA_ "GenSigStartValue" SG_ 1413 PDM_GWOnBoardTester 255;
BA_ "U_V713N_MY2022_Tx" SG_ 1413 PDM_GWOnBoardTester 1;
BA_ "U_V713AV_MY2022_Tx" SG_ 1413 PDM_GWOnBoardTester 1;
BA_ "U_P708_MY2023_Tx" SG_ 1413 PDM_GWOnBoardTester 1;
BA_ "U_V710_MY2023_Tx" SG_ 1413 PDM_GWOnBoardTester 1;
BA_ "U_P702_MY2024_Tx" SG_ 1413 PDM_GWOnBoardTester 1;
BA_ "GenSigStartValue" SG_ 1413 PDM_GWNMProxy 255;
BA_ "U_V713N_MY2022_Tx" SG_ 1413 PDM_GWNMProxy 1;
BA_ "U_V713AV_MY2022_Tx" SG_ 1413 PDM_GWNMProxy 1;
BA_ "U_P708_MY2023_Tx" SG_ 1413 PDM_GWNMProxy 1;
BA_ "U_V710_MY2023_Tx" SG_ 1413 PDM_GWNMProxy 1;
BA_ "U_P702_MY2024_Tx" SG_ 1413 PDM_GWNMProxy 1;
BA_ "GenSigStartValue" SG_ 1413 PDM_AutoSarNMReserved4 255;
BA_ "U_V713N_MY2022_Tx" SG_ 1413 PDM_AutoSarNMReserved4 1;
BA_ "U_V713AV_MY2022_Tx" SG_ 1413 PDM_AutoSarNMReserved4 1;
BA_ "U_P708_MY2023_Tx" SG_ 1413 PDM_AutoSarNMReserved4 1;
BA_ "U_V710_MY2023_Tx" SG_ 1413 PDM_AutoSarNMReserved4 1;
BA_ "U_P702_MY2024_Tx" SG_ 1413 PDM_AutoSarNMReserved4 1;
BA_ "GenSigStartValue" SG_ 1413 PDM_AutoSarNMReserved3 255;
BA_ "U_V713N_MY2022_Tx" SG_ 1413 PDM_AutoSarNMReserved3 1;
BA_ "U_V713AV_MY2022_Tx" SG_ 1413 PDM_AutoSarNMReserved3 1;
BA_ "U_P708_MY2023_Tx" SG_ 1413 PDM_AutoSarNMReserved3 1;
BA_ "U_V710_MY2023_Tx" SG_ 1413 PDM_AutoSarNMReserved3 1;
BA_ "U_P702_MY2024_Tx" SG_ 1413 PDM_AutoSarNMReserved3 1;
BA_ "GenSigStartValue" SG_ 1413 PDM_AutoSarNMReserved2 255;
BA_ "U_V713N_MY2022_Tx" SG_ 1413 PDM_AutoSarNMReserved2 1;
BA_ "U_V713AV_MY2022_Tx" SG_ 1413 PDM_AutoSarNMReserved2 1;
BA_ "U_P708_MY2023_Tx" SG_ 1413 PDM_AutoSarNMReserved2 1;
BA_ "U_V710_MY2023_Tx" SG_ 1413 PDM_AutoSarNMReserved2 1;
BA_ "U_P702_MY2024_Tx" SG_ 1413 PDM_AutoSarNMReserved2 1;
BA_ "GenSigStartValue" SG_ 1413 PDM_AutoSarNMReserved1 255;
BA_ "U_V713N_MY2022_Tx" SG_ 1413 PDM_AutoSarNMReserved1 1;
BA_ "U_V713AV_MY2022_Tx" SG_ 1413 PDM_AutoSarNMReserved1 1;
BA_ "U_P708_MY2023_Tx" SG_ 1413 PDM_AutoSarNMReserved1 1;
BA_ "U_V710_MY2023_Tx" SG_ 1413 PDM_AutoSarNMReserved1 1;
BA_ "U_P702_MY2024_Tx" SG_ 1413 PDM_AutoSarNMReserved1 1;
BA_ "GenSigStartValue" SG_ 1413 PDM_AutoSarNMNodeId 133;
BA_ "U_V713N_MY2022_Tx" SG_ 1413 PDM_AutoSarNMNodeId 1;
BA_ "U_V713AV_MY2022_Tx" SG_ 1413 PDM_AutoSarNMNodeId 1;
BA_ "U_P708_MY2023_Tx" SG_ 1413 PDM_AutoSarNMNodeId 1;
BA_ "U_V710_MY2023_Tx" SG_ 1413 PDM_AutoSarNMNodeId 1;
BA_ "U_P702_MY2024_Tx" SG_ 1413 PDM_AutoSarNMNodeId 1;
BA_ "U_V713N_MY2022_Tx" SG_ 1413 PDM_AutoSarNMControl 1;
BA_ "U_V713AV_MY2022_Tx" SG_ 1413 PDM_AutoSarNMControl 1;
BA_ "U_P708_MY2023_Tx" SG_ 1413 PDM_AutoSarNMControl 1;
BA_ "U_V710_MY2023_Tx" SG_ 1413 PDM_AutoSarNMControl 1;
BA_ "U_P702_MY2024_Tx" SG_ 1413 PDM_AutoSarNMControl 1;
BA_ "GenSigStartValue" SG_ 1412 DDM_GWOnBoardTester 255;
BA_ "U_V713N_MY2022_Tx" SG_ 1412 DDM_GWOnBoardTester 1;
BA_ "U_V713AV_MY2022_Tx" SG_ 1412 DDM_GWOnBoardTester 1;
BA_ "U_P708_MY2023_Tx" SG_ 1412 DDM_GWOnBoardTester 1;
BA_ "U_P702_MY2024_Tx" SG_ 1412 DDM_GWOnBoardTester 1;
BA_ "GenSigStartValue" SG_ 1412 DDM_GWNMProxy 255;
BA_ "U_V713N_MY2022_Tx" SG_ 1412 DDM_GWNMProxy 1;
BA_ "U_V713AV_MY2022_Tx" SG_ 1412 DDM_GWNMProxy 1;
BA_ "U_P708_MY2023_Tx" SG_ 1412 DDM_GWNMProxy 1;
BA_ "U_P702_MY2024_Tx" SG_ 1412 DDM_GWNMProxy 1;
BA_ "GenSigStartValue" SG_ 1412 DDM_AutoSarNMReserved4 255;
BA_ "U_V713N_MY2022_Tx" SG_ 1412 DDM_AutoSarNMReserved4 1;
BA_ "U_V713AV_MY2022_Tx" SG_ 1412 DDM_AutoSarNMReserved4 1;
BA_ "U_P708_MY2023_Tx" SG_ 1412 DDM_AutoSarNMReserved4 1;
BA_ "U_P702_MY2024_Tx" SG_ 1412 DDM_AutoSarNMReserved4 1;
BA_ "GenSigStartValue" SG_ 1412 DDM_AutoSarNMReserved3 255;
BA_ "U_V713N_MY2022_Tx" SG_ 1412 DDM_AutoSarNMReserved3 1;
BA_ "U_V713AV_MY2022_Tx" SG_ 1412 DDM_AutoSarNMReserved3 1;
BA_ "U_P708_MY2023_Tx" SG_ 1412 DDM_AutoSarNMReserved3 1;
BA_ "U_P702_MY2024_Tx" SG_ 1412 DDM_AutoSarNMReserved3 1;
BA_ "GenSigStartValue" SG_ 1412 DDM_AutoSarNMReserved2 255;
BA_ "U_V713N_MY2022_Tx" SG_ 1412 DDM_AutoSarNMReserved2 1;
BA_ "U_V713AV_MY2022_Tx" SG_ 1412 DDM_AutoSarNMReserved2 1;
BA_ "U_P708_MY2023_Tx" SG_ 1412 DDM_AutoSarNMReserved2 1;
BA_ "U_P702_MY2024_Tx" SG_ 1412 DDM_AutoSarNMReserved2 1;
BA_ "GenSigStartValue" SG_ 1412 DDM_AutoSarNMReserved1 255;
BA_ "U_V713N_MY2022_Tx" SG_ 1412 DDM_AutoSarNMReserved1 1;
BA_ "U_V713AV_MY2022_Tx" SG_ 1412 DDM_AutoSarNMReserved1 1;
BA_ "U_P708_MY2023_Tx" SG_ 1412 DDM_AutoSarNMReserved1 1;
BA_ "U_P702_MY2024_Tx" SG_ 1412 DDM_AutoSarNMReserved1 1;
BA_ "GenSigStartValue" SG_ 1412 DDM_AutoSarNMNodeId 132;
BA_ "U_V713N_MY2022_Tx" SG_ 1412 DDM_AutoSarNMNodeId 1;
BA_ "U_V713AV_MY2022_Tx" SG_ 1412 DDM_AutoSarNMNodeId 1;
BA_ "U_P708_MY2023_Tx" SG_ 1412 DDM_AutoSarNMNodeId 1;
BA_ "U_P702_MY2024_Tx" SG_ 1412 DDM_AutoSarNMNodeId 1;
BA_ "U_V713N_MY2022_Tx" SG_ 1412 DDM_AutoSarNMControl 1;
BA_ "U_V713AV_MY2022_Tx" SG_ 1412 DDM_AutoSarNMControl 1;
BA_ "U_P708_MY2023_Tx" SG_ 1412 DDM_AutoSarNMControl 1;
BA_ "U_P702_MY2024_Tx" SG_ 1412 DDM_AutoSarNMControl 1;
BA_ "GenSigSendType" SG_ 1822 TesterPhysicalResGWM_F3 3;
BA_ "ECGUsedTxSignal" SG_ 1822 TesterPhysicalResGWM_F3 1;
BA_ "U_P708_MY2023_Tx" SG_ 1822 TesterPhysicalResGWM_F3 1;
BA_ "U_CDX74X_MY2024_Tx" SG_ 1822 TesterPhysicalResGWM_F3 1;
BA_ "U_V710_MY2023_Tx" SG_ 1822 TesterPhysicalResGWM_F3 1;
BA_ "U_P702_MY2024_Tx" SG_ 1822 TesterPhysicalResGWM_F3 1;
BA_ "GenSigSendType" SG_ 1878 TesterPhysicalReqPBM 3;
BA_ "GenSigSendType" SG_ 2610097368 OTAPhysGWM_ECGtoCMR 3;
BA_ "ECGUsedTxSignal" SG_ 2610097368 OTAPhysGWM_ECGtoCMR 1;
BA_ "U_P708_MY2023_Tx" SG_ 2610097368 OTAPhysGWM_ECGtoCMR 1;
BA_ "U_CDX74X_MY2024_Tx" SG_ 2610097368 OTAPhysGWM_ECGtoCMR 1;
BA_ "U_V710_MY2023_Tx" SG_ 2610097368 OTAPhysGWM_ECGtoCMR 1;
BA_ "U_P702_MY2024_Tx" SG_ 2610097368 OTAPhysGWM_ECGtoCMR 1;
BA_ "GenSigSendType" SG_ 1778 TesterPhysicalReqSODCMC 3;
BA_ "U_P708_MY2023_Rx" SG_ 1778 TesterPhysicalReqSODCMC 1;
BA_ "U_V710_MY2023_Rx" SG_ 1778 TesterPhysicalReqSODCMC 1;
BA_ "U_P702_MY2024_Rx" SG_ 1778 TesterPhysicalReqSODCMC 1;
BA_ "GenSigStartValue" SG_ 551 ChrgToPcEdit_Pc_RqMnu 126;
BA_ "WakeupSignal" SG_ 551 Cntr_Plg_Mode_Cmd 1;
BA_ "GenSigStartValue" SG_ 551 Btt_L_Actl2 126;
BA_ "U_P708_MY2023_Rx" SG_ 551 Btt_L_Actl2 1;
BA_ "U_V710_MY2023_Rx" SG_ 551 Btt_L_Actl2 1;
BA_ "U_P702_MY2024_Rx" SG_ 551 Btt_L_Actl2 1;
BA_ "U_P708_MY2023_Rx" SG_ 551 Rba_D_Rq 1;
BA_ "U_V710_MY2023_Rx" SG_ 551 Rba_D_Rq 1;
BA_ "U_P702_MY2024_Rx" SG_ 551 Rba_D_Rq 1;
BA_ "U_P708_MY2023_Rx" SG_ 551 EmPrflNo_D_Rq 1;
BA_ "U_P702_MY2024_Rx" SG_ 551 EmPrflNo_D_Rq 1;
BA_ "U_P708_MY2023_Rx" SG_ 551 EmPrflKeyAssoc_D_Rq 1;
BA_ "U_P702_MY2024_Rx" SG_ 551 EmPrflKeyAssoc_D_Rq 1;
BA_ "WakeupSignal" SG_ 551 Em_D_Stat 1;
BA_ "U_P708_MY2023_Rx" SG_ 551 TjaLaneBiasEnbl_D_RqMnu 1;
BA_ "U_V710_MY2023_Rx" SG_ 551 TjaLaneBiasEnbl_D_RqMnu 1;
BA_ "U_P702_MY2024_Rx" SG_ 551 TjaLaneBiasEnbl_D_RqMnu 1;
BA_ "U_P708_MY2023_Rx" SG_ 358 HiElPwInhbt_B_Stat 1;
BA_ "U_P702_MY2024_Rx" SG_ 358 HiElPwInhbt_B_Stat 1;
BA_ "GenSigSendType" SG_ 673 ICI_Coding_BtnID_D 3;
BA_ "U_V713N_MY2022_Tx" SG_ 673 ICI_Coding_BtnID_D 1;
BA_ "U_V713AV_MY2022_Tx" SG_ 673 ICI_Coding_BtnID_D 1;
BA_ "U_P708_MY2023_Tx" SG_ 673 ICI_Coding_BtnID_D 1;
BA_ "U_V710_MY2023_Tx" SG_ 673 ICI_Coding_BtnID_D 1;
BA_ "U_P702_MY2024_Tx" SG_ 673 ICI_Coding_BtnID_D 1;
BA_ "GenSigSendType" SG_ 673 ICI_Coding_BtnID_C 3;
BA_ "U_V713N_MY2022_Tx" SG_ 673 ICI_Coding_BtnID_C 1;
BA_ "U_V713AV_MY2022_Tx" SG_ 673 ICI_Coding_BtnID_C 1;
BA_ "U_P708_MY2023_Tx" SG_ 673 ICI_Coding_BtnID_C 1;
BA_ "U_V710_MY2023_Tx" SG_ 673 ICI_Coding_BtnID_C 1;
BA_ "U_P702_MY2024_Tx" SG_ 673 ICI_Coding_BtnID_C 1;
BA_ "GenSigSendType" SG_ 673 ICI_Coding_BtnID_B 3;
BA_ "U_V713N_MY2022_Tx" SG_ 673 ICI_Coding_BtnID_B 1;
BA_ "U_V713AV_MY2022_Tx" SG_ 673 ICI_Coding_BtnID_B 1;
BA_ "U_P708_MY2023_Tx" SG_ 673 ICI_Coding_BtnID_B 1;
BA_ "U_V710_MY2023_Tx" SG_ 673 ICI_Coding_BtnID_B 1;
BA_ "U_P702_MY2024_Tx" SG_ 673 ICI_Coding_BtnID_B 1;
BA_ "GenSigSendType" SG_ 673 ICI_Coding_BtnID_A 3;
BA_ "U_V713N_MY2022_Tx" SG_ 673 ICI_Coding_BtnID_A 1;
BA_ "U_V713AV_MY2022_Tx" SG_ 673 ICI_Coding_BtnID_A 1;
BA_ "U_P708_MY2023_Tx" SG_ 673 ICI_Coding_BtnID_A 1;
BA_ "U_V710_MY2023_Tx" SG_ 673 ICI_Coding_BtnID_A 1;
BA_ "U_P702_MY2024_Tx" SG_ 673 ICI_Coding_BtnID_A 1;
BA_ "GenSigStartValue" SG_ 673 ICI_BtnID_D 255;
BA_ "GenSigSendType" SG_ 673 ICI_BtnID_D 3;
BA_ "U_V713N_MY2022_Tx" SG_ 673 ICI_BtnID_D 1;
BA_ "U_V713AV_MY2022_Tx" SG_ 673 ICI_BtnID_D 1;
BA_ "U_P708_MY2023_Tx" SG_ 673 ICI_BtnID_D 1;
BA_ "U_V710_MY2023_Tx" SG_ 673 ICI_BtnID_D 1;
BA_ "U_P702_MY2024_Tx" SG_ 673 ICI_BtnID_D 1;
BA_ "GenSigStartValue" SG_ 673 ICI_BtnID_C 255;
BA_ "GenSigSendType" SG_ 673 ICI_BtnID_C 3;
BA_ "U_V713N_MY2022_Tx" SG_ 673 ICI_BtnID_C 1;
BA_ "U_V713AV_MY2022_Tx" SG_ 673 ICI_BtnID_C 1;
BA_ "U_P708_MY2023_Tx" SG_ 673 ICI_BtnID_C 1;
BA_ "U_V710_MY2023_Tx" SG_ 673 ICI_BtnID_C 1;
BA_ "U_P702_MY2024_Tx" SG_ 673 ICI_BtnID_C 1;
BA_ "GenSigStartValue" SG_ 673 ICI_BtnID_B 255;
BA_ "GenSigSendType" SG_ 673 ICI_BtnID_B 3;
BA_ "U_V713N_MY2022_Tx" SG_ 673 ICI_BtnID_B 1;
BA_ "U_V713AV_MY2022_Tx" SG_ 673 ICI_BtnID_B 1;
BA_ "U_P708_MY2023_Tx" SG_ 673 ICI_BtnID_B 1;
BA_ "U_V710_MY2023_Tx" SG_ 673 ICI_BtnID_B 1;
BA_ "U_P702_MY2024_Tx" SG_ 673 ICI_BtnID_B 1;
BA_ "GenSigStartValue" SG_ 673 ICI_BtnID_A 255;
BA_ "GenSigSendType" SG_ 673 ICI_BtnID_A 3;
BA_ "U_V713N_MY2022_Tx" SG_ 673 ICI_BtnID_A 1;
BA_ "U_V713AV_MY2022_Tx" SG_ 673 ICI_BtnID_A 1;
BA_ "U_P708_MY2023_Tx" SG_ 673 ICI_BtnID_A 1;
BA_ "U_V710_MY2023_Tx" SG_ 673 ICI_BtnID_A 1;
BA_ "U_P702_MY2024_Tx" SG_ 673 ICI_BtnID_A 1;
BA_ "GenSigStartValue" SG_ 990 PersIndexDdm_D_Actl 4;
BA_ "GenSigSendType" SG_ 990 PersIndexDdm_D_Actl 3;
BA_ "U_P708_MY2023_Tx" SG_ 990 PersIndexDdm_D_Actl 1;
BA_ "U_P702_MY2024_Tx" SG_ 990 PersIndexDdm_D_Actl 1;
BA_ "GenSigSendType" SG_ 990 FeatNoDdm_No_Actl 3;
BA_ "U_P708_MY2023_Tx" SG_ 990 FeatNoDdm_No_Actl 1;
BA_ "U_P702_MY2024_Tx" SG_ 990 FeatNoDdm_No_Actl 1;
BA_ "GenSigSendType" SG_ 990 FeatConfigDdmActl 3;
BA_ "U_P708_MY2023_Tx" SG_ 990 FeatConfigDdmActl 1;
BA_ "U_P702_MY2024_Tx" SG_ 990 FeatConfigDdmActl 1;
BA_ "GenSigStartValue" SG_ 1100 WakeAlarm1_T_Rq 32767;
BA_ "WakeupSignal" SG_ 1100 WakeAlarm1_B_Typ 1;
BA_ "GenSigStartValue" SG_ 1100 GrossTrainWeight_M_Est 254;
BA_ "U_P708_MY2023_Rx" SG_ 1100 GrossTrainWeight_M_Est 1;
BA_ "U_V710_MY2023_Rx" SG_ 1100 GrossTrainWeight_M_Est 1;
BA_ "U_P702_MY2024_Rx" SG_ 1100 GrossTrainWeight_M_Est 1;
BA_ "U_V713N_MY2022_Rx" SG_ 1100 GrossTrainWeight_M_Est 1;
BA_ "U_CDX74X_MY2024_Rx" SG_ 1100 GrossTrainWeight_M_Est 1;
BA_ "GenSigStartValue" SG_ 1091 WakeAlarm2_T_Rq 32767;
BA_ "U_P708_MY2023_Rx" SG_ 1091 TrlrLampCnnct_B_Actl 1;
BA_ "U_V710_MY2023_Rx" SG_ 1091 TrlrLampCnnct_B_Actl 1;
BA_ "U_P702_MY2024_Rx" SG_ 1091 TrlrLampCnnct_B_Actl 1;
BA_ "GenSigSendType" SG_ 819 WndwPsngrSide_D_Stat 3;
BA_ "U_V713N_MY2022_Tx" SG_ 819 WndwPsngrSide_D_Stat 1;
BA_ "U_V713AV_MY2022_Tx" SG_ 819 WndwPsngrSide_D_Stat 1;
BA_ "U_P708_MY2023_Tx" SG_ 819 WndwPsngrSide_D_Stat 1;
BA_ "U_V710_MY2023_Tx" SG_ 819 WndwPsngrSide_D_Stat 1;
BA_ "U_P702_MY2024_Tx" SG_ 819 WndwPsngrSide_D_Stat 1;
BA_ "GenSigSendType" SG_ 819 BLISLEDStatPassSide 3;
BA_ "U_P708_MY2023_Rx" SG_ 819 BLISLEDStatPassSide 1;
BA_ "U_V710_MY2023_Rx" SG_ 819 BLISLEDStatPassSide 1;
BA_ "U_P702_MY2024_Rx" SG_ 819 BLISLEDStatPassSide 1;
BA_ "U_V713N_MY2022_Tx" SG_ 819 BLISLEDStatPassSide 1;
BA_ "U_P708_MY2023_Tx" SG_ 819 BLISLEDStatPassSide 1;
BA_ "U_V710_MY2023_Tx" SG_ 819 BLISLEDStatPassSide 1;
BA_ "U_P702_MY2024_Tx" SG_ 819 BLISLEDStatPassSide 1;
BA_ "U_V713N_MY2022_Tx" SG_ 819 RollCode_No_ActlPdm 1;
BA_ "U_P708_MY2023_Tx" SG_ 819 RollCode_No_ActlPdm 1;
BA_ "U_V710_MY2023_Tx" SG_ 819 RollCode_No_ActlPdm 1;
BA_ "U_P702_MY2024_Tx" SG_ 819 RollCode_No_ActlPdm 1;
BA_ "WakeupSignal" SG_ 819 Pasngr_Lock_Sw_Stat 1;
BA_ "GenSigSendType" SG_ 819 Pasngr_Lock_Sw_Stat 3;
BA_ "U_V713N_MY2022_Tx" SG_ 819 Pasngr_Lock_Sw_Stat 1;
BA_ "U_P708_MY2023_Tx" SG_ 819 Pasngr_Lock_Sw_Stat 1;
BA_ "U_V710_MY2023_Tx" SG_ 819 Pasngr_Lock_Sw_Stat 1;
BA_ "U_P702_MY2024_Tx" SG_ 819 Pasngr_Lock_Sw_Stat 1;
BA_ "WakeupSignal" SG_ 819 Pasngr_Lock_Sw_Cnt 1;
BA_ "MetaData" SG_ 819 Pasngr_Lock_Sw_Cnt 1;
BA_ "GenSigSendType" SG_ 819 Pasngr_Lock_Sw_Cnt 3;
BA_ "U_V713N_MY2022_Tx" SG_ 819 Pasngr_Lock_Sw_Cnt 1;
BA_ "U_P708_MY2023_Tx" SG_ 819 Pasngr_Lock_Sw_Cnt 1;
BA_ "U_V710_MY2023_Tx" SG_ 819 Pasngr_Lock_Sw_Cnt 1;
BA_ "U_P702_MY2024_Tx" SG_ 819 Pasngr_Lock_Sw_Cnt 1;
BA_ "WakeupSignal" SG_ 819 ChildLckFdbckRp_B_Stat 1;
BA_ "GenSigSendType" SG_ 819 ChildLckFdbckRp_B_Stat 3;
BA_ "U_V713N_MY2022_Tx" SG_ 819 ChildLckFdbckRp_B_Stat 1;
BA_ "U_P708_MY2023_Tx" SG_ 819 ChildLckFdbckRp_B_Stat 1;
BA_ "U_V710_MY2023_Tx" SG_ 819 ChildLckFdbckRp_B_Stat 1;
BA_ "U_P702_MY2024_Tx" SG_ 819 ChildLckFdbckRp_B_Stat 1;
BA_ "GenSigSendType" SG_ 818 DrvSpotLight_B_Stat 3;
BA_ "U_P708_MY2023_Rx" SG_ 818 DrvSpotLight_B_Stat 1;
BA_ "U_P702_MY2024_Rx" SG_ 818 DrvSpotLight_B_Stat 1;
BA_ "U_P708_MY2023_Tx" SG_ 818 DrvSpotLight_B_Stat 1;
BA_ "U_P702_MY2024_Tx" SG_ 818 DrvSpotLight_B_Stat 1;
BA_ "GenSigSendType" SG_ 818 WndwDrvSide_D_Stat 3;
BA_ "U_V713N_MY2022_Tx" SG_ 818 WndwDrvSide_D_Stat 1;
BA_ "U_P708_MY2023_Tx" SG_ 818 WndwDrvSide_D_Stat 1;
BA_ "U_P702_MY2024_Tx" SG_ 818 WndwDrvSide_D_Stat 1;
BA_ "GenSigSendType" SG_ 818 RvrseMirrorChime_B_Rq 3;
BA_ "U_P708_MY2023_Tx" SG_ 818 RvrseMirrorChime_B_Rq 1;
BA_ "U_P702_MY2024_Tx" SG_ 818 RvrseMirrorChime_B_Rq 1;
BA_ "GenSigSendType" SG_ 818 BLISLEDStatDriverSide 3;
BA_ "U_P708_MY2023_Rx" SG_ 818 BLISLEDStatDriverSide 1;
BA_ "U_V710_MY2023_Rx" SG_ 818 BLISLEDStatDriverSide 1;
BA_ "U_P702_MY2024_Rx" SG_ 818 BLISLEDStatDriverSide 1;
BA_ "U_V713N_MY2022_Tx" SG_ 818 BLISLEDStatDriverSide 1;
BA_ "U_P708_MY2023_Tx" SG_ 818 BLISLEDStatDriverSide 1;
BA_ "U_P702_MY2024_Tx" SG_ 818 BLISLEDStatDriverSide 1;
BA_ "WakeupSignal" SG_ 818 ChildLckPw_N_Cnt 1;
BA_ "GenSigSendType" SG_ 818 ChildLckPw_N_Cnt 3;
BA_ "U_P708_MY2023_Tx" SG_ 818 ChildLckPw_N_Cnt 1;
BA_ "U_P702_MY2024_Tx" SG_ 818 ChildLckPw_N_Cnt 1;
BA_ "GenSigSendType" SG_ 818 RollCodeDrvDrKeyCyl 3;
BA_ "U_V713N_MY2022_Tx" SG_ 818 RollCodeDrvDrKeyCyl 1;
BA_ "U_P708_MY2023_Tx" SG_ 818 RollCodeDrvDrKeyCyl 1;
BA_ "U_P702_MY2024_Tx" SG_ 818 RollCodeDrvDrKeyCyl 1;
BA_ "WakeupSignal" SG_ 818 KeyCylSwDrvDr_D_Stat 1;
BA_ "GenSigSendType" SG_ 818 KeyCylSwDrvDr_D_Stat 3;
BA_ "U_V713N_MY2022_Tx" SG_ 818 KeyCylSwDrvDr_D_Stat 1;
BA_ "U_P708_MY2023_Tx" SG_ 818 KeyCylSwDrvDr_D_Stat 1;
BA_ "U_P702_MY2024_Tx" SG_ 818 KeyCylSwDrvDr_D_Stat 1;
BA_ "WakeupSignal" SG_ 818 Driver_Lock_Sw_Stat 1;
BA_ "GenSigSendType" SG_ 818 Driver_Lock_Sw_Stat 3;
BA_ "U_V713N_MY2022_Tx" SG_ 818 Driver_Lock_Sw_Stat 1;
BA_ "U_P708_MY2023_Tx" SG_ 818 Driver_Lock_Sw_Stat 1;
BA_ "U_P702_MY2024_Tx" SG_ 818 Driver_Lock_Sw_Stat 1;
BA_ "WakeupSignal" SG_ 818 Driver_Lock_Sw_Cnt 1;
BA_ "MetaData" SG_ 818 Driver_Lock_Sw_Cnt 1;
BA_ "GenSigSendType" SG_ 818 Driver_Lock_Sw_Cnt 3;
BA_ "U_V713N_MY2022_Tx" SG_ 818 Driver_Lock_Sw_Cnt 1;
BA_ "U_P708_MY2023_Tx" SG_ 818 Driver_Lock_Sw_Cnt 1;
BA_ "U_P702_MY2024_Tx" SG_ 818 Driver_Lock_Sw_Cnt 1;
BA_ "WakeupSignal" SG_ 818 ChildLckPw_D_Rq 1;
BA_ "GenSigSendType" SG_ 818 ChildLckPw_D_Rq 3;
BA_ "U_V713N_MY2022_Tx" SG_ 818 ChildLckPw_D_Rq 1;
BA_ "U_P708_MY2023_Tx" SG_ 818 ChildLckPw_D_Rq 1;
BA_ "U_P702_MY2024_Tx" SG_ 818 ChildLckPw_D_Rq 1;
BA_ "WakeupSignal" SG_ 818 ChildLckFdbckRd_B_Stat 1;
BA_ "GenSigSendType" SG_ 818 ChildLckFdbckRd_B_Stat 3;
BA_ "U_V713N_MY2022_Tx" SG_ 818 ChildLckFdbckRd_B_Stat 1;
BA_ "U_P708_MY2023_Tx" SG_ 818 ChildLckFdbckRd_B_Stat 1;
BA_ "U_P702_MY2024_Tx" SG_ 818 ChildLckFdbckRd_B_Stat 1;
BA_ "GenSigSendType" SG_ 1865 TesterPhysicalResPDM 3;
BA_ "U_V713N_MY2022_Tx" SG_ 1865 TesterPhysicalResPDM 1;
BA_ "U_V713AV_MY2022_Tx" SG_ 1865 TesterPhysicalResPDM 1;
BA_ "U_P708_MY2023_Tx" SG_ 1865 TesterPhysicalResPDM 1;
BA_ "U_V710_MY2023_Tx" SG_ 1865 TesterPhysicalResPDM 1;
BA_ "U_P702_MY2024_Tx" SG_ 1865 TesterPhysicalResPDM 1;
BA_ "GenSigSendType" SG_ 1857 TesterPhysicalReqPDM 3;
BA_ "U_P708_MY2023_Rx" SG_ 1857 TesterPhysicalReqPDM 1;
BA_ "U_P702_MY2024_Rx" SG_ 1857 TesterPhysicalReqPDM 1;
BA_ "GenSigStartValue" SG_ 1046 HsaMde_D_Mem 1;
BA_ "U_P708_MY2023_Rx" SG_ 1046 DrvSlipCtlMde_D_Ind 1;
BA_ "U_V710_MY2023_Rx" SG_ 1046 DrvSlipCtlMde_D_Ind 1;
BA_ "U_P702_MY2024_Rx" SG_ 1046 DrvSlipCtlMde_D_Ind 1;
BA_ "U_P708_MY2023_Rx" SG_ 1046 DrvAntiLckLamp_D_Rq 1;
BA_ "U_V710_MY2023_Rx" SG_ 1046 DrvAntiLckLamp_D_Rq 1;
BA_ "U_P702_MY2024_Rx" SG_ 1046 DrvAntiLckLamp_D_Rq 1;
BA_ "GenSigStartValue" SG_ 1046 StabCtlBrk_B_Avail 1;
BA_ "GenSigStartValue" SG_ 1046 RearDiffLck_Tq2_RqMx 4094;
BA_ "U_P708_MY2023_Rx" SG_ 1046 TCMode 1;
BA_ "U_V710_MY2023_Rx" SG_ 1046 TCMode 1;
BA_ "U_P702_MY2024_Rx" SG_ 1046 TCMode 1;
BA_ "U_P708_MY2023_Rx" SG_ 1046 DrvSlipCtlLamp_D_Rq 1;
BA_ "U_V710_MY2023_Rx" SG_ 1046 DrvSlipCtlLamp_D_Rq 1;
BA_ "U_P702_MY2024_Rx" SG_ 1046 DrvSlipCtlLamp_D_Rq 1;
BA_ "MetaData" SG_ 1046 BpedMove_No_Cnt 1;
BA_ "GenSigStartValue" SG_ 1046 BpedMove_D_Actl 3;
BA_ "MetaData" SG_ 342 EngClntTe_D_Qf 1;
BA_ "GenSigStartValue" SG_ 369 TrnIpcDsplyRng2_D_Actl 15;
BA_ "U_P702_MY2024_Rx" SG_ 369 TrnIpcDsplyMde_D_Actl 1;
BA_ "U_V710_MY2023_Rx" SG_ 369 TrnIpcDsplyMde_D_Actl 1;
BA_ "U_CDX74X_MY2024_Rx" SG_ 369 TrnIpcDsplyMde_D_Actl 1;
BA_ "U_CDX707_MY2023_Rx" SG_ 369 TrnIpcDsplyMde_D_Actl 1;
BA_ "WakeupSignal" SG_ 369 TrnIpcDsplyMde_D_Actl 1;
BA_ "U_P702_MY2024_Rx" SG_ 369 TrnIpcDsplyMde_D_Stat 1;
BA_ "U_V710_MY2023_Rx" SG_ 369 TrnIpcDsplyMde_D_Stat 1;
BA_ "U_CDX74X_MY2024_Rx" SG_ 369 TrnIpcDsplyMde_D_Stat 1;
BA_ "U_CDX707_MY2023_Rx" SG_ 369 TrnIpcDsplyMde_D_Stat 1;
BA_ "WakeupSignal" SG_ 369 TrnIpcDsplyMde_D_Stat 1;
BA_ "GenSigStartValue" SG_ 369 TrnIpcDsplyGear_D_Actl 15;
BA_ "MetaData" SG_ 369 TrnIpcDsplyMdeDActl_No_Cs 1;
BA_ "ContentDependant" SG_ 369 TrnIpcDsplyMdeDActl_No_Cs 1;
BA_ "MetaData" SG_ 369 TrnIpcDsplyMdeDActl_No_Cnt 1;
BA_ "ContentDependant" SG_ 369 TrnIpcDsplyMdeDActl_No_Cnt 1;
BA_ "GenSigSendType" SG_ 1842 TesterPhysicalReqGSM 3;
BA_ "GenSigSendType" SG_ 2612002008 PARSEDFuncGWM_ECG 3;
BA_ "U_P708_MY2023_Rx" SG_ 2612002008 PARSEDFuncGWM_ECG 1;
BA_ "U_V710_MY2023_Rx" SG_ 2612002008 PARSEDFuncGWM_ECG 1;
BA_ "U_P702_MY2024_Rx" SG_ 2612002008 PARSEDFuncGWM_ECG 1;
BA_ "U_V713N_MY2022_Rx" SG_ 2612002008 PARSEDFuncGWM_ECG 1;
BA_ "U_CDX74X_MY2024_Rx" SG_ 2612002008 PARSEDFuncGWM_ECG 1;
BA_ "ECGUsedTxSignal" SG_ 2612002008 PARSEDFuncGWM_ECG 1;
BA_ "U_P708_MY2023_Tx" SG_ 2612002008 PARSEDFuncGWM_ECG 1;
BA_ "U_CDX74X_MY2024_Tx" SG_ 2612002008 PARSEDFuncGWM_ECG 1;
BA_ "U_V710_MY2023_Tx" SG_ 2612002008 PARSEDFuncGWM_ECG 1;
BA_ "U_P702_MY2024_Tx" SG_ 2612002008 PARSEDFuncGWM_ECG 1;
BA_ "GenSigSendType" SG_ 2610953432 OTAFuncGWM_ECG 3;
BA_ "U_P708_MY2023_Rx" SG_ 2610953432 OTAFuncGWM_ECG 1;
BA_ "U_V710_MY2023_Rx" SG_ 2610953432 OTAFuncGWM_ECG 1;
BA_ "U_P702_MY2024_Rx" SG_ 2610953432 OTAFuncGWM_ECG 1;
BA_ "U_V713N_MY2022_Rx" SG_ 2610953432 OTAFuncGWM_ECG 1;
BA_ "U_CDX74X_MY2024_Rx" SG_ 2610953432 OTAFuncGWM_ECG 1;
BA_ "ECGUsedTxSignal" SG_ 2610953432 OTAFuncGWM_ECG 1;
BA_ "U_P708_MY2023_Tx" SG_ 2610953432 OTAFuncGWM_ECG 1;
BA_ "U_CDX74X_MY2024_Tx" SG_ 2610953432 OTAFuncGWM_ECG 1;
BA_ "U_V710_MY2023_Tx" SG_ 2610953432 OTAFuncGWM_ECG 1;
BA_ "U_P702_MY2024_Tx" SG_ 2610953432 OTAFuncGWM_ECG 1;
BA_ "GenSigStartValue" SG_ 862 ClimtThrmlLoad_No_Actl 255;
BA_ "GenSigStartValue" SG_ 1459 SCCM_GWOnBoardTester 255;
BA_ "U_V713N_MY2022_Tx" SG_ 1459 SCCM_GWOnBoardTester 1;
BA_ "U_V713AV_MY2022_Tx" SG_ 1459 SCCM_GWOnBoardTester 1;
BA_ "U_P708_MY2023_Tx" SG_ 1459 SCCM_GWOnBoardTester 1;
BA_ "U_V710_MY2023_Tx" SG_ 1459 SCCM_GWOnBoardTester 1;
BA_ "U_P702_MY2024_Tx" SG_ 1459 SCCM_GWOnBoardTester 1;
BA_ "GenSigStartValue" SG_ 1459 SCCM_GWNMProxy 255;
BA_ "U_V713N_MY2022_Tx" SG_ 1459 SCCM_GWNMProxy 1;
BA_ "U_V713AV_MY2022_Tx" SG_ 1459 SCCM_GWNMProxy 1;
BA_ "U_P708_MY2023_Tx" SG_ 1459 SCCM_GWNMProxy 1;
BA_ "U_V710_MY2023_Tx" SG_ 1459 SCCM_GWNMProxy 1;
BA_ "U_P702_MY2024_Tx" SG_ 1459 SCCM_GWNMProxy 1;
BA_ "GenSigStartValue" SG_ 1459 SCCM_AutoSarNMReserved4 255;
BA_ "U_V713N_MY2022_Tx" SG_ 1459 SCCM_AutoSarNMReserved4 1;
BA_ "U_V713AV_MY2022_Tx" SG_ 1459 SCCM_AutoSarNMReserved4 1;
BA_ "U_P708_MY2023_Tx" SG_ 1459 SCCM_AutoSarNMReserved4 1;
BA_ "U_V710_MY2023_Tx" SG_ 1459 SCCM_AutoSarNMReserved4 1;
BA_ "U_P702_MY2024_Tx" SG_ 1459 SCCM_AutoSarNMReserved4 1;
BA_ "GenSigStartValue" SG_ 1459 SCCM_AutoSarNMReserved3 255;
BA_ "U_V713N_MY2022_Tx" SG_ 1459 SCCM_AutoSarNMReserved3 1;
BA_ "U_V713AV_MY2022_Tx" SG_ 1459 SCCM_AutoSarNMReserved3 1;
BA_ "U_P708_MY2023_Tx" SG_ 1459 SCCM_AutoSarNMReserved3 1;
BA_ "U_V710_MY2023_Tx" SG_ 1459 SCCM_AutoSarNMReserved3 1;
BA_ "U_P702_MY2024_Tx" SG_ 1459 SCCM_AutoSarNMReserved3 1;
BA_ "GenSigStartValue" SG_ 1459 SCCM_AutoSarNMReserved2 255;
BA_ "U_V713N_MY2022_Tx" SG_ 1459 SCCM_AutoSarNMReserved2 1;
BA_ "U_V713AV_MY2022_Tx" SG_ 1459 SCCM_AutoSarNMReserved2 1;
BA_ "U_P708_MY2023_Tx" SG_ 1459 SCCM_AutoSarNMReserved2 1;
BA_ "U_V710_MY2023_Tx" SG_ 1459 SCCM_AutoSarNMReserved2 1;
BA_ "U_P702_MY2024_Tx" SG_ 1459 SCCM_AutoSarNMReserved2 1;
BA_ "GenSigStartValue" SG_ 1459 SCCM_AutoSarNMReserved1 255;
BA_ "U_V713N_MY2022_Tx" SG_ 1459 SCCM_AutoSarNMReserved1 1;
BA_ "U_V713AV_MY2022_Tx" SG_ 1459 SCCM_AutoSarNMReserved1 1;
BA_ "U_P708_MY2023_Tx" SG_ 1459 SCCM_AutoSarNMReserved1 1;
BA_ "U_V710_MY2023_Tx" SG_ 1459 SCCM_AutoSarNMReserved1 1;
BA_ "U_P702_MY2024_Tx" SG_ 1459 SCCM_AutoSarNMReserved1 1;
BA_ "GenSigStartValue" SG_ 1459 SCCM_AutoSarNMNodeId 179;
BA_ "U_V713N_MY2022_Tx" SG_ 1459 SCCM_AutoSarNMNodeId 1;
BA_ "U_V713AV_MY2022_Tx" SG_ 1459 SCCM_AutoSarNMNodeId 1;
BA_ "U_P708_MY2023_Tx" SG_ 1459 SCCM_AutoSarNMNodeId 1;
BA_ "U_V710_MY2023_Tx" SG_ 1459 SCCM_AutoSarNMNodeId 1;
BA_ "U_P702_MY2024_Tx" SG_ 1459 SCCM_AutoSarNMNodeId 1;
BA_ "U_V713N_MY2022_Tx" SG_ 1459 SCCM_AutoSarNMControl 1;
BA_ "U_V713AV_MY2022_Tx" SG_ 1459 SCCM_AutoSarNMControl 1;
BA_ "U_P708_MY2023_Tx" SG_ 1459 SCCM_AutoSarNMControl 1;
BA_ "U_V710_MY2023_Tx" SG_ 1459 SCCM_AutoSarNMControl 1;
BA_ "U_P702_MY2024_Tx" SG_ 1459 SCCM_AutoSarNMControl 1;
BA_ "MetaData" SG_ 146 VehLatLongVertA_No_Cs 1;
BA_ "U_P708_MY2023_Rx" SG_ 146 VehLatLongVertA_No_Cs 1;
BA_ "U_V710_MY2023_Rx" SG_ 146 VehLatLongVertA_No_Cs 1;
BA_ "U_P702_MY2024_Rx" SG_ 146 VehLatLongVertA_No_Cs 1;
BA_ "MetaData" SG_ 146 VehVertAActl_D_Qf 1;
BA_ "GenSigStartValue" SG_ 146 VehVertAActl_D_Qf 1;
BA_ "U_P708_MY2023_Rx" SG_ 146 VehVertAActl_D_Qf 1;
BA_ "U_V710_MY2023_Rx" SG_ 146 VehVertAActl_D_Qf 1;
BA_ "U_P702_MY2024_Rx" SG_ 146 VehVertAActl_D_Qf 1;
BA_ "GenSigStartValue" SG_ 146 VehVert2_A_Actl 8190;
BA_ "U_P708_MY2023_Rx" SG_ 146 VehVert2_A_Actl 1;
BA_ "U_V710_MY2023_Rx" SG_ 146 VehVert2_A_Actl 1;
BA_ "U_P702_MY2024_Rx" SG_ 146 VehVert2_A_Actl 1;
BA_ "MetaData" SG_ 146 VehLongAActl_D_Qf 1;
BA_ "GenSigStartValue" SG_ 146 VehLongAActl_D_Qf 1;
BA_ "U_P708_MY2023_Rx" SG_ 146 VehLongAActl_D_Qf 1;
BA_ "U_V710_MY2023_Rx" SG_ 146 VehLongAActl_D_Qf 1;
BA_ "U_P702_MY2024_Rx" SG_ 146 VehLongAActl_D_Qf 1;
BA_ "MetaData" SG_ 146 VehLatAActl_D_Qf 1;
BA_ "GenSigStartValue" SG_ 146 VehLatAActl_D_Qf 1;
BA_ "U_P708_MY2023_Rx" SG_ 146 VehLatAActl_D_Qf 1;
BA_ "U_V710_MY2023_Rx" SG_ 146 VehLatAActl_D_Qf 1;
BA_ "U_P702_MY2024_Rx" SG_ 146 VehLatAActl_D_Qf 1;
BA_ "GenSigStartValue" SG_ 146 VehLat2_A_Actl 8190;
BA_ "U_P708_MY2023_Rx" SG_ 146 VehLat2_A_Actl 1;
BA_ "U_V710_MY2023_Rx" SG_ 146 VehLat2_A_Actl 1;
BA_ "U_P702_MY2024_Rx" SG_ 146 VehLat2_A_Actl 1;
BA_ "GenSigStartValue" SG_ 146 VehLong2_A_Actl 8190;
BA_ "U_P708_MY2023_Rx" SG_ 146 VehLong2_A_Actl 1;
BA_ "U_V710_MY2023_Rx" SG_ 146 VehLong2_A_Actl 1;
BA_ "U_P702_MY2024_Rx" SG_ 146 VehLong2_A_Actl 1;
BA_ "MetaData" SG_ 146 VehLatLongVert_No_Cnt 1;
BA_ "U_P708_MY2023_Rx" SG_ 146 VehLatLongVert_No_Cnt 1;
BA_ "U_V710_MY2023_Rx" SG_ 146 VehLatLongVert_No_Cnt 1;
BA_ "U_P702_MY2024_Rx" SG_ 146 VehLatLongVert_No_Cnt 1;
BA_ "GenSigSendType" SG_ 1856 TesterPhysicalReqDDM 3;
BA_ "U_P708_MY2023_Rx" SG_ 1856 TesterPhysicalReqDDM 1;
BA_ "U_P702_MY2024_Rx" SG_ 1856 TesterPhysicalReqDDM 1;
BA_ "GenSigSendType" SG_ 1864 TesterPhysicalResDDM 3;
BA_ "U_V713N_MY2022_Tx" SG_ 1864 TesterPhysicalResDDM 1;
BA_ "U_V713AV_MY2022_Tx" SG_ 1864 TesterPhysicalResDDM 1;
BA_ "U_P708_MY2023_Tx" SG_ 1864 TesterPhysicalResDDM 1;
BA_ "U_P702_MY2024_Tx" SG_ 1864 TesterPhysicalResDDM 1;
BA_ "U_P708_MY2023_Rx" SG_ 992 MsgCntrFeatNoRq 1;
BA_ "U_V710_MY2023_Rx" SG_ 992 MsgCntrFeatNoRq 1;
BA_ "U_P702_MY2024_Rx" SG_ 992 MsgCntrFeatNoRq 1;
BA_ "U_CDX74X_MY2024_Rx" SG_ 992 MsgCntrFeatNoRq 1;
BA_ "U_P708_MY2023_Rx" SG_ 992 MsgCntrDsplyOp_D_Rq 1;
BA_ "U_V710_MY2023_Rx" SG_ 992 MsgCntrDsplyOp_D_Rq 1;
BA_ "U_P702_MY2024_Rx" SG_ 992 MsgCntrDsplyOp_D_Rq 1;
BA_ "U_CDX74X_MY2024_Rx" SG_ 992 MsgCntrDsplyOp_D_Rq 1;
BA_ "GenSigStartValue" SG_ 992 MsgCntrPersIndex_D_Rq 4;
BA_ "U_P708_MY2023_Rx" SG_ 992 MsgCntrPersIndex_D_Rq 1;
BA_ "U_V710_MY2023_Rx" SG_ 992 MsgCntrPersIndex_D_Rq 1;
BA_ "U_P702_MY2024_Rx" SG_ 992 MsgCntrPersIndex_D_Rq 1;
BA_ "U_CDX74X_MY2024_Rx" SG_ 992 MsgCntrPersIndex_D_Rq 1;
BA_ "U_P708_MY2023_Rx" SG_ 992 MsgCntrFeatConfigRq 1;
BA_ "U_V710_MY2023_Rx" SG_ 992 MsgCntrFeatConfigRq 1;
BA_ "U_P702_MY2024_Rx" SG_ 992 MsgCntrFeatConfigRq 1;
BA_ "U_CDX74X_MY2024_Rx" SG_ 992 MsgCntrFeatConfigRq 1;
BA_ "U_P708_MY2023_Rx" SG_ 994 PersCtaSplitView_D_Rq 1;
BA_ "U_V710_MY2023_Rx" SG_ 994 PersCtaSplitView_D_Rq 1;
BA_ "U_P702_MY2024_Rx" SG_ 994 PersCtaSplitView_D_Rq 1;
BA_ "U_P708_MY2023_Rx" SG_ 994 PersStore_D_Rq 1;
BA_ "U_P702_MY2024_Rx" SG_ 994 PersStore_D_Rq 1;
BA_ "WakeupSignal" SG_ 994 Pers4OptIn_B_Stats 1;
BA_ "WakeupSignal" SG_ 994 Pers3OptIn_B_Stats 1;
BA_ "WakeupSignal" SG_ 994 Pers2OptIn_B_Stats 1;
BA_ "WakeupSignal" SG_ 994 Pers1OptIn_B_Stats 1;
BA_ "GenSigStartValue" SG_ 994 CtrStkPersIndex_D_Actl 4;
BA_ "U_P708_MY2023_Rx" SG_ 994 CtrStkPersIndex_D_Actl 1;
BA_ "U_V710_MY2023_Rx" SG_ 994 CtrStkPersIndex_D_Actl 1;
BA_ "U_P702_MY2024_Rx" SG_ 994 CtrStkPersIndex_D_Actl 1;
BA_ "U_CDX74X_MY2024_Rx" SG_ 994 CtrStkPersIndex_D_Actl 1;
BA_ "U_P708_MY2023_Rx" SG_ 994 CtrStkFeatNoActl 1;
BA_ "U_V710_MY2023_Rx" SG_ 994 CtrStkFeatNoActl 1;
BA_ "U_P702_MY2024_Rx" SG_ 994 CtrStkFeatNoActl 1;
BA_ "U_CDX74X_MY2024_Rx" SG_ 994 CtrStkFeatNoActl 1;
BA_ "U_P708_MY2023_Rx" SG_ 994 CtrStkFeatConfigActl 1;
BA_ "U_V710_MY2023_Rx" SG_ 994 CtrStkFeatConfigActl 1;
BA_ "U_P702_MY2024_Rx" SG_ 994 CtrStkFeatConfigActl 1;
BA_ "U_CDX74X_MY2024_Rx" SG_ 994 CtrStkFeatConfigActl 1;
BA_ "U_P708_MY2023_Rx" SG_ 994 CtrStkDsplyOp_D_Rq 1;
BA_ "U_V710_MY2023_Rx" SG_ 994 CtrStkDsplyOp_D_Rq 1;
BA_ "U_P702_MY2024_Rx" SG_ 994 CtrStkDsplyOp_D_Rq 1;
BA_ "U_CDX74X_MY2024_Rx" SG_ 994 CtrStkDsplyOp_D_Rq 1;
BA_ "GenSigSendType" SG_ 1836 TesterPhysicalResSCCM 3;
BA_ "U_V713N_MY2022_Tx" SG_ 1836 TesterPhysicalResSCCM 1;
BA_ "U_V713AV_MY2022_Tx" SG_ 1836 TesterPhysicalResSCCM 1;
BA_ "U_P708_MY2023_Tx" SG_ 1836 TesterPhysicalResSCCM 1;
BA_ "U_V710_MY2023_Tx" SG_ 1836 TesterPhysicalResSCCM 1;
BA_ "U_P702_MY2024_Tx" SG_ 1836 TesterPhysicalResSCCM 1;
BA_ "GenSigSendType" SG_ 1828 TesterPhysicalReqSCCM 3;
BA_ "U_P708_MY2023_Rx" SG_ 1828 TesterPhysicalReqSCCM 1;
BA_ "U_P702_MY2024_Rx" SG_ 1828 TesterPhysicalReqSCCM 1;
BA_ "GenSigStartValue" SG_ 998 PersIndexSccm_D_Actl 4;
BA_ "GenSigSendType" SG_ 998 PersIndexSccm_D_Actl 3;
BA_ "U_V713N_MY2022_Tx" SG_ 998 PersIndexSccm_D_Actl 1;
BA_ "U_V713AV_MY2022_Tx" SG_ 998 PersIndexSccm_D_Actl 1;
BA_ "U_P708_MY2023_Tx" SG_ 998 PersIndexSccm_D_Actl 1;
BA_ "U_V710_MY2023_Tx" SG_ 998 PersIndexSccm_D_Actl 1;
BA_ "U_P702_MY2024_Tx" SG_ 998 PersIndexSccm_D_Actl 1;
BA_ "GenSigSendType" SG_ 998 FeatNoSccmActl 3;
BA_ "U_V713N_MY2022_Tx" SG_ 998 FeatNoSccmActl 1;
BA_ "U_V713AV_MY2022_Tx" SG_ 998 FeatNoSccmActl 1;
BA_ "U_P708_MY2023_Tx" SG_ 998 FeatNoSccmActl 1;
BA_ "U_V710_MY2023_Tx" SG_ 998 FeatNoSccmActl 1;
BA_ "U_P702_MY2024_Tx" SG_ 998 FeatNoSccmActl 1;
BA_ "GenSigSendType" SG_ 998 FeatConfigSccmActl 3;
BA_ "U_V713N_MY2022_Tx" SG_ 998 FeatConfigSccmActl 1;
BA_ "U_V713AV_MY2022_Tx" SG_ 998 FeatConfigSccmActl 1;
BA_ "U_P708_MY2023_Tx" SG_ 998 FeatConfigSccmActl 1;
BA_ "U_V710_MY2023_Tx" SG_ 998 FeatConfigSccmActl 1;
BA_ "U_P702_MY2024_Tx" SG_ 998 FeatConfigSccmActl 1;
BA_ "GenSigSendType" SG_ 1998 TesterPhysicalResSODR 3;
BA_ "U_P708_MY2023_Tx" SG_ 1998 TesterPhysicalResSODR 1;
BA_ "U_V710_MY2023_Tx" SG_ 1998 TesterPhysicalResSODR 1;
BA_ "U_P702_MY2024_Tx" SG_ 1998 TesterPhysicalResSODR 1;
BA_ "GenSigSendType" SG_ 1990 TesterPhysicalReqSODR 3;
BA_ "U_P708_MY2023_Rx" SG_ 1990 TesterPhysicalReqSODR 1;
BA_ "U_V710_MY2023_Rx" SG_ 1990 TesterPhysicalReqSODR 1;
BA_ "U_P702_MY2024_Rx" SG_ 1990 TesterPhysicalReqSODR 1;
BA_ "GenSigSendType" SG_ 1996 TesterPhysicalResSODL 3;
BA_ "U_P708_MY2023_Tx" SG_ 1996 TesterPhysicalResSODL 1;
BA_ "U_V710_MY2023_Tx" SG_ 1996 TesterPhysicalResSODL 1;
BA_ "U_P702_MY2024_Tx" SG_ 1996 TesterPhysicalResSODL 1;
BA_ "GenSigSendType" SG_ 1988 TesterPhysicalReqSODL 3;
BA_ "U_P708_MY2023_Rx" SG_ 1988 TesterPhysicalReqSODL 1;
BA_ "U_V710_MY2023_Rx" SG_ 1988 TesterPhysicalReqSODL 1;
BA_ "U_P702_MY2024_Rx" SG_ 1988 TesterPhysicalReqSODL 1;
BA_ "GenSigSendType" SG_ 828 DrvSpotLight_B_Rq 3;
BA_ "U_P708_MY2023_Rx" SG_ 828 DrvSpotLight_B_Rq 1;
BA_ "U_P702_MY2024_Rx" SG_ 828 DrvSpotLight_B_Rq 1;
BA_ "U_P708_MY2023_Tx" SG_ 828 DrvSpotLight_B_Rq 1;
BA_ "U_P702_MY2024_Tx" SG_ 828 DrvSpotLight_B_Rq 1;
BA_ "GenSigSendType" SG_ 828 SpotLghtRight_D_Stat 3;
BA_ "ECGUsedRxSignal" SG_ 828 SpotLghtRight_D_Stat 1;
BA_ "U_P708_MY2023_Rx" SG_ 828 SpotLghtRight_D_Stat 1;
BA_ "U_CDX74X_MY2024_Rx" SG_ 828 SpotLghtRight_D_Stat 1;
BA_ "U_P702_MY2024_Rx" SG_ 828 SpotLghtRight_D_Stat 1;
BA_ "U_P708_MY2023_Tx" SG_ 828 SpotLghtRight_D_Stat 1;
BA_ "U_P702_MY2024_Tx" SG_ 828 SpotLghtRight_D_Stat 1;
BA_ "WakeupSignal" SG_ 828 RearPassWindowPos 1;
BA_ "GenSigSendType" SG_ 828 RearPassWindowPos 3;
BA_ "ECGUsedRxSignal" SG_ 828 RearPassWindowPos 1;
BA_ "U_P708_MY2023_Rx" SG_ 828 RearPassWindowPos 1;
BA_ "U_CDX74X_MY2024_Rx" SG_ 828 RearPassWindowPos 1;
BA_ "U_P702_MY2024_Rx" SG_ 828 RearPassWindowPos 1;
BA_ "U_V713N_MY2022_Tx" SG_ 828 RearPassWindowPos 1;
BA_ "U_V713AV_MY2022_Tx" SG_ 828 RearPassWindowPos 1;
BA_ "U_P708_MY2023_Tx" SG_ 828 RearPassWindowPos 1;
BA_ "U_V710_MY2023_Tx" SG_ 828 RearPassWindowPos 1;
BA_ "U_P702_MY2024_Tx" SG_ 828 RearPassWindowPos 1;
BA_ "WakeupSignal" SG_ 828 PassWindowPosition 1;
BA_ "GenSigSendType" SG_ 828 PassWindowPosition 3;
BA_ "ECGUsedRxSignal" SG_ 828 PassWindowPosition 1;
BA_ "U_P708_MY2023_Rx" SG_ 828 PassWindowPosition 1;
BA_ "U_CDX74X_MY2024_Rx" SG_ 828 PassWindowPosition 1;
BA_ "U_P702_MY2024_Rx" SG_ 828 PassWindowPosition 1;
BA_ "U_V713N_MY2022_Tx" SG_ 828 PassWindowPosition 1;
BA_ "U_V713AV_MY2022_Tx" SG_ 828 PassWindowPosition 1;
BA_ "U_P708_MY2023_Tx" SG_ 828 PassWindowPosition 1;
BA_ "U_V710_MY2023_Tx" SG_ 828 PassWindowPosition 1;
BA_ "U_P702_MY2024_Tx" SG_ 828 PassWindowPosition 1;
BA_ "GenSigSendType" SG_ 828 SpotLghtLeft_D_Stat 3;
BA_ "ECGUsedRxSignal" SG_ 828 SpotLghtLeft_D_Stat 1;
BA_ "U_P708_MY2023_Rx" SG_ 828 SpotLghtLeft_D_Stat 1;
BA_ "U_CDX74X_MY2024_Rx" SG_ 828 SpotLghtLeft_D_Stat 1;
BA_ "U_P702_MY2024_Rx" SG_ 828 SpotLghtLeft_D_Stat 1;
BA_ "U_P708_MY2023_Tx" SG_ 828 SpotLghtLeft_D_Stat 1;
BA_ "U_P702_MY2024_Tx" SG_ 828 SpotLghtLeft_D_Stat 1;
BA_ "MetaData" SG_ 943 VehVActlAdas_D_Qf 1;
BA_ "GenSigStartValue" SG_ 943 VehVActlAdas_D_Qf 1;
BA_ "U_P708_MY2023_Tx" SG_ 943 VehVActlAdas_D_Qf 1;
BA_ "U_V710_MY2023_Tx" SG_ 943 VehVActlAdas_D_Qf 1;
BA_ "U_P702_MY2024_Tx" SG_ 943 VehVActlAdas_D_Qf 1;
BA_ "U_P708_MY2023_Tx" SG_ 943 Veh_V_RqLsc 1;
BA_ "U_V710_MY2023_Tx" SG_ 943 Veh_V_RqLsc 1;
BA_ "U_P702_MY2024_Tx" SG_ 943 Veh_V_RqLsc 1;
BA_ "U_P708_MY2023_Tx" SG_ 943 Veh_V_ActlAdas 1;
BA_ "U_V710_MY2023_Tx" SG_ 943 Veh_V_ActlAdas 1;
BA_ "U_P702_MY2024_Tx" SG_ 943 Veh_V_ActlAdas 1;
BA_ "GenSigStartValue" SG_ 943 AdasLcDistToObj_L_Actl 4094;
BA_ "U_P708_MY2023_Tx" SG_ 943 AdasLcDistToObj_L_Actl 1;
BA_ "U_V710_MY2023_Tx" SG_ 943 AdasLcDistToObj_L_Actl 1;
BA_ "U_P702_MY2024_Tx" SG_ 943 AdasLcDistToObj_L_Actl 1;
BA_ "U_P708_MY2023_Rx" SG_ 558 EhData1_No_Actl 1;
BA_ "U_V710_MY2023_Rx" SG_ 558 EhData1_No_Actl 1;
BA_ "U_P702_MY2024_Rx" SG_ 558 EhData1_No_Actl 1;
BA_ "U_CDX74X_MY2024_Rx" SG_ 558 EhData1_No_Actl 1;
BA_ "U_P708_MY2023_Rx" SG_ 549 Veh_V2_Dsply 1;
BA_ "U_V710_MY2023_Rx" SG_ 549 Veh_V2_Dsply 1;
BA_ "U_P702_MY2024_Rx" SG_ 549 Veh_V2_Dsply 1;
BA_ "WakeupSignal" SG_ 549 Power_Up_Chime_Modules 1;
BA_ "GenSigSendType" SG_ 2015 TesterFunctionalReq 3;
BA_ "ECGUsedRxSignal" SG_ 2015 TesterFunctionalReq 1;
BA_ "U_P708_MY2023_Rx" SG_ 2015 TesterFunctionalReq 1;
BA_ "U_CDX74X_MY2024_Rx" SG_ 2015 TesterFunctionalReq 1;
BA_ "U_V710_MY2023_Rx" SG_ 2015 TesterFunctionalReq 1;
BA_ "U_P702_MY2024_Rx" SG_ 2015 TesterFunctionalReq 1;
BA_ "U_V713N_MY2022_Rx" SG_ 2015 TesterFunctionalReq 1;
BA_ "U_P708_MY2023_Rx" SG_ 132 GlblClkYr_No_Actl 1;
BA_ "U_V710_MY2023_Rx" SG_ 132 GlblClkYr_No_Actl 1;
BA_ "U_P702_MY2024_Rx" SG_ 132 GlblClkYr_No_Actl 1;
BA_ "U_P708_MY2023_Rx" SG_ 132 GlblClkScnd_No_Actl 1;
BA_ "U_V710_MY2023_Rx" SG_ 132 GlblClkScnd_No_Actl 1;
BA_ "U_P702_MY2024_Rx" SG_ 132 GlblClkScnd_No_Actl 1;
BA_ "U_P708_MY2023_Rx" SG_ 132 GlblClkMnte_No_Actl 1;
BA_ "U_V710_MY2023_Rx" SG_ 132 GlblClkMnte_No_Actl 1;
BA_ "U_P702_MY2024_Rx" SG_ 132 GlblClkMnte_No_Actl 1;
BA_ "U_P708_MY2023_Rx" SG_ 132 GlblClkHr_No_Actl 1;
BA_ "U_V710_MY2023_Rx" SG_ 132 GlblClkHr_No_Actl 1;
BA_ "U_P702_MY2024_Rx" SG_ 132 GlblClkHr_No_Actl 1;
BA_ "U_P708_MY2023_Rx" SG_ 132 GlblClkDay_No_Actl 1;
BA_ "U_V710_MY2023_Rx" SG_ 132 GlblClkDay_No_Actl 1;
BA_ "U_P702_MY2024_Rx" SG_ 132 GlblClkDay_No_Actl 1;
BA_ "WakeupSignal" SG_ 947 DimmingLvlEvnt_No_Actl 1;
BA_ "WakeupSignal" SG_ 947 TurnLghtRight_D_Rq 1;
BA_ "U_P708_MY2023_Rx" SG_ 947 TurnLghtRight_D_Rq 1;
BA_ "U_V710_MY2023_Rx" SG_ 947 TurnLghtRight_D_Rq 1;
BA_ "U_P702_MY2024_Rx" SG_ 947 TurnLghtRight_D_Rq 1;
BA_ "U_CDX74X_MY2024_Rx" SG_ 947 TurnLghtRight_D_Rq 1;
BA_ "U_P708_MY2023_Rx" SG_ 947 FogLghtRearOn_B_Stat 1;
BA_ "U_V710_MY2023_Rx" SG_ 947 FogLghtRearOn_B_Stat 1;
BA_ "U_P702_MY2024_Rx" SG_ 947 FogLghtRearOn_B_Stat 1;
BA_ "U_CDX74X_MY2024_Rx" SG_ 947 FogLghtRearOn_B_Stat 1;
BA_ "WakeupSignal" SG_ 947 Backlit_LED_Status 1;
BA_ "U_P708_MY2023_Rx" SG_ 947 Backlit_LED_Status 1;
BA_ "U_P702_MY2024_Rx" SG_ 947 Backlit_LED_Status 1;
BA_ "WakeupSignal" SG_ 947 TurnLghtLeft_D_Rq 1;
BA_ "U_P708_MY2023_Rx" SG_ 947 TurnLghtLeft_D_Rq 1;
BA_ "U_V710_MY2023_Rx" SG_ 947 TurnLghtLeft_D_Rq 1;
BA_ "U_P702_MY2024_Rx" SG_ 947 TurnLghtLeft_D_Rq 1;
BA_ "U_CDX74X_MY2024_Rx" SG_ 947 TurnLghtLeft_D_Rq 1;
BA_ "U_P708_MY2023_Rx" SG_ 947 FogLghtFrontOn_B_Stat 1;
BA_ "U_V710_MY2023_Rx" SG_ 947 FogLghtFrontOn_B_Stat 1;
BA_ "U_P702_MY2024_Rx" SG_ 947 FogLghtFrontOn_B_Stat 1;
BA_ "U_CDX74X_MY2024_Rx" SG_ 947 FogLghtFrontOn_B_Stat 1;
BA_ "GenSigStartValue" SG_ 947 IgnKeyType_D_Actl 14;
BA_ "U_P708_MY2023_Rx" SG_ 947 IgnKeyType_D_Actl 1;
BA_ "U_V710_MY2023_Rx" SG_ 947 IgnKeyType_D_Actl 1;
BA_ "U_P702_MY2024_Rx" SG_ 947 IgnKeyType_D_Actl 1;
BA_ "WakeupSignal" SG_ 947 Parklamp_Status 1;
BA_ "GenSigStartValue" SG_ 947 Parklamp_Status 1;
BA_ "U_P708_MY2023_Rx" SG_ 947 Parklamp_Status 1;
BA_ "U_V710_MY2023_Rx" SG_ 947 Parklamp_Status 1;
BA_ "U_P702_MY2024_Rx" SG_ 947 Parklamp_Status 1;
BA_ "WakeupSignal" SG_ 947 Litval 1;
BA_ "U_P708_MY2023_Rx" SG_ 947 Litval 1;
BA_ "U_V710_MY2023_Rx" SG_ 947 Litval 1;
BA_ "U_P702_MY2024_Rx" SG_ 947 Litval 1;
BA_ "U_CDX74X_MY2024_Rx" SG_ 947 Litval 1;
BA_ "WakeupSignal" SG_ 947 Key_In_Ignition_Stat 1;
BA_ "WakeupSignal" SG_ 947 Ignition_Status 1;
BA_ "U_P708_MY2023_Rx" SG_ 947 Ignition_Status 1;
BA_ "U_V710_MY2023_Rx" SG_ 947 Ignition_Status 1;
BA_ "U_P702_MY2024_Rx" SG_ 947 Ignition_Status 1;
BA_ "U_V713N_MY2022_Rx" SG_ 947 Ignition_Status 1;
BA_ "U_CDX74X_MY2024_Rx" SG_ 947 Ignition_Status 1;
BA_ "WakeupSignal" SG_ 947 Dimming_Lvl 1;
BA_ "GenSigStartValue" SG_ 947 Dimming_Lvl 12;
BA_ "U_P708_MY2023_Rx" SG_ 947 Dimming_Lvl 1;
BA_ "U_V710_MY2023_Rx" SG_ 947 Dimming_Lvl 1;
BA_ "U_P702_MY2024_Rx" SG_ 947 Dimming_Lvl 1;
BA_ "WakeupSignal" SG_ 947 Day_Night_Status 1;
BA_ "U_P708_MY2023_Rx" SG_ 947 Day_Night_Status 1;
BA_ "U_V710_MY2023_Rx" SG_ 947 Day_Night_Status 1;
BA_ "U_P702_MY2024_Rx" SG_ 947 Day_Night_Status 1;
BA_ "WakeupSignal" SG_ 947 Remote_Start_Status 1;
BA_ "U_P708_MY2023_Rx" SG_ 947 Remote_Start_Status 1;
BA_ "U_V710_MY2023_Rx" SG_ 947 Remote_Start_Status 1;
BA_ "U_P702_MY2024_Rx" SG_ 947 Remote_Start_Status 1;
BA_ "WakeupSignal" SG_ 947 DrStatTgate_B_Actl 1;
BA_ "U_P708_MY2023_Rx" SG_ 947 DrStatTgate_B_Actl 1;
BA_ "U_V710_MY2023_Rx" SG_ 947 DrStatTgate_B_Actl 1;
BA_ "U_P702_MY2024_Rx" SG_ 947 DrStatTgate_B_Actl 1;
BA_ "WakeupSignal" SG_ 947 DrStatRr_B_Actl 1;
BA_ "U_P708_MY2023_Rx" SG_ 947 DrStatRr_B_Actl 1;
BA_ "U_V710_MY2023_Rx" SG_ 947 DrStatRr_B_Actl 1;
BA_ "U_P702_MY2024_Rx" SG_ 947 DrStatRr_B_Actl 1;
BA_ "WakeupSignal" SG_ 947 DrStatRl_B_Actl 1;
BA_ "U_P708_MY2023_Rx" SG_ 947 DrStatRl_B_Actl 1;
BA_ "U_V710_MY2023_Rx" SG_ 947 DrStatRl_B_Actl 1;
BA_ "U_P702_MY2024_Rx" SG_ 947 DrStatRl_B_Actl 1;
BA_ "WakeupSignal" SG_ 947 DrStatPsngr_B_Actl 1;
BA_ "U_P708_MY2023_Rx" SG_ 947 DrStatPsngr_B_Actl 1;
BA_ "U_V710_MY2023_Rx" SG_ 947 DrStatPsngr_B_Actl 1;
BA_ "U_P702_MY2024_Rx" SG_ 947 DrStatPsngr_B_Actl 1;
BA_ "WakeupSignal" SG_ 947 DrStatInnrTgate_B_Actl 1;
BA_ "U_P708_MY2023_Rx" SG_ 947 DrStatInnrTgate_B_Actl 1;
BA_ "U_V710_MY2023_Rx" SG_ 947 DrStatInnrTgate_B_Actl 1;
BA_ "U_P702_MY2024_Rx" SG_ 947 DrStatInnrTgate_B_Actl 1;
BA_ "WakeupSignal" SG_ 947 DrStatHood_B_Actl 1;
BA_ "WakeupSignal" SG_ 947 DrStatDrv_B_Actl 1;
BA_ "U_P708_MY2023_Rx" SG_ 947 DrStatDrv_B_Actl 1;
BA_ "U_V710_MY2023_Rx" SG_ 947 DrStatDrv_B_Actl 1;
BA_ "U_P702_MY2024_Rx" SG_ 947 DrStatDrv_B_Actl 1;
BA_ "WakeupSignal" SG_ 947 PrkBrkActv_B_Actl 1;
BA_ "U_P708_MY2023_Rx" SG_ 947 PrkBrkActv_B_Actl 1;
BA_ "U_V710_MY2023_Rx" SG_ 947 PrkBrkActv_B_Actl 1;
BA_ "U_P702_MY2024_Rx" SG_ 947 PrkBrkActv_B_Actl 1;
BA_ "U_P708_MY2023_Rx" SG_ 947 LifeCycMde_D_Actl 1;
BA_ "U_V710_MY2023_Rx" SG_ 947 LifeCycMde_D_Actl 1;
BA_ "U_P702_MY2024_Rx" SG_ 947 LifeCycMde_D_Actl 1;
BA_ "U_V713N_MY2022_Rx" SG_ 947 LifeCycMde_D_Actl 1;
BA_ "U_CDX74X_MY2024_Rx" SG_ 947 LifeCycMde_D_Actl 1;
BA_ "WakeupSignal" SG_ 947 Delay_Accy 1;
BA_ "U_P708_MY2023_Rx" SG_ 947 Delay_Accy 1;
BA_ "U_P702_MY2024_Rx" SG_ 947 Delay_Accy 1;
BA_ "WakeupSignal" SG_ 947 CrashEvnt_D_Stat 1;
BA_ "GenSigStartValue" SG_ 947 CrashEvnt_D_Stat 3;
BA_ "WakeupSignal" SG_ 1068 PwSysULoFalt_D_Stat 1;
BA_ "U_P708_MY2023_Rx" SG_ 1068 PwSysULoFalt_D_Stat 1;
BA_ "U_P708_MY2023_Rx" SG_ 1068 Shed_T_Eng_Off_B 1;
BA_ "U_P702_MY2024_Rx" SG_ 1068 Shed_T_Eng_Off_B 1;
BA_ "WakeupSignal" SG_ 1068 Shed_Feature_Group_ID 1;
BA_ "U_P708_MY2023_Rx" SG_ 1068 Shed_Feature_Group_ID 1;
BA_ "U_V710_MY2023_Rx" SG_ 1068 Shed_Feature_Group_ID 1;
BA_ "U_P702_MY2024_Rx" SG_ 1068 Shed_Feature_Group_ID 1;
BA_ "U_P708_MY2023_Rx" SG_ 1068 Shed_Drain_Eng_Off_B 1;
BA_ "U_P702_MY2024_Rx" SG_ 1068 Shed_Drain_Eng_Off_B 1;
BA_ "WakeupSignal" SG_ 1068 Shed_Level_Req 1;
BA_ "U_P708_MY2023_Rx" SG_ 1068 Shed_Level_Req 1;
BA_ "U_V710_MY2023_Rx" SG_ 1068 Shed_Level_Req 1;
BA_ "U_P702_MY2024_Rx" SG_ 1068 Shed_Level_Req 1;
BA_ "GenSigStartValue" SG_ 1438 GWM_GWOnBoardTester 255;
BA_ "U_V713N_MY2022_Rx" SG_ 1438 GWM_GWOnBoardTester 1;
BA_ "U_P708_MY2023_Rx" SG_ 1438 GWM_GWOnBoardTester 1;
BA_ "U_V710_MY2023_Rx" SG_ 1438 GWM_GWOnBoardTester 1;
BA_ "U_P702_MY2024_Rx" SG_ 1438 GWM_GWOnBoardTester 1;
BA_ "ECGUsedTxSignal" SG_ 1438 GWM_GWOnBoardTester 1;
BA_ "U_P708_MY2023_Tx" SG_ 1438 GWM_GWOnBoardTester 1;
BA_ "U_CDX74X_MY2024_Tx" SG_ 1438 GWM_GWOnBoardTester 1;
BA_ "U_V710_MY2023_Tx" SG_ 1438 GWM_GWOnBoardTester 1;
BA_ "U_P702_MY2024_Tx" SG_ 1438 GWM_GWOnBoardTester 1;
BA_ "GenSigStartValue" SG_ 1438 GWM_GWNMProxy 255;
BA_ "U_V713N_MY2022_Rx" SG_ 1438 GWM_GWNMProxy 1;
BA_ "U_P708_MY2023_Rx" SG_ 1438 GWM_GWNMProxy 1;
BA_ "U_V710_MY2023_Rx" SG_ 1438 GWM_GWNMProxy 1;
BA_ "U_P702_MY2024_Rx" SG_ 1438 GWM_GWNMProxy 1;
BA_ "ECGUsedTxSignal" SG_ 1438 GWM_GWNMProxy 1;
BA_ "U_P708_MY2023_Tx" SG_ 1438 GWM_GWNMProxy 1;
BA_ "U_CDX74X_MY2024_Tx" SG_ 1438 GWM_GWNMProxy 1;
BA_ "U_V710_MY2023_Tx" SG_ 1438 GWM_GWNMProxy 1;
BA_ "U_P702_MY2024_Tx" SG_ 1438 GWM_GWNMProxy 1;
BA_ "GenSigStartValue" SG_ 1438 GWM_AutoSarNMReserved4 255;
BA_ "U_V713N_MY2022_Rx" SG_ 1438 GWM_AutoSarNMReserved4 1;
BA_ "U_P708_MY2023_Rx" SG_ 1438 GWM_AutoSarNMReserved4 1;
BA_ "U_V710_MY2023_Rx" SG_ 1438 GWM_AutoSarNMReserved4 1;
BA_ "U_P702_MY2024_Rx" SG_ 1438 GWM_AutoSarNMReserved4 1;
BA_ "ECGUsedTxSignal" SG_ 1438 GWM_AutoSarNMReserved4 1;
BA_ "U_P708_MY2023_Tx" SG_ 1438 GWM_AutoSarNMReserved4 1;
BA_ "U_CDX74X_MY2024_Tx" SG_ 1438 GWM_AutoSarNMReserved4 1;
BA_ "U_V710_MY2023_Tx" SG_ 1438 GWM_AutoSarNMReserved4 1;
BA_ "U_P702_MY2024_Tx" SG_ 1438 GWM_AutoSarNMReserved4 1;
BA_ "GenSigStartValue" SG_ 1438 GWM_AutoSarNMReserved3 255;
BA_ "U_V713N_MY2022_Rx" SG_ 1438 GWM_AutoSarNMReserved3 1;
BA_ "U_P708_MY2023_Rx" SG_ 1438 GWM_AutoSarNMReserved3 1;
BA_ "U_V710_MY2023_Rx" SG_ 1438 GWM_AutoSarNMReserved3 1;
BA_ "U_P702_MY2024_Rx" SG_ 1438 GWM_AutoSarNMReserved3 1;
BA_ "ECGUsedTxSignal" SG_ 1438 GWM_AutoSarNMReserved3 1;
BA_ "U_P708_MY2023_Tx" SG_ 1438 GWM_AutoSarNMReserved3 1;
BA_ "U_CDX74X_MY2024_Tx" SG_ 1438 GWM_AutoSarNMReserved3 1;
BA_ "U_V710_MY2023_Tx" SG_ 1438 GWM_AutoSarNMReserved3 1;
BA_ "U_P702_MY2024_Tx" SG_ 1438 GWM_AutoSarNMReserved3 1;
BA_ "GenSigStartValue" SG_ 1438 GWM_AutoSarNMReserved2 255;
BA_ "U_V713N_MY2022_Rx" SG_ 1438 GWM_AutoSarNMReserved2 1;
BA_ "U_P708_MY2023_Rx" SG_ 1438 GWM_AutoSarNMReserved2 1;
BA_ "U_V710_MY2023_Rx" SG_ 1438 GWM_AutoSarNMReserved2 1;
BA_ "U_P702_MY2024_Rx" SG_ 1438 GWM_AutoSarNMReserved2 1;
BA_ "ECGUsedTxSignal" SG_ 1438 GWM_AutoSarNMReserved2 1;
BA_ "U_P708_MY2023_Tx" SG_ 1438 GWM_AutoSarNMReserved2 1;
BA_ "U_CDX74X_MY2024_Tx" SG_ 1438 GWM_AutoSarNMReserved2 1;
BA_ "U_V710_MY2023_Tx" SG_ 1438 GWM_AutoSarNMReserved2 1;
BA_ "U_P702_MY2024_Tx" SG_ 1438 GWM_AutoSarNMReserved2 1;
BA_ "GenSigStartValue" SG_ 1438 GWM_AutoSarNMReserved1 255;
BA_ "U_V713N_MY2022_Rx" SG_ 1438 GWM_AutoSarNMReserved1 1;
BA_ "U_P708_MY2023_Rx" SG_ 1438 GWM_AutoSarNMReserved1 1;
BA_ "U_V710_MY2023_Rx" SG_ 1438 GWM_AutoSarNMReserved1 1;
BA_ "U_P702_MY2024_Rx" SG_ 1438 GWM_AutoSarNMReserved1 1;
BA_ "ECGUsedTxSignal" SG_ 1438 GWM_AutoSarNMReserved1 1;
BA_ "U_P708_MY2023_Tx" SG_ 1438 GWM_AutoSarNMReserved1 1;
BA_ "U_CDX74X_MY2024_Tx" SG_ 1438 GWM_AutoSarNMReserved1 1;
BA_ "U_V710_MY2023_Tx" SG_ 1438 GWM_AutoSarNMReserved1 1;
BA_ "U_P702_MY2024_Tx" SG_ 1438 GWM_AutoSarNMReserved1 1;
BA_ "GenSigStartValue" SG_ 1438 GWM_AutoSarNMNodeId 158;
BA_ "U_V713N_MY2022_Rx" SG_ 1438 GWM_AutoSarNMNodeId 1;
BA_ "U_P708_MY2023_Rx" SG_ 1438 GWM_AutoSarNMNodeId 1;
BA_ "U_V710_MY2023_Rx" SG_ 1438 GWM_AutoSarNMNodeId 1;
BA_ "U_P702_MY2024_Rx" SG_ 1438 GWM_AutoSarNMNodeId 1;
BA_ "ECGUsedTxSignal" SG_ 1438 GWM_AutoSarNMNodeId 1;
BA_ "U_P708_MY2023_Tx" SG_ 1438 GWM_AutoSarNMNodeId 1;
BA_ "U_CDX74X_MY2024_Tx" SG_ 1438 GWM_AutoSarNMNodeId 1;
BA_ "U_V710_MY2023_Tx" SG_ 1438 GWM_AutoSarNMNodeId 1;
BA_ "U_P702_MY2024_Tx" SG_ 1438 GWM_AutoSarNMNodeId 1;
BA_ "U_V713N_MY2022_Rx" SG_ 1438 GWM_AutoSarNMControl 1;
BA_ "U_P708_MY2023_Rx" SG_ 1438 GWM_AutoSarNMControl 1;
BA_ "U_V710_MY2023_Rx" SG_ 1438 GWM_AutoSarNMControl 1;
BA_ "U_P702_MY2024_Rx" SG_ 1438 GWM_AutoSarNMControl 1;
BA_ "ECGUsedTxSignal" SG_ 1438 GWM_AutoSarNMControl 1;
BA_ "U_P708_MY2023_Tx" SG_ 1438 GWM_AutoSarNMControl 1;
BA_ "U_CDX74X_MY2024_Tx" SG_ 1438 GWM_AutoSarNMControl 1;
BA_ "U_V710_MY2023_Tx" SG_ 1438 GWM_AutoSarNMControl 1;
BA_ "U_P702_MY2024_Tx" SG_ 1438 GWM_AutoSarNMControl 1;
BA_ "WakeupSignal" SG_ 826 Memory_3_Sw_Stat 1;
BA_ "GenSigSendType" SG_ 826 Memory_3_Sw_Stat 3;
BA_ "U_P708_MY2023_Tx" SG_ 826 Memory_3_Sw_Stat 1;
BA_ "U_P702_MY2024_Tx" SG_ 826 Memory_3_Sw_Stat 1;
BA_ "WakeupSignal" SG_ 826 Memory_2_Sw_Stat 1;
BA_ "GenSigSendType" SG_ 826 Memory_2_Sw_Stat 3;
BA_ "U_P708_MY2023_Tx" SG_ 826 Memory_2_Sw_Stat 1;
BA_ "U_P702_MY2024_Tx" SG_ 826 Memory_2_Sw_Stat 1;
BA_ "WakeupSignal" SG_ 826 Memory_1_Sw_Stat 1;
BA_ "GenSigSendType" SG_ 826 Memory_1_Sw_Stat 3;
BA_ "U_P708_MY2023_Tx" SG_ 826 Memory_1_Sw_Stat 1;
BA_ "U_P702_MY2024_Tx" SG_ 826 Memory_1_Sw_Stat 1;
BA_ "WakeupSignal" SG_ 826 Mirror_Manual_Override 1;
BA_ "GenSigSendType" SG_ 826 Mirror_Manual_Override 3;
BA_ "U_P708_MY2023_Tx" SG_ 826 Mirror_Manual_Override 1;
BA_ "U_P702_MY2024_Tx" SG_ 826 Mirror_Manual_Override 1;
BA_ "GenSigStartValue" SG_ 827 LghtAmbIntns_D2_Sns 3;
BA_ "GenSigSendType" SG_ 827 LghtAmbIntns_D2_Sns 3;
BA_ "U_V713AV_MY2022_Tx" SG_ 827 LghtAmbIntns_D2_Sns 1;
BA_ "U_P708_MY2023_Tx" SG_ 827 LghtAmbIntns_D2_Sns 1;
BA_ "U_V710_MY2023_Tx" SG_ 827 LghtAmbIntns_D2_Sns 1;
BA_ "U_P702_MY2024_Tx" SG_ 827 LghtAmbIntns_D2_Sns 1;
BA_ "WakeupSignal" SG_ 827 SteClmnSwtchTlt_D_Stat 1;
BA_ "GenSigSendType" SG_ 827 SteClmnSwtchTlt_D_Stat 3;
BA_ "U_V713N_MY2022_Tx" SG_ 827 SteClmnSwtchTlt_D_Stat 1;
BA_ "U_V713AV_MY2022_Tx" SG_ 827 SteClmnSwtchTlt_D_Stat 1;
BA_ "U_P708_MY2023_Tx" SG_ 827 SteClmnSwtchTlt_D_Stat 1;
BA_ "U_P702_MY2024_Tx" SG_ 827 SteClmnSwtchTlt_D_Stat 1;
BA_ "WakeupSignal" SG_ 827 SteClmnSwtchTel_D_Stat 1;
BA_ "GenSigSendType" SG_ 827 SteClmnSwtchTel_D_Stat 3;
BA_ "U_V713N_MY2022_Tx" SG_ 827 SteClmnSwtchTel_D_Stat 1;
BA_ "U_V713AV_MY2022_Tx" SG_ 827 SteClmnSwtchTel_D_Stat 1;
BA_ "U_P708_MY2023_Tx" SG_ 827 SteClmnSwtchTel_D_Stat 1;
BA_ "U_P702_MY2024_Tx" SG_ 827 SteClmnSwtchTel_D_Stat 1;
BA_ "GenSigSendType" SG_ 827 LghtAmbIntns_D_Sns 3;
BA_ "U_V713N_MY2022_Tx" SG_ 827 LghtAmbIntns_D_Sns 1;
BA_ "U_V713AV_MY2022_Tx" SG_ 827 LghtAmbIntns_D_Sns 1;
BA_ "U_P708_MY2023_Tx" SG_ 827 LghtAmbIntns_D_Sns 1;
BA_ "U_V710_MY2023_Tx" SG_ 827 LghtAmbIntns_D_Sns 1;
BA_ "U_P702_MY2024_Tx" SG_ 827 LghtAmbIntns_D_Sns 1;
BA_ "U_V713N_MY2022_Tx" SG_ 827 LghtAmb_Intns_Sns 1;
BA_ "U_V713AV_MY2022_Tx" SG_ 827 LghtAmb_Intns_Sns 1;
BA_ "U_P708_MY2023_Tx" SG_ 827 LghtAmb_Intns_Sns 1;
BA_ "U_V710_MY2023_Tx" SG_ 827 LghtAmb_Intns_Sns 1;
BA_ "U_P702_MY2024_Tx" SG_ 827 LghtAmb_Intns_Sns 1;
BA_REL_ "SC_Verification" BU_SG_REL_ IPMA_ADAS SG_ 357 BPedDrvAppl_D_Qf 1;
BA_REL_ "SC_Verification" BU_SG_REL_ IPMA_ADAS SG_ 357 PrplTqMnSat_B_Actl 1;
BA_REL_ "SC_Verification" BU_SG_REL_ IPMA_ADAS SG_ 357 BpedDrvAppl_D_Actl 1;
BA_REL_ "SC_Verification" BU_SG_REL_ IPMA_ADAS SG_ 357 CmbbEngTqMn_B_Actl 1;
BA_REL_ "SC_Verification" BU_SG_REL_ IPMA_ADAS SG_ 357 AccEngStat_D_Actl 1;
BA_REL_ "SC_Verification" BU_SG_REL_ IPMA_ADAS SG_ 357 CcStat_D_Actl 1;
BA_REL_ "SC_Verification" BU_SG_REL_ IPMA_ADAS SG_ 357 CcOvrrdActv_B_Actl 1;
BA_REL_ "SC_Verification" BU_SG_REL_ IPMA_ADAS SG_ 357 AccStopMde_D_Rq 1;
BA_REL_ "SC_Verification" BU_SG_REL_ PSCM SG_ 1045 VehVActlBrk_No_Cs 1;
BA_REL_ "SC_Verification" BU_SG_REL_ IPMA_ADAS SG_ 1045 VehVActlBrk_No_Cs 1;
BA_REL_ "SC_Verification" BU_SG_REL_ PSCM SG_ 1045 Veh_V_ActlBrk 1;
BA_REL_ "SC_Verification" BU_SG_REL_ IPMA_ADAS SG_ 1045 Veh_V_ActlBrk 1;
BA_REL_ "SC_Verification" BU_SG_REL_ PSCM SG_ 1045 VehVActlBrk_D_Qf 1;
BA_REL_ "SC_Verification" BU_SG_REL_ IPMA_ADAS SG_ 1045 VehVActlBrk_D_Qf 1;
BA_REL_ "SC_Verification" BU_SG_REL_ PSCM SG_ 1044 StePinOffst_An_Est 1;
BA_REL_ "SC_Verification" BU_SG_REL_ PSCM SG_ 1044 StePinOffst_D_Stat 1;
BA_REL_ "SC_Verification" BU_SG_REL_ IPMA_ADAS SG_ 1046 DrvSlipCtlMde_D_Ind 1;
BA_REL_ "SC_Verification" BU_SG_REL_ IPMA_ADAS SG_ 1046 DrvSlipCtlLamp_D_Rq 1;
BA_REL_ "SC_Verification" BU_SG_REL_ IPMA_ADAS SG_ 132 GlblClkScnd_No_Actl 1;
BA_REL_ "SC_Verification" BU_SG_REL_ IPMA_ADAS SG_ 132 GlblClkMnte_No_Actl 1;
BA_REL_ "SC_Verification" BU_SG_REL_ IPMA_ADAS SG_ 132 GlblClkHr_No_Actl 1;
BA_REL_ "SC_Verification" BU_SG_REL_ IPMA_ADAS SG_ 132 GlblClkDay_No_Actl 1;
BA_REL_ "SC_Verification" BU_SG_REL_ HCM SG_ 947 TurnLghtRight_D_Rq 1;
BA_REL_ "SC_Verification" BU_SG_REL_ HCM SG_ 947 TurnLghtLeft_D_Rq 1;
BA_REL_ "SC_Verification" BU_SG_REL_ IPMA_ADAS SG_ 947 IgnKeyType_D_Actl 1;
BA_REL_ "SC_Verification" BU_SG_REL_ IPMA_ADAS SG_ 947 Ignition_Status 1;
BA_REL_ "SC_Verification" BU_SG_REL_ IPMA_ADAS SG_ 947 DrStatDrv_B_Actl 1;
BA_REL_ "SC_Verification" BU_SG_REL_ IPMA_ADAS SG_ 947 LifeCycMde_D_Actl 1;
VAL_ 1122 GPS_Longitude_Minutes 63 "Fault" 62 "Unknown" ;
VAL_ 1122 GPS_Longitude_Min_dec 16383 "Invalid" 16382 "Unknown" ;
VAL_ 1122 GPS_Longitude_Degrees 511 "Fault" 510 "Unknown" ;
VAL_ 1122 GPS_Latitude_Minutes 63 "Fault" 62 "Unknown" ;
VAL_ 1122 GPS_Latitude_Min_dec 16383 "Invalid" 16382 "Unknown" ;
VAL_ 1122 GPS_Latitude_Degrees 255 "Invalid" 254 "Unknown" ;
VAL_ 1122 GpsHsphLongEast_D_Actl 0 "Invalid" 1 "Eastern" 2 "Western" 3 "Fault" ;
VAL_ 1122 GpsHsphLattSth_D_Actl 3 "Fault" 2 "Northern" 1 "Southern" 0 "Invalid" ;
VAL_ 1054 RbaBrk_D_Stat 3 "Denied" 2 "Active" 1 "Open" 0 "Closed" ;
VAL_ 1054 SelDrvMdeChassis2_D_Rq 31 "Faulty" 30 "NotUsed17" 29 "NotUsed16" 28 "NotUsed15" 27 "NotUsed14" 26 "NotUsed13" 25 "NotUsed12" 24 "NotUsed11" 23 "NotUsed10" 22 "NotUsed9" 21 "NotUsed8" 20 "NotUsed7" 19 "NotUsed6" 18 "NotUsed5" 17 "NotUsed4" 16 "OnePedalDrive" 15 "DragMode" 14 "RoughRoadMode" 13 "TrackMode" 12 "HighSpeedDesertMode" 11 "TowHaulMode" 10 "RockCrawlMode" 9 "SandMode" 8 "MudAndRutsMode" 7 "LowMuMode" 6 "ComfortAdaptiveMode" 5 "ComfortMode" 4 "SportAdaptiveMode" 3 "SportMode" 2 "EconomyMode" 1 "NormalAdaptiveMode" 0 "NormalMode" ;
VAL_ 1054 TrailCtl_D_Stat 7 "Faulty" 6 "DescentOnly" 5 "EnabledDeny" 4 "StandbyOverThreshold" 3 "StandbyOverride" 2 "Active" 1 "EnabledDescent" 0 "Off" ;
VAL_ 1054 TrailCtlMsgTxt_D_Rq 15 "Message15" 14 "Message14" 13 "Message13" 12 "Message12" 11 "Message11" 10 "Message10" 9 "Message9" 8 "Message8" 7 "Message7" 6 "Message6" 5 "Message5" 4 "Message4" 3 "Message3" 2 "Message2" 1 "Message1" 0 "NoMessage" ;
VAL_ 1054 BrkBstrVac_D_Stat 3 "NotUsed" 2 "BoosterVacEstimator" 1 "BoosterVacSensor" 0 "NoBoosterVacuumMonitor" ;
VAL_ 1054 DrvSlipCtlOffLamp_D_Rq 3 "Fast_Flash" 2 "Slow_Flash" 1 "On" 0 "Off" ;
VAL_ 1054 DrvSlipCtlMdeMsg_D_Rq 31 "Message31" 30 "Message30" 29 "Message29" 28 "Message28" 27 "Message27" 26 "Message26" 25 "Message25" 24 "Message24" 23 "Message23" 22 "Message22" 21 "Message21" 20 "Message20" 19 "Message19" 18 "Message18" 17 "Message17" 16 "Message16" 15 "Message15" 14 "Message14" 13 "Message13" 12 "Message12" 11 "Message11" 10 "Message10" 9 "Message9" 8 "Message8" 7 "Message7" 6 "Message6" 5 "Message5" 4 "Message4" 3 "Message3" 2 "Message2" 1 "Message1" 0 "NoMessage" ;
VAL_ 1054 HdcOn_B_Ind 1 "On" 0 "Off" ;
VAL_ 1054 AutoHoldMsgTxt_D_Rq 15 "Message15" 14 "Message14" 13 "Message13" 12 "Message12" 11 "Message11" 10 "Message10" 9 "Message9" 8 "Message8" 7 "Message7" 6 "Message6" 5 "Message5" 4 "Message4" 3 "Message3" 2 "Message2" 1 "Message1" 0 "NoMessage" ;
VAL_ 1054 CtaBrk_D_Stat 3 "Denied" 2 "Active" 1 "Open" 0 "Closed" ;
VAL_ 1054 SelDrvMdeAwd_D_Rq 31 "Faulty" 30 "NotUsed_17" 29 "NotUsed_16" 28 "NotUsed_15" 27 "NotUsed_14" 26 "NotUsed_13" 25 "NotUsed_12" 24 "NotUsed_11" 23 "NotUsed_10" 22 "NotUsed_9" 21 "NotUsed_8" 20 "CustomMode" 19 "OnePedalDrive" 18 "DragMode" 17 "EvLaterChargeMode" 16 "EvNowMode" 15 "TrackMode" 14 "RoughRoadMode" 13 "NotAvailable" 12 "HighSpeedDesertMode_Baja" 11 "SportAdaptiveMode" 10 "RockCrawlMode" 9 "MudRutsMode" 8 "SandMode" 7 "EconomyMode" 6 "GrassGravelSnow" 5 "TowHaulMode" 4 "SportMode" 3 "Normal_4L" 2 "Normal_4A" 1 "Normal_2H" 0 "NormalMode" ;
VAL_ 1054 AutoHoldSwMde_B_Ind 1 "On" 0 "Off" ;
VAL_ 1054 AutoHoldMde_D_Ind 3 "Indication_3" 2 "Indication_2" 1 "Indication_1" 0 "Off" ;
VAL_ 1054 SelDrvMdeChassis_D_Rq 31 "Faulty" 30 "NotUsed17" 29 "NotUsed16" 28 "NotUsed15" 27 "NotUsed14" 26 "NotUsed13" 25 "NotUsed12" 24 "NotUsed11" 23 "NotUsed10" 22 "NotUsed9" 21 "NotUsed8" 20 "NotUsed7" 19 "NotUsed6" 18 "NotUsed5" 17 "NotUsed4" 16 "OnePedalDrive" 15 "DragMode" 14 "RoughRoadMode" 13 "TrackMode" 12 "HighSpeedDesertMode" 11 "TowHaulMode" 10 "RockCrawlMode" 9 "SandMode" 8 "MudAndRutsMode" 7 "LowMuMode" 6 "ComfortAdaptiveMode" 5 "ComfortMode" 4 "SportAdaptiveMode" 3 "SportMode" 2 "EconomyMode" 1 "NormalAdaptiveMode" 0 "NormalMode" ;
VAL_ 1054 ApaBrk_D_Stat 3 "Denied" 2 "Active" 1 "Open" 0 "Closed" ;
VAL_ 1052 AwdDcnntSlipTrgt_B_Rq 1 "Request" 0 "NoRequest" ;
VAL_ 1052 AwdCnnct_D_Stat 3 "Connecting" 2 "Disconnecting" 1 "Connected" 0 "Disconnected" ;
VAL_ 1052 AwdLck_Tq_Actl 4095 "Fault" 4094 "Unknown" ;
VAL_ 1009 RearAudioCtlLck_D_Rq 2 "Unlock" 1 "Lock" 0 "Null" ;
VAL_ 1009 ChrgCordUnlock_B_Rq 1 "Request" 0 "NoRequest" ;
VAL_ 1009 AutoHoldSwtch_D_Stat3 3 "Faulty" 2 "NotUsed" 1 "Pressed" 0 "Not_Pressed" ;
VAL_ 1009 TrlrAidCancl_B_Rq 1 "Cancel" 0 "Null" ;
VAL_ 1009 CenterStackRing_D_Actl 3 "LimitedOn" 2 "On" 1 "Off" 0 "Null" ;
VAL_ 1009 ValetMode_D_Stat 3 "NotUsed" 2 "On" 1 "Off" 0 "Null" ;
VAL_ 1009 TrlrAidSetup_D_Stat 7 "Faulty" 6 "NotUsed_3" 5 "NotUsed_2" 4 "NotUsed_1" 3 "EnterParameters" 2 "EndSetup" 1 "BeginSetup" 0 "Null" ;
VAL_ 1009 TrlrTrgtAcquire_D_Rq 7 "NotUsed_2" 6 "NotUsed_1" 5 "ActivateRVCforTBA" 4 "CancelAcquisition" 3 "RetryAcquisition" 2 "AcquisitionSuccessful" 1 "StartAcquisition" 0 "Inactive" ;
VAL_ 1121 OrtaSwtch_D_Stat2 3 "Faulty" 2 "NotUsed" 1 "Pressed" 0 "Not_Pressed" ;
VAL_ 1121 SelDrvMdeSwtch_D_Stat 3 "Faulty" 2 "SwitchState2" 1 "SwitchState1" 0 "NotPressed" ;
VAL_ 1121 SelDrvMdeCnt_D_Stat 4 "FourCounts" 3 "ThreeCounts" 2 "TwoCounts" 1 "OneCount" 0 "ZeroCounts" 7 "SevenOrMoreCounts" 6 "SixCounts" 5 "FiveCounts" ;
VAL_ 972 LaActAvail_D2_Actl 3 "Intervention_Available" 2 "NoIntervention_Available" 1 "Intervention_NotAvailable" 0 "NoIntervention_NotAvailabl" ;
VAL_ 972 LsmcBrkDecelEnbl_D_Rq 3 "NotUsed2" 2 "NotUsed1" 1 "On" 0 "Off" ;
VAL_ 972 TjaHandsOnCnfdnc_B_Est 1 "High_Confidence" 0 "Low_Confidence" ;
VAL_ 972 LaHandsOff_B_Actl 1 "Hands_Off" 0 "Hands_On" ;
VAL_ 972 LaActDeny_B_Actl 1 "LA_Denied" 0 "LA_Not_Denied" ;
VAL_ 972 LatCtlSte_D_Stat 7 "NotUsed3" 6 "NotUsed2" 5 "NotUsed1" 4 "Denied" 3 "RampOut" 2 "ContLatControlInProgress" 1 "Available" 0 "Unavailable" ;
VAL_ 972 LatCtlLim_D_Stat 3 "LimitWithDriverActive" 2 "LimitReached" 1 "LimitClose" 0 "LimitNotReached" ;
VAL_ 972 LatCtlCpblty_D_Stat 3 "Faulty" 2 "ExtendedModeAvailable" 1 "LimitedModeAvailable" 0 "NoModeAvailable" ;
VAL_ 930 BalrWndwRight_B_Stat 1 "Enable" 0 "Disable" ;
VAL_ 930 BalrSnsRight_D_Falt 3 "Invalid" 2 "SystemFailure" 1 "Blocked" 0 "Clear" ;
VAL_ 930 WndwPsngrRear_D_RqBalrr 3 "NotUsed" 2 "Stop" 1 "AutoUp" 0 "NoRequest" ;
VAL_ 930 WndwPsngr_D_RqBalrr 3 "NotUsed" 2 "Stop" 1 "AutoUp" 0 "NoRequest" ;
VAL_ 930 WndwDrvRear_D_RqBalrr 3 "NotUsed" 2 "Stop" 1 "AutoUp" 0 "NoRequest" ;
VAL_ 930 WndwDrv_D_RqBalrr 3 "NotUsed" 2 "Stop" 1 "AutoUp" 0 "NoRequest" ;
VAL_ 930 BalrRight_D_Stat 3 "Inhibited" 2 "Disabled" 1 "On" 0 "Off" ;
VAL_ 930 BalrMdeSelRight_B_Stat 1 "Enable" 0 "Disable" ;
VAL_ 930 BalrMdeRight_D_Stat 3 "NotUsed" 2 "High" 1 "Medium" 0 "Low" ;
VAL_ 930 BalrLckRight_B_Stat 1 "Enable" 0 "Disable" ;
VAL_ 930 BalrChimeRight_D_Rq 3 "NotUsed" 2 "Soft" 1 "Normal" 0 "Off" ;
VAL_ 930 CamraRearOn_B_RqBalrr 1 "Active" 0 "Inactive" ;
VAL_ 930 DrLckActv_B_RqBalrr 1 "Active" 0 "Null" ;
VAL_ 374 GearEngag_D_Actl 7 "Undefined" 6 "Fwd_Clutch_Fully_Engaged" 5 "Neutral_Idle" 4 "Disengaged_to_Neutral_Idle" 3 "Disengaged_to_Neutral_Park" 2 "Engagement_in_Progress" 1 "InitializeFwdClutchEngagmt" 0 "Park_Neutral" ;
VAL_ 374 TrnRng_D_Rq 15 "Fault" 14 "Unknown_Position" 13 "NotUsed_2" 12 "NotUsed_1" 11 "Range6" 10 "Range5" 9 "Range4" 8 "Range3_M3_L3" 7 "Range2_M2_L2" 6 "Range1_M1_L1" 5 "Low" 4 "Sport_DriveSport_Mposition" 3 "Drive" 2 "Neutral" 1 "Reverse" 0 "Park" ;
VAL_ 374 TrnPrkSys_D_Actl 15 "Faulty" 14 "NotUsed_5" 13 "NotUsed_4" 12 "NotUsed_3" 11 "NotUsed_2" 10 "NotUsed_1" 9 "FrequencyError" 8 "OutOfRangeHigh" 7 "OutOfRangeLow" 6 "Override" 5 "OutOfPark" 4 "TransitionCloseToOutOfPark" 3 "AtNoSpring" 2 "TransitionCloseToPark" 1 "Park" 0 "NotKnown" ;
VAL_ 374 GearLvr_D_ActlDrv 15 "Fault" 14 "Unknown_Position" 13 "NotUsed_2" 12 "NotUsed_1" 11 "Range6" 10 "Range5" 9 "Range4" 8 "Range3_M3_L3" 7 "Range2_M2_L2" 6 "Range1_M1_L1" 5 "Low" 4 "Sport_DriveSport_Mposition" 3 "Drive" 2 "Neutral" 1 "Reverse" 0 "Park" ;
VAL_ 374 GearPos_D_Trg 15 "Unknown" 14 "Reverse" 13 "Undefined_5" 12 "Undefined_4" 11 "Undefined_3" 10 "Tenth" 9 "Ninth" 8 "Eighth" 7 "Seventh" 6 "Sixth" 5 "Fifth" 4 "Fourth" 3 "Third" 2 "Second" 1 "First" 0 "Neutral" ;
VAL_ 374 GearPos_D_Actl 15 "Unknown" 14 "Reverse" 13 "Undefined_5" 12 "Undefined_4" 11 "Undefined_3" 10 "Tenth" 9 "Ninth" 8 "Eighth" 7 "Seventh" 6 "Sixth" 5 "Fifth" 4 "Fourth" 3 "Third" 2 "Second" 1 "First" 0 "Neutral" ;
VAL_ 359 ElPw_D_StatStrtStop 15 "NotUsed6" 14 "NotUsed5" 13 "NotUsed4" 12 "NotUsed3" 11 "NotUsed2" 10 "NotUsed1" 9 "Supported_Level_4" 8 "Supported_Level_3" 7 "Supported_Level_2" 6 "Supported_Level_1" 5 "Limited_Support" 4 "Fault_Limited" 3 "LV_Event_in_Progress" 2 "Not_Supported_Imminent" 1 "Supported_All" 0 "Not_Supported" ;
VAL_ 359 PrplWhlTot2_Tq_Actl 65535 "Fault" 65534 "NoDataExists" ;
VAL_ 359 PwPckTq_D_Stat 3 "PwPckOn_TqAvailable" 2 "StartInPrgrss_TqNotAvail" 1 "PwPckOn_TqNotAvailable" 0 "PwPckOff_TqNotAvailable" ;
VAL_ 359 Eng_D_Stat 3 "NotUsed" 2 "EngAutoStopped" 1 "EngOn" 0 "EngOff" ;
VAL_ 359 ElPw_D_Stat 7 "NotUsed_3" 6 "NotUsed_2" 5 "NotUsed_1" 4 "Fault_Limited" 3 "LV_Event_In_Progress" 2 "Not_Supported_Imminent" 1 "Supported" 0 "Not_Supported" ;
VAL_ 359 TrnAinTq_D_Qf 3 "OK" 2 "Not_Within_Specifications" 1 "No_Data_Exists" 0 "Faulty" ;
VAL_ 357 CcMde_D_Actl 7 "TapDownWaiting" 6 "TapUpWaiting" 5 "Resuming_Low" 4 "Resuming_High" 3 "Decelerating" 2 "Accelerating" 1 "Keeping_Speed" 0 "Not_Active" ;
VAL_ 357 BPedDrvAppl_D_Qf 3 "OK" 2 "Not_Within_Specifications" 1 "No_Data_Exists" 0 "Faulty" ;
VAL_ 357 CmbbDeny_B_ActlPrpl 1 "Yes" 0 "No" ;
VAL_ 357 PrplTqMnSat_B_Actl 1 "Yes" 0 "No" ;
VAL_ 357 BpedDrvAppl_D_Actl 3 "_Not_Allowed" 2 "Driver_Braking" 1 "Driver_Not_Braking" 0 "Not_Allowed" ;
VAL_ 357 CmbbEngTqMn_B_Actl 1 "Yes" 0 "No" ;
VAL_ 357 Veh_V_DsplyCcSet 255 "Fault" 254 "Unknown" ;
VAL_ 357 AccEngStat_D_Actl 7 "Undefined_2" 6 "Undefined_1" 5 "ACCSoonCancel_due_Low_Spd" 4 "Shift_Down_Recommendation" 3 "Shift_Up_Recommendation" 2 "ACCNotAllowedToBeActivated" 1 "ACCStandby_due_Auto_Cancel" 0 "Normal_Operation" ;
VAL_ 357 CcStat_D_Actl 7 "Undefined_2" 6 "Undefined_1" 5 "Active" 4 "Active_Que_Assist" 3 "Standby" 2 "Standby_Denied" 1 "Denied" 0 "Off" ;
VAL_ 357 CcOvrrdActv_B_Actl 1 "Cruise_Overridden" 0 "Cruise_Req_Not_Overridden" ;
VAL_ 357 AccStopMde_D_Rq 3 "Stop_Mode_Active" 2 "EPBApplyOrBrakeReleaseWarn" 1 "Limit_Rolling_Speed" 0 "Stop_Mode_Not_Active" ;
VAL_ 934 CtaAlrtLeft2_D_Stat 7 "NotUsed3" 6 "NotUsed2" 5 "NotUsed1" 4 "AlertZone4" 3 "AlertZone3" 2 "AlertZone2" 1 "AlertZone1" 0 "Off" ;
VAL_ 934 CtaBrkLeftMsgTxt_B_Rq 1 "Enable" 0 "Disable" ;
VAL_ 934 CtaLeftBrkDecel_B_Rq 1 "Enable" 0 "Disable" ;
VAL_ 934 CtaLeftBrkEnbl_B_Rq 1 "Enable" 0 "Disable" ;
VAL_ 934 BttLeft_D_Stat 7 "BTT5GFault" 6 "Disabled" 5 "Off" 4 "OffTemp" 3 "NotConnected" 2 "Pending" 1 "Connected" 0 "NotDetermined" ;
VAL_ 934 BttLeft_D_RqDrv 3 "NotUsed" 2 "Request" 1 "NoRequest" 0 "Null" ;
VAL_ 934 CtaSnsLeft_D_Stat 3 "Invalid" 2 "System_Failure" 1 "Blocked" 0 "Clear" ;
VAL_ 934 SodDetctLeft_D_Stat 4 "Sensor_Blocked" 3 "Sensor_Fault" 2 "Flash_On" 1 "Alert_On" 0 "AlertOff_FlashOff_SensrClr" ;
VAL_ 934 CtaLeft_D_Stat 7 "NotUsed_3" 6 "NotUsed_2" 5 "NotUsed_1" 4 "Invalid" 3 "Disabled" 2 "On" 1 "Trailer_Tow_Off" 0 "Off" ;
VAL_ 934 CtaAlrtLeft_D_Stat 1 "On" 0 "Off" ;
VAL_ 934 SodLeft_D_Stat 7 "NotUsed_3" 6 "NotUsed_2" 5 "NotUsed_1" 4 "Invalid" 3 "Disabled" 2 "On" 1 "Trailer_Tow_Off" 0 "Off" ;
VAL_ 934 SodSnsLeft_D_Stat 3 "Second_Warning_Audio" 2 "System_Failure" 1 "Blocked" 0 "Clear" ;
VAL_ 934 SodAlrtLeft_D_Stat 3 "Bulb_Proveout" 2 "Flash" 1 "On" 0 "Off" ;
VAL_ 929 BalrChimeLeft_D_Rq 3 "NotUsed" 2 "Soft" 1 "Normal" 0 "Off" ;
VAL_ 929 BalrLeft_D_Stat 3 "Inhibited" 2 "Disabled" 1 "On" 0 "Off" ;
VAL_ 929 WndwPsngrRear_D_RqBalrl 3 "NotUsed" 2 "Stop" 1 "AutoUp" 0 "NoRequest" ;
VAL_ 929 WndwPsngr_D_RqBalrl 3 "NotUsed" 2 "Stop" 1 "AutoUp" 0 "NoRequest" ;
VAL_ 929 WndwDrvRear_D_RqBalrl 3 "NotUsed" 2 "Stop" 1 "AutoUp" 0 "NoRequest" ;
VAL_ 929 WndwDrv_D_RqBalrl 3 "NotUsed" 2 "Stop" 1 "AutoUp" 0 "NoRequest" ;
VAL_ 929 BalrSnsLeft_D_Falt 3 "Invalid" 2 "SystemFailure" 1 "Blocked" 0 "Clear" ;
VAL_ 929 BalrMdeSelLeft_B_Stat 1 "Enable" 0 "Disable" ;
VAL_ 929 BalrMdeLeft_D_Stat 3 "NotUsed" 2 "High" 1 "Medium" 0 "Low" ;
VAL_ 929 BalrLckLeft_B_Stat 1 "Enable" 0 "Disable" ;
VAL_ 929 CamraRearOn_B_RqBalrl 1 "Active" 0 "Inactive" ;
VAL_ 929 DrLckActv_B_RqBalrl 1 "Active" 0 "Null" ;
VAL_ 929 BalrWndwLeft_B_Stat 1 "Enable" 0 "Disable" ;
VAL_ 126 StePinRelInit_An_Sns 65535 "Faulty" 65534 "NoDataExists" ;
VAL_ 126 StePinCompAnEst_D_Qf 3 "OK" 2 "Degraded" 1 "No_Data_Exists" 0 "Faulty" ;
VAL_ 1050 AutoHoldSwtch_D_Stat 3 "Faulty" 2 "NotUsed" 1 "Pressed" 0 "Not_Pressed" ;
VAL_ 1050 EcoInhbt_B_RqHvac 1 "Yes" 0 "No" ;
VAL_ 1050 LpdbPtc3_B_Rq 1 "On" 0 "Off" ;
VAL_ 1050 LpdbPtc2_B_Rq 1 "On" 0 "Off" ;
VAL_ 1050 LpdbPtc1_B_Rq 1 "On" 0 "Off" ;
VAL_ 1050 LpdbHeatWiprPrk_B_Rq 1 "On" 0 "Off" ;
VAL_ 1050 LpdbDfrstRearOn_B_Rq 1 "On" 0 "Off" ;
VAL_ 1050 SteWhlHeat_D_Rq 15 "NotUsed6" 14 "NotUsed5" 13 "NotUsed4" 12 "NotUsed3" 11 "NotUsed2" 10 "NotUsed1" 9 "Reserved_3" 8 "Reserved_2" 7 "Reserved_1" 6 "Level_3_Heating" 5 "Level_3_Heating_LS" 4 "Level_2_Heating" 3 "Level_2_Heating_LS" 2 "Level_1_Heating" 1 "Level_1_Heating_LS" 0 "Off" ;
VAL_ 1050 MirrorHeatOn_B_Rq 1 "True" 0 "False" ;
VAL_ 1050 Remote_Start_QuietMode 1 "Quiet" 0 "Not_Quiet" ;
VAL_ 1050 Outside_Air_Temp_Stat 255 "Invalid" 254 "Unknown" ;
VAL_ 1045 VehStab_D_Stat 15 "Faulty" 14 "No_Data_Exists" 13 "NotUsed6" 12 "NotUsed5" 11 "NotUsed4" 10 "NotUsed3" 9 "NotUsed2" 8 "Combined_OS_and_US" 7 "High_SSRA_no_OS" 6 "Straight" 5 "Post_Oversteer" 4 "Post_Transition" 3 "Countersteer" 2 "Understeer" 1 "Oversteer" 0 "Linear" ;
VAL_ 1045 BrkFluidLvl_D_Stat 3 "Invalid" 2 "Unknown" 1 "Low" 0 "OK" ;
VAL_ 1045 LsmcBrkDecel_D_Stat 7 "NotUsed_3" 6 "NotUsed_2" 5 "NotUsed_1" 4 "Denied" 3 "FaultDegraded" 2 "FaultExt" 1 "On" 0 "Off" ;
VAL_ 1045 VehYawNonLin_W_Rq 4095 "Fault" 4094 "Unknown" ;
VAL_ 1045 VehYawLin_W_Rq 4095 "Fault" 4094 "Unknown" ;
VAL_ 1045 VehVActlBrk_D_Qf 3 "OK" 2 "Not_Within_Specifications" 1 "No_Data_Exists" 0 "Faulty" ;
VAL_ 1044 ApaBrkErr_D_Stat 3 "Faulty" 2 "NoDataExists" 1 "Yes" 0 "No" ;
VAL_ 1044 StePinOffst_An_Est 65535 "Faulty" 65534 "NoDataExists" ;
VAL_ 1044 StePinOffst_D_Stat 3 "FineOffset" 2 "CoarseOffset" 1 "StoredOffset" 0 "OffsetNotCalculated" ;
VAL_ 765 Running_Board_Cmd 3 "Unused" 2 "Manually_Deployed" 1 "All_Enabled" 0 "All_Disabled" ;
VAL_ 765 BalrSwtch_D_Stat 3 "NotUsed" 2 "Pressed" 1 "NotPressed" 0 "Null" ;
VAL_ 765 BalrMde_D_Rq 3 "High" 2 "Medium" 1 "Low" 0 "Null" ;
VAL_ 765 RstrnOnPsngr_D_RqMnu 15 "Faulty" 14 "NotUsed_11" 13 "NotUsed_10" 12 "ConfiguredOff" 11 "NotUsed_9" 10 "On" 9 "NotUsed_8" 8 "NotUsed_7" 7 "NotUsed_6" 6 "NotUsed_5" 5 "Off" 4 "NotUsed_4" 3 "NotUsed_3" 2 "NotUsed_2" 1 "NotUsed_1" 0 "NoAction" ;
VAL_ 765 WaitToStartLamp_D_Falt 3 "NotUsed" 2 "Wait_to_start_lamp_failed" 1 "Diagnosis_not_ready" 0 "Wait_to_start_lamp_OK" ;
VAL_ 765 EsaOn_B_Rq 1 "On" 0 "Off" ;
VAL_ 765 BttOn_B_Rq 1 "On" 0 "Off" ;
VAL_ 765 Btt_L_Actl 127 "Faulty" 126 "NoDataExists" ;
VAL_ 765 SelDrvMdeTxtReset_B_Rq 1 "Yes" 0 "No" ;
VAL_ 765 DrvInputRequired_B_Rq 1 "Yes" 0 "No" ;
VAL_ 765 SelDrvMdeDsply_B_Avail 1 "Available" 0 "NotAvailable" ;
VAL_ 765 Mc_VehUntTrpCoUsrSel_St 0 "TripComputer_metric" 1 "TripComputer_imperial" ;
VAL_ 765 Mc_VehUnitTempUsrSel_St 0 "Temperature_deg_c" 1 "Temperature_deg_f" ;
VAL_ 765 Mc_VehTimeFrmtUsrSel_St 2 "24h_mode" 1 "12h_mode" 0 "Invalid" ;
VAL_ 765 Mc_VehLangUsrSel_St 33 "Ukrainian" 32 "Indian_English" 31 "Thai" 30 "Slovak" 29 "Arabic" 28 "Taiwanese" 27 "Mandarin_Chinese" 26 "Korean" 25 "AU_English" 24 "Japanese" 23 "Braz_Portuguese" 22 "EU_Portuguese" 21 "Finish" 20 "Norwegian" 19 "Danish" 18 "Swedish" 17 "Hungarian" 16 "Greek" 15 "Czech" 14 "Polish" 13 "Flemish" 12 "Dutch" 11 "Russian" 10 "Turkish" 9 "Mex_Spanish" 8 "EU_Spanish" 7 "Cana_French" 6 "EU_French" 5 "Italian" 4 "German" 3 "NA_English" 2 "UK_English" 1 "Unknown" 0 "Invalid" ;
VAL_ 765 AwdRnge_D_ActlIpc 7 "Unknown" 6 "High_Range_2wd" 5 "High_Range_Auto" 4 "High_Range_Locked" 3 "Neutral" 2 "Low_Range_2wd" 1 "Low_Range_Auto" 0 "Low_Range_Locked" ;
VAL_ 765 EdmSailMde_B_RqDrv 1 "On" 0 "Off" ;
VAL_ 560 TrnCnvtClu_D_Actl 3 "Transition_or_Micro_Slip" 2 "Lock_Up_Fixed" 1 "Lock_Up_Slip" 0 "No_Lock_Up" ;
VAL_ 560 TrnGbox_Rt_Actl 65535 "Fault" 65534 "Unknown" ;
VAL_ 560 GboxOil_Te_Actl 255 "Faulty" 254 "NoDataExists" ;
VAL_ 560 TrnSrvcRqd_B_Rq 1 "On" 0 "Off" ;
VAL_ 560 SelDrvMdeSwtch_D_Stat3 3 "Faulty" 2 "SwitchState2" 1 "SwitchState1" 0 "NotPressed" ;
VAL_ 560 TrnShifActv_B_Actl 1 "Active" 0 "Inactive" ;
VAL_ 560 BtsiShifInhbt_B_RqTrn 1 "Yes" 0 "No" ;
VAL_ 560 GearLvrPos_D_Actl 15 "Fault" 14 "Unknown_Position" 13 "Undefined_Treat_as__Fault" 12 "Undefined_Treat_as_Fault" 11 "sixth" 10 "fifth" 9 "fourth" 8 "third" 7 "second" 6 "first" 5 "Low" 4 "Sport_DriveSport" 3 "Drive" 2 "Neutral" 1 "Reverse" 0 "Park" ;
VAL_ 551 VehPerfDemo_B_RqDrv 1 "On" 0 "Off" ;
VAL_ 551 PrkBrkPerfMnuOn_D_Stat 3 "Faulty" 2 "NotUsed" 1 "On" 0 "Off" ;
VAL_ 551 PrkBrkPerfButtn_D_Stat 3 "Faulty" 2 "NotUsed" 1 "Pressed" 0 "Not_Pressed" ;
VAL_ 551 EcoIdl_D_Rq 3 "NotUsed" 2 "Enabled" 1 "Disabled" 0 "Null" ;
VAL_ 551 OneTEditActv_B_RqMnu 1 "Yes" 0 "No" ;
VAL_ 551 PrcondEdit_D_RqMnu 7 "NotUsed_3" 6 "NotUsed_2" 5 "NotUsed_1" 4 "High" 3 "Medium" 2 "Low" 1 "Off" 0 "Null" ;
VAL_ 551 BattTracLoThres_D_Rq 7 "NotUsed" 6 "Thres80km_50mi" 5 "Thres50km_31mi" 4 "Thres30km_18mi" 3 "Thres50mi_80km" 2 "Thres30mi_48km" 1 "Thres20mi_32km" 0 "Null" ;
VAL_ 551 ChrgToPcEdit_Pc_RqMnu 127 "Faulty" 126 "NoDataExists" ;
VAL_ 551 Cntr_Plg_Mode_Cmd 1 "Enable" 0 "Disable" ;
VAL_ 551 Btt_L_Actl2 127 "Faulty" 126 "NoDataExists" ;
VAL_ 551 PwRnngBoardT_D_Rq 3 "NotUsed" 2 "Timer2" 1 "Timer1" 0 "Inactive" ;
VAL_ 551 PwRnngBoardMde_D_Rq 0 "Inactive" 1 "Off" 2 "Out" 3 "Auto" ;
VAL_ 551 PwRnngBoardSwtch_D_Rq 3 "NotUsed" 2 "DeployUnlocked" 1 "AlwaysActive" 0 "Inactive" ;
VAL_ 551 Rba_D_Rq 3 "NotUsed" 2 "On" 1 "Off" 0 "Null" ;
VAL_ 551 EmPrflNo_D_Rq 7 "NotUsed_3" 6 "NotUsed_2" 5 "NotUsed_1" 4 "Pers4" 3 "Pers3" 2 "Pers2" 1 "Pers1" 0 "Null" ;
VAL_ 551 EmPrflButtnAssoc_D_Rq 3 "NotUsed" 2 "ExitButtonAssociation" 1 "EnterButtonAssociation" 0 "Null" ;
VAL_ 551 EmPrflKeyAssoc_D_Rq 7 "NotUsed_3" 6 "DisassociatePhone" 5 "EnterPhoneAssociation" 4 "OverwriteKey" 3 "DisassociateKey" 2 "ExitKeyAssociation" 1 "EnterKeyAssociation" 0 "Null" ;
VAL_ 551 Em_D_Stat 3 "NotSupported" 2 "ProfilesOff" 1 "ProfilesOn" 0 "Null" ;
VAL_ 551 PmCabnLvl_D_Stat 7 "NotUsed_1" 6 "Level_6_Worst" 5 "Level_5" 4 "Level_4" 3 "Level_3" 2 "Level_2" 1 "Level_1_Best" 0 "NotKnown" ;
VAL_ 551 PmCabn_D_Stat 3 "FilteringComplete" 2 "FilteringOn" 1 "FilteringOff" 0 "NotKnown" ;
VAL_ 551 ChrgCrdLckEnbl_B_Stat 1 "Enable" 0 "Disable" ;
VAL_ 551 ChrgOvrdExitScrn_D_Rq 3 "NotUsed_1" 2 "Request_override" 1 "Do_not_request_override" 0 "Inactive" ;
VAL_ 551 TjaLaneBiasEnbl_D_RqMnu 3 "NotUsed" 2 "Enabled" 1 "Disabled" 0 "Null" ;
VAL_ 358 StopStrtStdby_D_Indic 6 "Telltale_On_Grey" 5 "Telltale_Struck_Out" 4 "Telltale_Flashing_Amber" 3 "Telltale_On_Amber" 2 "Telltale_Flashing_Green" 1 "Telltale_On_Green" 0 "Telltale_Off" 7 "NotUsed3" ;
VAL_ 358 StopStrtIODTxt_D_Rq 31 "Message31" 30 "Message30" 29 "Message29" 28 "Message28" 27 "Message27" 26 "Message26" 25 "Message25" 24 "Message24" 23 "Message23" 22 "Message22" 21 "Message21" 20 "Message20" 19 "Message19" 18 "Message18" 17 "Message17" 16 "Message16" 15 "Message15" 14 "Message14" 13 "Message13" 12 "Message12" 11 "Message11" 10 "Message10" 9 "Message9" 8 "Message8" 7 "Message7" 6 "Message6" 5 "Message5" 4 "Message4" 3 "Message3" 2 "Message2" 1 "Message1" 0 "NoMessage" ;
VAL_ 358 StopStrtDrvMde_D_Indic 3 "NotUsed" 2 "StartStop_IndirectDeselect" 1 "StopStart_Deselected" 0 "StopStart_Selected" ;
VAL_ 358 StopStrtMsgTxt_D_Rq 15 "Message_15" 14 "Message_14" 13 "Message_13" 12 "Message_12" 11 "Message_11" 10 "Message_10" 9 "Message_9" 8 "Message_8" 7 "Message_7" 6 "Message_6" 5 "Message_5" 4 "Message_4" 3 "Message_3" 2 "Message_2" 1 "Message_1" 0 "NoMessage" ;
VAL_ 358 OdoTripVerify_L_Actl 16777215 "Fault" ;
VAL_ 358 HiElPwInhbt_B_Stat 1 "Inhibit" 0 "No_Inibit" ;
VAL_ 358 AutoStopPtDelta_I_Est 255 "Fault" ;
VAL_ 673 ICI_Coding_BtnID_D 15 "Idle" 5 "Stuck" 4 "LongEvent" 3 "ShortElapsed" 2 "ShortEvent" 1 "Active" 0 "Inactive" ;
VAL_ 673 ICI_Coding_BtnID_C 15 "Idle" 5 "Stuck" 4 "LongEvent" 3 "ShortElapsed" 2 "ShortEvent" 1 "Active" 0 "Inactive" ;
VAL_ 673 ICI_Coding_BtnID_B 15 "Idle" 5 "Stuck" 4 "LongEvent" 3 "ShortElapsed" 2 "ShortEvent" 1 "Active" 0 "Inactive" ;
VAL_ 673 ICI_Coding_BtnID_A 15 "Idle" 5 "Stuck" 4 "LongEvent" 3 "ShortElapsed" 2 "ShortEvent" 1 "Active" 0 "Inactive" ;
VAL_ 990 PersIndexDdm_D_Actl 7 "Unused_3" 6 "Unused_2" 5 "Unused_1" 4 "Vehicle" 3 "PERS_4" 2 "PERS_3" 1 "PERS_2" 0 "PERS_1" ;
VAL_ 1100 WakeAlarm1_B_Typ 1 "CanAndEcuDriveCircuit" 0 "CanOnly" ;
VAL_ 1100 TrnNtrlIdlExit_B_Rq 1 "Active" 0 "Inactive" ;
VAL_ 1100 Veh_V_DsplyTrailCtlSet 63 "Faulty" ;
VAL_ 1100 TrailCtlPt_B_Falt 1 "Fault" 0 "NoFault" ;
VAL_ 1100 TrnNtrlIdlInhbt_B_Rq 1 "Inhibit" 0 "NoInhibit" ;
VAL_ 1100 GrossTrainWeight_M_Est 255 "Faulty" 254 "NoDataExists" ;
VAL_ 1100 HvacCmprLim_D_Stat 7 "NotUsed_2" 6 "NotUsed_1" 5 "CompressorHeadPressure" 4 "AvailableTorque" 3 "PedalPosition" 2 "RPM" 1 "ECT" 0 "NoLimit" ;
VAL_ 1091 WakeAlarm2_B_Typ 1 "CanAndEcuDriveCircuit" 0 "CanOnly" ;
VAL_ 1091 TrlrAlarmSpprt_D_Stat 3 "SupportedByBrakesAndLights" 2 "SupportedByLights" 1 "SupportedByBrakes" 0 "NotSupported" ;
VAL_ 1091 TrlrBattChrg_D_Stat 3 "Reverse" 2 "Normal" 1 "Low" 0 "Null" ;
VAL_ 1091 TurnLampTrlrRr_B_Stat 1 "Out" 0 "Null" ;
VAL_ 1091 TurnLampTrlrRl_B_Stat 1 "Out" 0 "Null" ;
VAL_ 1091 TrlrLampCtl_D_Stat 3 "NotUsed" 2 "TrlrLampCnnctDrvFailure" 1 "TrlrLampNotCnnctDrvFailure" 0 "Null" ;
VAL_ 1091 TrlrLampCnnct_B_Actl 1 "Yes" 0 "No" ;
VAL_ 819 WndwPsngrSide_D_Stat 3 "BothWindow_Operating" 2 "RearWindow_Operating" 1 "FrontWindow_Operating" 0 "NoWindows_Operating" ;
VAL_ 819 BLISLEDStatPassSide 3 "Fault" 2 "Unused" 1 "On" 0 "Off" ;
VAL_ 819 Pasngr_Lock_Sw_Stat 3 "Invalid" 2 "Unlock" 1 "Lock" 0 "Null" ;
VAL_ 819 ChildLckFdbckRp_B_Stat 1 "Locked" 0 "Unlock" ;
VAL_ 818 DrvSpotLight_B_Stat 1 "Active" 0 "Inactive" ;
VAL_ 818 WndwDrvSide_D_Stat 3 "BothWindow_Operating" 2 "RearWindow_Operating" 1 "FrontWindow_Operating" 0 "NoWindows_Operating" ;
VAL_ 818 RvrseMirrorChime_B_Rq 1 "Yes" 0 "No" ;
VAL_ 818 BLISLEDStatDriverSide 3 "Fault" 2 "Unused" 1 "On" 0 "Off" ;
VAL_ 818 KeyCylSwDrvDr_D_Stat 3 "NotUsed" 2 "Unlock" 1 "Lock" 0 "Null" ;
VAL_ 818 Driver_Lock_Sw_Stat 3 "Invalid" 2 "Unlock" 1 "Lock" 0 "Null" ;
VAL_ 818 ChildLckPw_D_Rq 1 "Active" 0 "Null" ;
VAL_ 818 ChildLckFdbckRd_B_Stat 1 "Locked" 0 "Unlock" ;
VAL_ 1046 TRLR_SWAY_EVNT_IN_PROG 1 "Yes" 0 "No" ;
VAL_ 1046 TRLR_SWAY_CONFIG_STAT 1 "On" 0 "Off" ;
VAL_ 1046 HsaMde_D_Mem 3 "Undefined" 2 "Manual" 1 "Automatic" 0 "Off" ;
VAL_ 1046 BrkBstrVac_B_Rq 1 "Yes" 0 "No" ;
VAL_ 1046 DrvSlipCtlMde_D_Ind 3 "App_Specific_Off_Mode_3" 2 "App_Specific_Off_Mode_2" 1 "App_Specific_Off_Mode_1" 0 "Default_Mode" ;
VAL_ 1046 DrvAntiLckLamp_D_Rq 3 "Fast_Flash" 2 "Slow_Flash" 1 "On" 0 "Off" ;
VAL_ 1046 StabCtlBrk_B_Avail 1 "Yes" 0 "No" ;
VAL_ 1046 DrvHdcWarnInfo_D_Rq 3 "Undefined" 2 "Lamp_On_Continuously" 1 "Lamp_Flashing" 0 "Lamp_Off_Continuously" ;
VAL_ 1046 DrvHdcMsg_D_Rq 7 "Undefined" 6 "Speed_too_High" 5 "Temporarily_Unavailable" 4 "System_Fault" 3 "Select_Gear" 2 "Off" 1 "On" 0 "No_Message" ;
VAL_ 1046 DrvHdcLampInfo_D_Rq 3 "Fast_Flash" 2 "Slow_Flash" 1 "On" 0 "Off" ;
VAL_ 1046 ChimeBrk_B_Rq 1 "Yes" 0 "No" ;
VAL_ 1046 BrkLamp_B_Rq 1 "Yes" 0 "No" ;
VAL_ 1046 HILL_DESC_MC 7 "Fault_Detected" 6 "Cooling_Down" 5 "Abort_Apply_Brakes" 4 "Active" 3 "Disabled" 2 "Enabled" 1 "Off_Road" 0 "Normal" ;
VAL_ 1046 RearDiffLck_Tq2_RqMx 4095 "Faulty" ;
VAL_ 1046 HdcMde_D_Actl 7 "Fault" 6 "Temporarily_Unavailable" 5 "NotEnabled_WrongGearSel" 4 "NotEnabled_SpdLimitExceed" 3 "Active_Braking" 2 "Not_Active_Braking" 1 "Off" 0 "Undefined" ;
VAL_ 1046 TCMode 1 "Active" 0 "Inactive" ;
VAL_ 1046 DrvSlipCtlLamp_D_Rq 3 "Fast_Flash" 2 "Slow_Flash" 1 "On" 0 "Off" ;
VAL_ 1046 Abs_B_Falt 1 "Yes" 0 "No" ;
VAL_ 1046 BpedMove_D_Actl 3 "Unknown" 2 "DriverApplyingBrakePedal" 1 "NoAutonomousBrkPdlMovement" 0 "AutonomousBrkPedalMove" ;
VAL_ 1046 RearDiffElckrOpen_B_Rq 1 "Yes" 0 "No" ;
VAL_ 342 EngClntTe_D_Qf 3 "OK" 2 "Not_Within_Specifications" 1 "No_Data_Exists" 0 "Faulty" ;
VAL_ 342 EngOvrhtMitgActv_D_Ind 3 "Undefined" 2 "Mode2" 1 "Mode1" 0 "Normal_Mode" ;
VAL_ 342 EngOil_Te_Actl 255 "Fault" 254 "Unknown" ;
VAL_ 342 EngTeColdPrtct_B_Rq 1 "On" 0 "Off" ;
VAL_ 369 TrnIpcDsplyRng2_D_Actl 15 "No_Range_Selected" 14 "Range_14" 13 "Range_13" 12 "Range_12" 11 "Range_11" 10 "Range_10" 9 "Range_9" 8 "Range_8" 7 "Range_7" 6 "Range_6" 5 "Range_5" 4 "Range_4" 3 "Range_3" 2 "Range_2" 1 "Range_1" 0 "NotUsed" ;
VAL_ 369 TrnIpcDsplyRng_D_Stat 3 "NotUsed" 2 "Flash" 1 "On" 0 "Blank_No_Display" ;
VAL_ 369 SeatWorkSrfc_B_Falt 1 "Active" 0 "Inactive" ;
VAL_ 369 TrnIpcDsplyMde_D_Actl 7 "Manual_3" 6 "Manual_2" 5 "Manual_1_Low" 4 "Sport" 3 "Drive" 2 "Neutral" 1 "Reverse" 0 "Park" ;
VAL_ 369 TrnIpcDsplyGear_D_Stat 3 "Reserved_Blank_No_Display" 2 "Flash" 1 "On" 0 "Blank_No_Display" ;
VAL_ 369 TrnIpcDsplyMde_D_Stat 3 "Reserved_Blank_No_Display" 2 "Flash" 1 "On" 0 "Blank_No_Display" ;
VAL_ 369 TrnIpcDsplyGear_D_Actl 15 "No_Gear_Selected" 14 "_14th_Gear" 13 "_13th_Gear" 12 "_12th_Gear" 11 "_11th_Gear" 10 "_10th_Gear" 9 "_9th_Gear" 8 "_8th_Gear" 7 "_7th_Gear" 6 "_6th_Gear" 5 "_5th_Gear" 4 "_4th_Gear" 3 "_3rd_Gear" 2 "_2nd_Gear" 1 "_1st_Gear" 0 "Neutral" ;
VAL_ 369 CrawlMdeActv_B_Stat 1 "On" 0 "Off" ;
VAL_ 862 EcoMde_D_RqDrv 3 "Faulty" 2 "On" 1 "Off" 0 "Null" ;
VAL_ 862 HvacBlwrFront_D_Stat 31 "Not_Used" 20 "Full_On" 19 "95_Percent" 18 "90_Percent" 17 "85_Percent" 16 "80_Percent" 15 "75_Percent" 14 "70_Percent" 13 "65_Percent" 12 "60_Percent" 11 "55_Percent" 10 "50_Percent" 9 "45_Percent" 8 "40_Percent" 7 "35_Percent" 6 "30_Percent" 5 "25_Percent" 4 "20_Percent" 3 "15_Percent" 2 "10_Percent" 1 "5_Percent" 0 "Off" ;
VAL_ 862 CabnAmb_Te_Actl 255 "Fault" ;
VAL_ 862 ClimtThrmlLoad_No_Actl 255 "Fault" ;
VAL_ 862 CamraDefog_B_Actl 1 "On" 0 "Off" ;
VAL_ 862 AutoStpHvacDelta_I_Est 255 "Fault" ;
VAL_ 146 VehVertAActl_D_Qf 3 "OK" 2 "Not_Within_Specifications" 1 "No_Data_Exists" 0 "Faulty" ;
VAL_ 146 VehVert2_A_Actl 8191 "Faulty" 8190 "NoDataExists" ;
VAL_ 146 VehLongAActl_D_Qf 3 "OK" 2 "Not_Within_Specifications" 1 "No_Data_Exists" 0 "Faulty" ;
VAL_ 146 VehLatAActl_D_Qf 3 "OK" 2 "Not_Within_Specifications" 1 "No_Data_Exists" 0 "Faulty" ;
VAL_ 146 VehLat2_A_Actl 8191 "Faulty" 8190 "NoDataExists" ;
VAL_ 146 VehLong2_A_Actl 8191 "Faulty" 8190 "NoDataExists" ;
VAL_ 992 MsgCntrDsplyOp_D_Rq 7 "Unused_2" 6 "Unused_1" 5 "Copy" 4 "Restore" 3 "Upload" 2 "Set" 1 "Query" 0 "Null" ;
VAL_ 992 MsgCntrPersIndex_D_Rq 7 "Unused_3" 6 "Unused_2" 5 "Unused_1" 4 "Vehicle" 3 "PERS_4" 2 "PERS_3" 1 "PERS_2" 0 "PERS_1" ;
VAL_ 994 PersCtaSplitView_D_Rq 3 "EnabledFull" 2 "Enabled_180SwitchOnly" 1 "Disabled" 0 "Null" ;
VAL_ 994 PersStore_D_Rq 7 "Unused_2" 6 "Unused_1" 5 "Vehicle" 4 "PERS_4" 3 "PERS_3" 2 "PERS_2" 1 "PERS_1" 0 "Null" ;
VAL_ 994 Pers4OptIn_B_Stats 1 "OPTED_IN" 0 "NOT_OPTED_IN" ;
VAL_ 994 Pers3OptIn_B_Stats 1 "OPTED_IN" 0 "NOT_OPTED_IN" ;
VAL_ 994 Pers2OptIn_B_Stats 1 "OPTED_IN" 0 "NOT_OPTED_IN" ;
VAL_ 994 Pers1OptIn_B_Stats 1 "OPTED_IN" 0 "NOT_OPTED_IN" ;
VAL_ 994 CtrStkPersIndex_D_Actl 7 "Unused_3" 6 "Unused_2" 5 "Unused_1" 4 "Vehicle" 3 "PERS_4" 2 "PERS_3" 1 "PERS_2" 0 "PERS_1" ;
VAL_ 994 CtrStkDsplyOp_D_Rq 7 "Unused_2" 6 "Unused_1" 5 "Copy" 4 "Restore" 3 "Upload" 2 "Set" 1 "Query" 0 "Null" ;
VAL_ 998 PersIndexSccm_D_Actl 7 "Unused_3" 6 "Unused_2" 5 "Unused_1" 4 "Vehicle" 3 "PERS_4" 2 "PERS_3" 1 "PERS_2" 0 "PERS_1" ;
VAL_ 828 DrvSpotLight_B_Rq 1 "Yes" 0 "No" ;
VAL_ 828 SpotLghtRight_D_Stat 1 "On" 0 "Off" ;
VAL_ 828 RearPassWindowPos 7 "Unused2" 6 "Unused1" 5 "Fully_Open" 4 "Bet60Percent_FullyOpen" 3 "Bet10Percent_60Percent" 2 "BetFully_10PercentOpen" 1 "Fully_Closed" 0 "Undefined" ;
VAL_ 828 PassWindowPosition 7 "Unused2" 6 "Unused1" 5 "Fully_Open" 4 "Bet60Percent_FullyOpen" 3 "Bet10Percent_60Percent" 2 "BetFully_10PercentOpen" 1 "Fully_Closed" 0 "Undefined" ;
VAL_ 828 SpotLghtLeft_D_Stat 1 "On" 0 "Off" ;
VAL_ 943 VehVActlAdas_D_Qf 3 "OK" 2 "Not_Within_Specifications" 1 "No_Data_Exists" 0 "Faulty" ;
VAL_ 943 AdasLcDistToObj_L_Actl 4095 "Faulty" 4094 "NoDataExists" ;
VAL_ 549 StrtInGearOk_D_Stat 3 "NotUsed" 2 "Accepted" 1 "NotAccepted" 0 "Null" ;
VAL_ 549 MetricActv_B_Dsply 1 "Active" 0 "Inactive" ;
VAL_ 549 NavIod_D_Rq 7 "NotUsed_5" 6 "NotUsed_4" 5 "NotUsed_3" 4 "NotUsed_2" 3 "NotUsed_1" 2 "ModeChange" 1 "VideoOutput" 0 "NoRequest" ;
VAL_ 549 IPC_MyKeyVolLimit_St 0 "Invalid" 1 "Off" 2 "On" ;
VAL_ 549 HdcOn_B_Rq 1 "On" 0 "Off" ;
VAL_ 549 IPC_Attn_Info_Audio 7 "Unknown" 6 "Attenuation_6" 5 "Attenuation_5" 4 "Attenuation_4" 3 "Attenuation_3" 2 "Attenuation_2" 1 "Attenuation_1" 0 "No_Attenuation_of_Audio" ;
VAL_ 549 BeltminderAudioMute 2 "On" 1 "Off" 0 "Invalid" ;
VAL_ 549 Power_Up_Chime_Modules 1 "Active" 0 "Inactive" ;
VAL_ 549 Chime_Source 2 "Cluster" 1 "Infotainment_Sys" 0 "Invalid" ;
VAL_ 549 IPC_New_Attn_Event 1 "Active" 0 "Inactive" ;
VAL_ 549 HudRotatMnuOn_B_Rq 1 "Yes" 0 "No" ;
VAL_ 549 HudVertMnuOn_B_Rq 1 "Yes" 0 "No" ;
VAL_ 549 HudBrightMnuOn_B_Rq 1 "Yes" 0 "No" ;
VAL_ 549 CCOI_PolicyClient_St2 15 "NotUsed_4" 14 "NotUsed_3" 13 "NotUsed_2" 12 "NotUsed_1" 11 "DataStorageError" 10 "StateMachineInconsistent" 9 "UnrecoverableSyncError" 8 "OnBoardSyncFailed" 7 "OnBoardImplemented" 6 "OnBoardSynchronized" 5 "OnBoardSynchronizing" 4 "OnBoardSyncNeeded" 3 "OffBoardUpdatePending" 2 "OnBoardUpdatePending" 1 "Waiting" 0 "Null" ;
VAL_ 549 FactoryReset_Rq2 1 "ResetFactoryDefaults" 0 "Inactive" ;
VAL_ 947 ValetMode_D_Mem 1 "On" 0 "Off" ;
VAL_ 947 DrStatDrvErrCnt_B_Stat 1 "Yes" 0 "No" ;
VAL_ 947 TurnLghtRight_D_Rq 3 "Seq" 2 "On" 1 "Off" 0 "Null" ;
VAL_ 947 TurnLghtRightOn_B_Stat 1 "On" 0 "Off" ;
VAL_ 947 TurnLghtLeftOn_B_Stat 1 "On" 0 "Off" ;
VAL_ 947 FogLghtRearOn_B_Stat 1 "On" 0 "Off" ;
VAL_ 947 Backlit_LED_Status 15 "Unused3" 14 "Unused2" 13 "Unused1" 12 "Night_12" 11 "Night_11" 10 "Night_10" 9 "Night_9" 8 "Night_8" 7 "Night_7" 6 "Night_6" 5 "Night_5" 4 "Night_4" 3 "Night_3" 2 "Night_2" 1 "Night_1" 0 "Off" ;
VAL_ 947 TurnLghtLeft_D_Rq 3 "Seq" 2 "On" 1 "Off" 0 "Null" ;
VAL_ 947 FogLghtFrontOn_B_Stat 1 "On" 0 "Off" ;
VAL_ 947 IgnKeyType_D_Actl 15 "Invalid" 14 "Unknown" 3 "Key_Not_Prgrm_Read_Failure" 2 "Key_In_Ign_My_Key" 1 "Key_In_Ign_Standard_Key" 0 "Key_Read_In_Progress" ;
VAL_ 947 Parklamp_Status 3 "Invalid" 2 "Unknown" 1 "On" 0 "Off" ;
VAL_ 947 Litval 255 "Invalid" 254 "Unknown" 5 "Day" 4 "Twilight_4" 3 "Twilight_3" 2 "Twilight_2" 1 "Twilight_1" 0 "Night" ;
VAL_ 947 Key_In_Ignition_Stat 1 "In" 0 "Out" ;
VAL_ 947 Ignition_Status 0 "Unknown" 1 "Off" 15 "Invalid" 8 "Start" 4 "Run" 2 "Accessory" ;
VAL_ 947 Dimming_Lvl 255 "Invalid" 254 "Unknown" 18 "Day_6" 17 "Day_5" 16 "Day_4" 15 "Day_3" 14 "Day_2" 13 "Day_1" 12 "Night_12" 11 "Night_11" 10 "Night_10" 9 "Night_9" 8 "Night_8" 7 "Night_7" 6 "Night_6" 5 "Night_5" 4 "Night_4" 3 "Night_3" 2 "Night_2" 1 "Night_1" 0 "Off" ;
VAL_ 947 Day_Night_Status 3 "NotUsed" 2 "Night" 1 "Day" 0 "Null" ;
VAL_ 947 Remote_Start_Status 3 "Invalid" 2 "Unknown" 1 "Remote" 0 "Null" ;
VAL_ 947 DrStatTgate_B_Actl 1 "Ajar" 0 "Closed" ;
VAL_ 947 DrStatRr_B_Actl 1 "Ajar" 0 "Closed" ;
VAL_ 947 DrStatRl_B_Actl 1 "Ajar" 0 "Closed" ;
VAL_ 947 DrStatPsngr_B_Actl 1 "Ajar" 0 "Closed" ;
VAL_ 947 DrStatInnrTgate_B_Actl 1 "Ajar" 0 "Closed" ;
VAL_ 947 DrStatHood_B_Actl 1 "Ajar" 0 "Closed" ;
VAL_ 947 DrStatDrv_B_Actl 1 "Ajar" 0 "Closed" ;
VAL_ 947 PrkBrkActv_B_Actl 1 "Active" 0 "Inactive" ;
VAL_ 947 LifeCycMde_D_Actl 3 "Transport" 2 "NotUsed" 1 "Factory" 0 "Normal" ;
VAL_ 947 Delay_Accy 1 "On" 0 "Off" ;
VAL_ 947 CrashEvnt_D_Stat 3 "Invalid" 2 "Fuel_Cutoff_Event" 1 "Deploy_Event" 0 "No_Event" ;
VAL_ 947 FuelPmpInhbt_B_Stat 1 "Inhibit" 0 "No_Inibit" ;
VAL_ 947 BodySrvcRqd_B_Rq 1 "Yes" 0 "No" ;
VAL_ 1068 EngStrtInhbt_B_RqBatt 1 "Start_Inhibit" 0 "Dont_Care" ;
VAL_ 1068 BattULoChrg_D_Rq 3 "Low_Battery_Temperature" 2 "Charging_Requested" 1 "Chrg_Requested_HighCurrent" 0 "No_Request" ;
VAL_ 1068 PwSysULoFalt_D_Stat 15 "Not_Used_6" 14 "LowBatterySOC" 13 "PSS_Shed2_Contin" 12 "Not_Used_4" 11 "Not_Used_3" 10 "Not_Used_2" 9 "BattMonitoringSensorFault" 8 "LowBattVoltDuringPwSrcOn" 7 "LowBatt2_PowerSaveMode" 6 "LowBatt1_Warning" 5 "Overvoltage" 4 "Fault_NoOutput" 3 "Fault_ReducedOutput" 2 "Fault_Nonspecific" 1 "Cluster_Proveout" 0 "No_Fault" ;
VAL_ 1068 Shed_T_Eng_Off_B 1 "Active" 0 "Inactive" ;
VAL_ 1068 Shed_Feature_Group_ID 16 "PtcHeater" 30 "NotUsed_7" 29 "NotUsed_6" 28 "NotUsed_5" 27 "NotUsed_4" 26 "NotUsed_3" 25 "NotUsed_2" 24 "NotUsed_1" 23 "Dcac" 22 "UpFitter_6" 21 "UpFitter_5" 20 "UpFitter_4" 19 "UpFitter_3" 18 "UpFitter_2" 17 "UpFitter_1" 14 "HtdMirr" 13 "HvacRearBlwr_Third" 12 "HvacRearBlwr_Second" 11 "HvacRearBlwr_First" 31 "All LSHED1 Features" 10 "Htd_Windscrn" 9 "SpltHtdBcklight_HtdMirr" 8 "HtdBcklight_HtdMirr" 7 "HtdCoolSeat_FrtDriver" 6 "HtdCoolSeat_FrtPass" 5 "HtdCoolSeat_RearPass" 4 "HtdCoolSeat_RearDriver" 3 "SmartTrlrTowBattCharge" 2 "Htd_StrWhl" 1 "Htd_Washer_Fluid" 0 "No_LSHED1_Features" 15 "Engine_Coolant_Fan" ;
VAL_ 1068 Shed_Drain_Eng_Off_B 1 "Active" 0 "Inactive" ;
VAL_ 1068 Shed_Level_Req 7 "SHED3" 6 "Loads_On" 5 "SHED_ENG_OFF" 4 "SOON_ENG_OFF" 3 "SHED2_CONTIN" 2 "SHED2_TRANS" 1 "SHED1" 0 "NO_SHED" ;
VAL_ 1068 Batt_Lo_SoC_B 1 "Active" 0 "Inactive" ;
VAL_ 1068 PeriodicElLoad_B_Stat 1 "Active" 0 "Inactive" ;
VAL_ 1068 Batt_Crit_SoC_B 1 "Active" 0 "Inactive" ;
VAL_ 1068 ULoRgenTestMde_B_Rq 1 "Request" 0 "NoRequest" ;
VAL_ 1068 ChargeMode 7 "Undefined_2" 6 "Undefined_1" 5 "Battery_Identify" 4 "Battery_Refresh" 3 "SlowRegenAllowNoDischarge" 2 "Fast_Regen_Allowed" 1 "Slow_Regen_Allowed" 0 "Conventional_Charging" ;
VAL_ 1068 IdleSpeedIncrease_El 1 "Yes" 0 "No" ;
VAL_ 826 Memory_3_Sw_Stat 1 "Pressed" 0 "Null" ;
VAL_ 826 Memory_2_Sw_Stat 1 "Pressed" 0 "Null" ;
VAL_ 826 Memory_1_Sw_Stat 1 "Pressed" 0 "Null" ;
VAL_ 826 Mirror_Manual_Override 1 "Override" 0 "Null" ;
VAL_ 827 LghtAmbIntns_D2_Sns 3 "Faulty" 2 "High" 1 "Medium" 0 "Low" ;
VAL_ 827 SteClmnSwtchTlt_D_Stat 3 "Unused" 2 "Down" 1 "Up" 0 "Null" ;
VAL_ 827 SteClmnSwtchTel_D_Stat 3 "Unused" 2 "Rearward" 1 "Forward" 0 "Null" ;
VAL_ 827 LghtAmbIntns_D_Sns 3 "Faulty" 2 "High" 1 "Low" 0 "Null" ;
